VERSION "Version"

NS_ :

BS_:

BU_: ADC FR Tester

BO_ 537 FR_Obj_24: 32 FR
 SG_ SGU24_Msg_CheckSum_Can03 : 7|8@0+ (1,0) [0|255] ""  ADC
 SG_ SGU24_Msg_AliveCounter_Can03 : 11|4@0+ (1,0) [0|14] ""  ADC
 SG_ SGU24_BlockCounter_Can03 : 15|4@0+ (1,0) [0|15] ""  ADC
 SG_ SGU24_Object_ID_Can03 : 23|8@0+ (1,0) [0|255] ""  ADC
 SG_ SGU24_Object_wExist_Can03 : 28|5@0+ (0.03125,0) [0|0.96875] ""  ADC
 SG_ SGU24_Object_Type_Can03 : 31|3@0+ (1,0) [0|7] ""  ADC
 SG_ SGU24_Object_MotionPattern_Can03 : 34|3@0+ (1,0) [0|7] ""  ADC
 SG_ SGU24_Object_wObstacle_Can03 : 39|5@0+ (0.03125,0) [0|0.96875] ""  ADC
 SG_ SGU24_Object_dx_Nearest_Can03 : 44|13@0+ (0.0625,-255) [-255|254.9375] "m"  ADC
 SG_ SGU24_Object_dy_Nearest_Can03 : 59|12@0+ (0.125,-128) [-128|127.875] "m"  ADC
 SG_ SGU24_Object_DistLong_rms_Can03 : 79|16@0+ (0.001953125,0) [0|127.998046875] "m"  ADC
 SG_ SGU24_Obj_DistLat_rms_Can03 : 95|16@0+ (0.001953125,0) [0|127.998046875] "m"  ADC
 SG_ SGU24_Object_vx_Can03 : 107|12@0+ (0.0625,-128) [-128|127.9375] "m/s"  ADC
 SG_ SGU24_Object_vy_Can03 : 123|12@0+ (0.0625,-128) [-128|127.9375] "m/s"  ADC
 SG_ SGU24_Obj_VrelLong_rms_Can03 : 143|16@0+ (0.001953125,0) [0|127.998046875] "m/s"  ADC
 SG_ SGU24_Obj_Vrelat_rms_Can03 : 159|16@0+ (0.001953125,0) [0|127.998046875] "m/s"  ADC
 SG_ SGU24_Object_DetStatus_Can03 : 173|3@0+ (1,0) [0|7] ""  ADC
 SG_ SGU24_Object_ax_Can03 : 170|11@0+ (0.03125,-16) [-16|15.96875] "m/s^2"  ADC
 SG_ SGU24_Object_ay_Can03 : 191|11@0+ (0.03125,-16) [-16|15.96875] "m/s^2"  ADC
 SG_ SGU24_LifeCycles_OBJ_Can03 : 196|8@0+ (1,0) [0|255] ""  ADC
 SG_ SGU24_ObjRCS_24_Can03 : 204|10@0+ (0.125,-50) [-50|70] "dBm2"  ADC
 SG_ SGU24_Object_dx_Rear_Can03 : 210|13@0+ (0.0625,-255) [-255|254.9375] "m"  ADC
 SG_ SGU24_Object_dy_Rear_Can03 : 229|12@0+ (0.125,-128) [-128|127.875] "m"  ADC

BO_ 538 FR_Obj_25: 32 FR
 SG_ SGU25_Msg_CheckSum_Can03 : 7|8@0+ (1,0) [0|255] ""  ADC
 SG_ SGU25_Msg_AliveCounter_Can03 : 11|4@0+ (1,0) [0|14] ""  ADC
 SG_ SGU25_BlockCounter_Can03 : 15|4@0+ (1,0) [0|15] ""  ADC
 SG_ SGU25_Object_ID_Can03 : 23|8@0+ (1,0) [0|255] ""  ADC
 SG_ SGU25_Object_wExist_Can03 : 28|5@0+ (0.03125,0) [0|0.96875] ""  ADC
 SG_ SGU25_Object_Type_Can03 : 31|3@0+ (1,0) [0|7] ""  ADC
 SG_ SGU25_Object_MotionPattern_Can03 : 34|3@0+ (1,0) [0|7] ""  ADC
 SG_ SGU25_Object_wObstacle_Can03 : 39|5@0+ (0.03125,0) [0|0.96875] ""  ADC
 SG_ SGU25_Object_dx_Nearest_Can03 : 44|13@0+ (0.0625,-255) [-255|254.9375] "m"  ADC
 SG_ SGU25_Object_dy_Nearest_Can03 : 59|12@0+ (0.125,-128) [-128|127.875] "m"  ADC
 SG_ SGU25_Object_DistLong_rms_Can03 : 79|16@0+ (0.001953125,0) [0|127.998046875] "m"  ADC
 SG_ SGU25_Obj_DistLat_rms_Can03 : 95|16@0+ (0.001953125,0) [0|127.998046875] "m"  ADC
 SG_ SGU25_Object_vx_Can03 : 107|12@0+ (0.0625,-128) [-128|127.9375] "m/s"  ADC
 SG_ SGU25_Object_vy_Can03 : 123|12@0+ (0.0625,-128) [-128|127.9375] "m/s"  ADC
 SG_ SGU25_Obj_VrelLong_rms_Can03 : 143|16@0+ (0.001953125,0) [0|127.998046875] "m/s"  ADC
 SG_ SGU25_Obj_Vrelat_rms_Can03 : 159|16@0+ (0.001953125,0) [0|127.998046875] "m/s"  ADC
 SG_ SGU25_Object_DetStatus_Can03 : 173|3@0+ (1,0) [0|7] ""  ADC
 SG_ SGU25_Object_ax_Can03 : 170|11@0+ (0.03125,-16) [-16|15.96875] "m/s^2"  ADC
 SG_ SGU25_Object_ay_Can03 : 191|11@0+ (0.03125,-16) [-16|15.96875] "m/s^2"  ADC
 SG_ SGU25_LifeCycles_OBJ_Can03 : 196|8@0+ (1,0) [0|255] ""  ADC
 SG_ SGU25_ObjRCS_25_Can03 : 204|10@0+ (0.125,-50) [-50|70] "dBm2"  ADC
 SG_ SGU25_Object_dx_Rear_Can03 : 210|13@0+ (0.0625,-255) [-255|254.9375] "m"  ADC
 SG_ SGU25_Object_dy_Rear_Can03 : 229|12@0+ (0.125,-128) [-128|127.875] "m"  ADC

BO_ 539 FR_Obj_26: 32 FR
 SG_ SGU26_Msg_CheckSum_Can03 : 7|8@0+ (1,0) [0|255] ""  ADC
 SG_ SGU26_Msg_AliveCounter_Can03 : 11|4@0+ (1,0) [0|14] ""  ADC
 SG_ SGU26_BlockCounter_Can03 : 15|4@0+ (1,0) [0|15] ""  ADC
 SG_ SGU26_Object_ID_Can03 : 23|8@0+ (1,0) [0|255] ""  ADC
 SG_ SGU26_Object_wExist_Can03 : 28|5@0+ (0.03125,0) [0|0.96875] ""  ADC
 SG_ SGU26_Object_Type_Can03 : 31|3@0+ (1,0) [0|7] ""  ADC
 SG_ SGU26_Object_MotionPattern_Can03 : 34|3@0+ (1,0) [0|7] ""  ADC
 SG_ SGU26_Object_wObstacle_Can03 : 39|5@0+ (0.03125,0) [0|0.96875] ""  ADC
 SG_ SGU26_Object_dx_Nearest_Can03 : 44|13@0+ (0.0625,-255) [-255|254.9375] "m"  ADC
 SG_ SGU26_Object_dy_Nearest_Can03 : 59|12@0+ (0.125,-128) [-128|127.875] "m"  ADC
 SG_ SGU26_Object_DistLong_rms_Can03 : 79|16@0+ (0.001953125,0) [0|127.998046875] "m"  ADC
 SG_ SGU26_Obj_DistLat_rms_Can03 : 95|16@0+ (0.001953125,0) [0|127.998046875] "m"  ADC
 SG_ SGU26_Object_vx_Can03 : 107|12@0+ (0.0625,-128) [-128|127.9375] "m/s"  ADC
 SG_ SGU26_Object_vy_Can03 : 123|12@0+ (0.0625,-128) [-128|127.9375] "m/s"  ADC
 SG_ SGU26_Obj_VrelLong_rms_Can03 : 143|16@0+ (0.001953125,0) [0|127.998046875] "m/s"  ADC
 SG_ SGU26_Obj_Vrelat_rms_Can03 : 159|16@0+ (0.001953125,0) [0|127.998046875] "m/s"  ADC
 SG_ SGU26_Object_DetStatus_Can03 : 173|3@0+ (1,0) [0|7] ""  ADC
 SG_ SGU26_Object_ax_Can03 : 170|11@0+ (0.03125,-16) [-16|15.96875] "m/s^2"  ADC
 SG_ SGU26_Object_ay_Can03 : 191|11@0+ (0.03125,-16) [-16|15.96875] "m/s^2"  ADC
 SG_ SGU26_LifeCycles_OBJ_Can03 : 196|8@0+ (1,0) [0|255] ""  ADC
 SG_ SGU26_ObjRCS_26_Can03 : 204|10@0+ (0.125,-50) [-50|70] "dBm2"  ADC
 SG_ SGU26_Object_dx_Rear_Can03 : 210|13@0+ (0.0625,-255) [-255|254.9375] "m"  ADC
 SG_ SGU26_Object_dy_Rear_Can03 : 229|12@0+ (0.125,-128) [-128|127.875] "m"  ADC

BO_ 540 FR_Obj_27: 32 FR
 SG_ SGU27_Msg_CheckSum_Can03 : 7|8@0+ (1,0) [0|255] ""  ADC
 SG_ SGU27_Msg_AliveCounter_Can03 : 11|4@0+ (1,0) [0|14] ""  ADC
 SG_ SGU27_BlockCounter_Can03 : 15|4@0+ (1,0) [0|15] ""  ADC
 SG_ SGU27_Object_ID_Can03 : 23|8@0+ (1,0) [0|255] ""  ADC
 SG_ SGU27_Object_wExist_Can03 : 28|5@0+ (0.03125,0) [0|0.96875] ""  ADC
 SG_ SGU27_Object_Type_Can03 : 31|3@0+ (1,0) [0|7] ""  ADC
 SG_ SGU27_Object_MotionPattern_Can03 : 34|3@0+ (1,0) [0|7] ""  ADC
 SG_ SGU27_Object_wObstacle_Can03 : 39|5@0+ (0.03125,0) [0|0.96875] ""  ADC
 SG_ SGU27_Object_dx_Nearest_Can03 : 44|13@0+ (0.0625,-255) [-255|254.9375] "m"  ADC
 SG_ SGU27_Object_dy_Nearest_Can03 : 59|12@0+ (0.125,-128) [-128|127.875] "m"  ADC
 SG_ SGU27_Object_DistLong_rms_Can03 : 79|16@0+ (0.001953125,0) [0|127.998046875] "m"  ADC
 SG_ SGU27_Obj_DistLat_rms_Can03 : 95|16@0+ (0.001953125,0) [0|127.998046875] "m"  ADC
 SG_ SGU27_Object_vx_Can03 : 107|12@0+ (0.0625,-128) [-128|127.9375] "m/s"  ADC
 SG_ SGU27_Object_vy_Can03 : 123|12@0+ (0.0625,-128) [-128|127.9375] "m/s"  ADC
 SG_ SGU27_Obj_VrelLong_rms_Can03 : 143|16@0+ (0.001953125,0) [0|127.998046875] "m/s"  ADC
 SG_ SGU27_Obj_Vrelat_rms_Can03 : 159|16@0+ (0.001953125,0) [0|127.998046875] "m/s"  ADC
 SG_ SGU27_Object_DetStatus_Can03 : 173|3@0+ (1,0) [0|7] ""  ADC
 SG_ SGU27_Object_ax_Can03 : 170|11@0+ (0.03125,-16) [-16|15.96875] "m/s^2"  ADC
 SG_ SGU27_Object_ay_Can03 : 191|11@0+ (0.03125,-16) [-16|15.96875] "m/s^2"  ADC
 SG_ SGU27_LifeCycles_OBJ_Can03 : 196|8@0+ (1,0) [0|255] ""  ADC
 SG_ SGU27_ObjRCS_27_Can03 : 204|10@0+ (0.125,-50) [-50|70] "dBm2"  ADC
 SG_ SGU27_Object_dx_Rear_Can03 : 210|13@0+ (0.0625,-255) [-255|254.9375] "m"  ADC
 SG_ SGU27_Object_dy_Rear_Can03 : 229|12@0+ (0.125,-128) [-128|127.875] "m"  ADC

BO_ 541 FR_Obj_28: 32 FR
 SG_ SGU28_Msg_CheckSum_Can03 : 7|8@0+ (1,0) [0|255] ""  ADC
 SG_ SGU28_Msg_AliveCounter_Can03 : 11|4@0+ (1,0) [0|14] ""  ADC
 SG_ SGU28_BlockCounter_Can03 : 15|4@0+ (1,0) [0|15] ""  ADC
 SG_ SGU28_Object_ID_Can03 : 23|8@0+ (1,0) [0|255] ""  ADC
 SG_ SGU28_Object_wExist_Can03 : 28|5@0+ (0.03125,0) [0|0.96875] ""  ADC
 SG_ SGU28_Object_Type_Can03 : 31|3@0+ (1,0) [0|7] ""  ADC
 SG_ SGU28_Object_MotionPattern_Can03 : 34|3@0+ (1,0) [0|7] ""  ADC
 SG_ SGU28_Object_wObstacle_Can03 : 39|5@0+ (0.03125,0) [0|0.96875] ""  ADC
 SG_ SGU28_Object_dx_Nearest_Can03 : 44|13@0+ (0.0625,-255) [-255|254.9375] "m"  ADC
 SG_ SGU28_Object_dy_Nearest_Can03 : 59|12@0+ (0.125,-128) [-128|127.875] "m"  ADC
 SG_ SGU28_Object_DistLong_rms_Can03 : 79|16@0+ (0.001953125,0) [0|127.998046875] "m"  ADC
 SG_ SGU28_Obj_DistLat_rms_Can03 : 95|16@0+ (0.001953125,0) [0|127.998046875] "m"  ADC
 SG_ SGU28_Object_vx_Can03 : 107|12@0+ (0.0625,-128) [-128|127.9375] "m/s"  ADC
 SG_ SGU28_Object_vy_Can03 : 123|12@0+ (0.0625,-128) [-128|127.9375] "m/s"  ADC
 SG_ SGU28_Obj_VrelLong_rms_Can03 : 143|16@0+ (0.001953125,0) [0|127.998046875] "m/s"  ADC
 SG_ SGU28_Obj_Vrelat_rms_Can03 : 159|16@0+ (0.001953125,0) [0|127.998046875] "m/s"  ADC
 SG_ SGU28_Object_DetStatus_Can03 : 173|3@0+ (1,0) [0|7] ""  ADC
 SG_ SGU28_Object_ax_Can03 : 170|11@0+ (0.03125,-16) [-16|15.96875] "m/s^2"  ADC
 SG_ SGU28_Object_ay_Can03 : 191|11@0+ (0.03125,-16) [-16|15.96875] "m/s^2"  ADC
 SG_ SGU28_LifeCycles_OBJ_Can03 : 196|8@0+ (1,0) [0|255] ""  ADC
 SG_ SGU28_ObjRCS_28_Can03 : 204|10@0+ (0.125,-50) [-50|70] "dBm2"  ADC
 SG_ SGU28_Object_dx_Rear_Can03 : 210|13@0+ (0.0625,-255) [-255|254.9375] "m"  ADC
 SG_ SGU28_Object_dy_Rear_Can03 : 229|12@0+ (0.125,-128) [-128|127.875] "m"  ADC

BO_ 542 FR_Obj_29: 32 FR
 SG_ SGU29_Msg_CheckSum_Can03 : 7|8@0+ (1,0) [0|255] ""  ADC
 SG_ SGU29_Msg_AliveCounter_Can03 : 11|4@0+ (1,0) [0|14] ""  ADC
 SG_ SGU29_BlockCounter_Can03 : 15|4@0+ (1,0) [0|15] ""  ADC
 SG_ SGU29_Object_ID_Can03 : 23|8@0+ (1,0) [0|255] ""  ADC
 SG_ SGU29_Object_wExist_Can03 : 28|5@0+ (0.03125,0) [0|0.96875] ""  ADC
 SG_ SGU29_Object_Type_Can03 : 31|3@0+ (1,0) [0|7] ""  ADC
 SG_ SGU29_Object_MotionPattern_Can03 : 34|3@0+ (1,0) [0|7] ""  ADC
 SG_ SGU29_Object_wObstacle_Can03 : 39|5@0+ (0.03125,0) [0|0.96875] ""  ADC
 SG_ SGU29_Object_dx_Nearest_Can03 : 44|13@0+ (0.0625,-255) [-255|254.9375] "m"  ADC
 SG_ SGU29_Object_dy_Nearest_Can03 : 59|12@0+ (0.125,-128) [-128|127.875] "m"  ADC
 SG_ SGU29_Object_DistLong_rms_Can03 : 79|16@0+ (0.001953125,0) [0|127.998046875] "m"  ADC
 SG_ SGU29_Obj_DistLat_rms_Can03 : 95|16@0+ (0.001953125,0) [0|127.998046875] "m"  ADC
 SG_ SGU29_Object_vx_Can03 : 107|12@0+ (0.0625,-128) [-128|127.9375] "m/s"  ADC
 SG_ SGU29_Object_vy_Can03 : 123|12@0+ (0.0625,-128) [-128|127.9375] "m/s"  ADC
 SG_ SGU29_Obj_VrelLong_rms_Can03 : 143|16@0+ (0.001953125,0) [0|127.998046875] "m/s"  ADC
 SG_ SGU29_Obj_Vrelat_rms_Can03 : 159|16@0+ (0.001953125,0) [0|127.998046875] "m/s"  ADC
 SG_ SGU29_Object_DetStatus_Can03 : 173|3@0+ (1,0) [0|7] ""  ADC
 SG_ SGU29_Object_ax_Can03 : 170|11@0+ (0.03125,-16) [-16|15.96875] "m/s^2"  ADC
 SG_ SGU29_Object_ay_Can03 : 191|11@0+ (0.03125,-16) [-16|15.96875] "m/s^2"  ADC
 SG_ SGU29_LifeCycles_OBJ_Can03 : 196|8@0+ (1,0) [0|255] ""  ADC
 SG_ SGU29_ObjRCS_29_Can03 : 204|10@0+ (0.125,-50) [-50|70] "dBm2"  ADC
 SG_ SGU29_Object_dx_Rear_Can03 : 210|13@0+ (0.0625,-255) [-255|254.9375] "m"  ADC
 SG_ SGU29_Object_dy_Rear_Can03 : 229|12@0+ (0.125,-128) [-128|127.875] "m"  ADC

BO_ 543 FR_Obj_30: 32 FR
 SG_ SGU30_Msg_CheckSum_Can03 : 7|8@0+ (1,0) [0|255] ""  ADC
 SG_ SGU30_Msg_AliveCounter_Can03 : 11|4@0+ (1,0) [0|14] ""  ADC
 SG_ SGU30_BlockCounter_Can03 : 15|4@0+ (1,0) [0|15] ""  ADC
 SG_ SGU30_Object_ID_Can03 : 23|8@0+ (1,0) [0|255] ""  ADC
 SG_ SGU30_Object_wExist_Can03 : 28|5@0+ (0.03125,0) [0|0.96875] ""  ADC
 SG_ SGU30_Object_Type_Can03 : 31|3@0+ (1,0) [0|7] ""  ADC
 SG_ SGU30_Object_MotionPattern_Can03 : 34|3@0+ (1,0) [0|7] ""  ADC
 SG_ SGU30_Object_wObstacle_Can03 : 39|5@0+ (0.03125,0) [0|0.96875] ""  ADC
 SG_ SGU30_Object_dx_Nearest_Can03 : 44|13@0+ (0.0625,-255) [-255|254.9375] "m"  ADC
 SG_ SGU30_Object_dy_Nearest_Can03 : 59|12@0+ (0.125,-128) [-128|127.875] "m"  ADC
 SG_ SGU30_Object_DistLong_rms_Can03 : 79|16@0+ (0.001953125,0) [0|127.998046875] "m"  ADC
 SG_ SGU30_Obj_DistLat_rms_Can03 : 95|16@0+ (0.001953125,0) [0|127.998046875] "m"  ADC
 SG_ SGU30_Object_vx_Can03 : 107|12@0+ (0.0625,-128) [-128|127.9375] "m/s"  ADC
 SG_ SGU30_Object_vy_Can03 : 123|12@0+ (0.0625,-128) [-128|127.9375] "m/s"  ADC
 SG_ SGU30_Obj_VrelLong_rms_Can03 : 143|16@0+ (0.001953125,0) [0|127.998046875] "m/s"  ADC
 SG_ SGU30_Obj_Vrelat_rms_Can03 : 159|16@0+ (0.001953125,0) [0|127.998046875] "m/s"  ADC
 SG_ SGU30_Object_DetStatus_Can03 : 173|3@0+ (1,0) [0|7] ""  ADC
 SG_ SGU30_Object_ax_Can03 : 170|11@0+ (0.03125,-16) [-16|15.96875] "m/s^2"  ADC
 SG_ SGU30_Object_ay_Can03 : 191|11@0+ (0.03125,-16) [-16|15.96875] "m/s^2"  ADC
 SG_ SGU30_LifeCycles_OBJ_Can03 : 196|8@0+ (1,0) [0|255] ""  ADC
 SG_ SGU30_ObjRCS_30_Can03 : 204|10@0+ (0.125,-50) [-50|70] "dBm2"  ADC
 SG_ SGU30_Object_dx_Rear_Can03 : 210|13@0+ (0.0625,-255) [-255|254.9375] "m"  ADC
 SG_ SGU30_Object_dy_Rear_Can03 : 229|12@0+ (0.125,-128) [-128|127.875] "m"  ADC

BO_ 544 FR_Obj_31: 32 FR
 SG_ SGU31_Msg_CheckSum_Can03 : 7|8@0+ (1,0) [0|255] ""  ADC
 SG_ SGU31_Msg_AliveCounter_Can03 : 11|4@0+ (1,0) [0|14] ""  ADC
 SG_ SGU31_BlockCounter_Can03 : 15|4@0+ (1,0) [0|15] ""  ADC
 SG_ SGU31_Object_ID_Can03 : 23|8@0+ (1,0) [0|255] ""  ADC
 SG_ SGU31_Object_wExist_Can03 : 28|5@0+ (0.03125,0) [0|0.96875] ""  ADC
 SG_ SGU31_Object_Type_Can03 : 31|3@0+ (1,0) [0|7] ""  ADC
 SG_ SGU31_Object_MotionPattern_Can03 : 34|3@0+ (1,0) [0|7] ""  ADC
 SG_ SGU31_Object_wObstacle_Can03 : 39|5@0+ (0.03125,0) [0|0.96875] ""  ADC
 SG_ SGU31_Object_dx_Nearest_Can03 : 44|13@0+ (0.0625,-255) [-255|254.9375] "m"  ADC
 SG_ SGU31_Object_dy_Nearest_Can03 : 59|12@0+ (0.125,-128) [-128|127.875] "m"  ADC
 SG_ SGU31_Object_DistLong_rms_Can03 : 79|16@0+ (0.001953125,0) [0|127.998046875] "m"  ADC
 SG_ SGU31_Obj_DistLat_rms_Can03 : 95|16@0+ (0.001953125,0) [0|127.998046875] "m"  ADC
 SG_ SGU31_Object_vx_Can03 : 107|12@0+ (0.0625,-128) [-128|127.9375] "m/s"  ADC
 SG_ SGU31_Object_vy_Can03 : 123|12@0+ (0.0625,-128) [-128|127.9375] "m/s"  ADC
 SG_ SGU31_Obj_VrelLong_rms_Can03 : 143|16@0+ (0.001953125,0) [0|127.998046875] "m/s"  ADC
 SG_ SGU31_Obj_Vrelat_rms_Can03 : 159|16@0+ (0.001953125,0) [0|127.998046875] "m/s"  ADC
 SG_ SGU31_Object_DetStatus_Can03 : 173|3@0+ (1,0) [0|7] ""  ADC
 SG_ SGU31_Object_ax_Can03 : 170|11@0+ (0.03125,-16) [-16|15.96875] "m/s^2"  ADC
 SG_ SGU31_Object_ay_Can03 : 191|11@0+ (0.03125,-16) [-16|15.96875] "m/s^2"  ADC
 SG_ SGU31_LifeCycles_OBJ_Can03 : 196|8@0+ (1,0) [0|255] ""  ADC
 SG_ SGU31_ObjRCS_31_Can03 : 204|10@0+ (0.125,-50) [-50|70] "dBm2"  ADC
 SG_ SGU31_Object_dx_Rear_Can03 : 210|13@0+ (0.0625,-255) [-255|254.9375] "m"  ADC
 SG_ SGU31_Object_dy_Rear_Can03 : 229|12@0+ (0.125,-128) [-128|127.875] "m"  ADC

BO_ 545 FR_Obj_32: 32 FR
 SG_ SGU32_Msg_CheckSum_Can03 : 7|8@0+ (1,0) [0|255] ""  ADC
 SG_ SGU32_Msg_AliveCounter_Can03 : 11|4@0+ (1,0) [0|14] ""  ADC
 SG_ SGU32_BlockCounter_Can03 : 15|4@0+ (1,0) [0|15] ""  ADC
 SG_ SGU32_Object_ID_Can03 : 23|8@0+ (1,0) [0|255] ""  ADC
 SG_ SGU32_Object_wExist_Can03 : 28|5@0+ (0.03125,0) [0|0.96875] ""  ADC
 SG_ SGU32_Object_Type_Can03 : 31|3@0+ (1,0) [0|7] ""  ADC
 SG_ SGU32_Object_MotionPattern_Can03 : 34|3@0+ (1,0) [0|7] ""  ADC
 SG_ SGU32_Object_wObstacle_Can03 : 39|5@0+ (0.03125,0) [0|0.96875] ""  ADC
 SG_ SGU32_Object_dx_Nearest_Can03 : 44|13@0+ (0.0625,-255) [-255|254.9375] "m"  ADC
 SG_ SGU32_Object_dy_Nearest_Can03 : 59|12@0+ (0.125,-128) [-128|127.875] "m"  ADC
 SG_ SGU32_Object_DistLong_rms_Can03 : 79|16@0+ (0.001953125,0) [0|127.998046875] "m"  ADC
 SG_ SGU32_Obj_DistLat_rms_Can03 : 95|16@0+ (0.001953125,0) [0|127.998046875] "m"  ADC
 SG_ SGU32_Object_vx_Can03 : 107|12@0+ (0.0625,-128) [-128|127.9375] "m/s"  ADC
 SG_ SGU32_Object_vy_Can03 : 123|12@0+ (0.0625,-128) [-128|127.9375] "m/s"  ADC
 SG_ SGU32_Obj_VrelLong_rms_Can03 : 143|16@0+ (0.001953125,0) [0|127.998046875] "m/s"  ADC
 SG_ SGU32_Obj_Vrelat_rms_Can03 : 159|16@0+ (0.001953125,0) [0|127.998046875] "m/s"  ADC
 SG_ SGU32_Object_DetStatus_Can03 : 173|3@0+ (1,0) [0|7] ""  ADC
 SG_ SGU32_Object_ax_Can03 : 170|11@0+ (0.03125,-16) [-16|15.96875] "m/s^2"  ADC
 SG_ SGU32_Object_ay_Can03 : 191|11@0+ (0.03125,-16) [-16|15.96875] "m/s^2"  ADC
 SG_ SGU32_LifeCycles_OBJ_Can03 : 196|8@0+ (1,0) [0|255] ""  ADC
 SG_ SGU32_ObjRCS_32_Can03 : 204|10@0+ (0.125,-50) [-50|70] "dBm2"  ADC
 SG_ SGU32_Object_dx_Rear_Can03 : 210|13@0+ (0.0625,-255) [-255|254.9375] "m"  ADC
 SG_ SGU32_Object_dy_Rear_Can03 : 229|12@0+ (0.125,-128) [-128|127.875] "m"  ADC

BO_ 546 FR_RadarInfo: 32 FR
 SG_ FR_RadarInfor_Checksum_Can03 : 7|8@0+ (1,0) [0|255] ""  ADC
 SG_ FR_RadarInfor_AliveCounter_Can03 : 11|4@0+ (1,0) [0|14] ""  ADC
 SG_ mountAngleIndicator_az : 31|9@0+ (0.05,-12.8) [-12.8|12.75] "degree"  ADC
 SG_ mountAngleCurrent_az : 38|9@0+ (0.05,-12.8) [-12.8|12.75] "degree"  ADC
 SG_ mountAngleIndicator_el : 45|9@0+ (0.05,-12.8) [-12.8|12.75] "degree"  ADC
 SG_ mountAngleCurrent_el : 52|9@0+ (0.05,-12.8) [-12.8|12.75] "degree"  ADC
 SG_ malStablePosAz : 59|9@0+ (0.05,-12.8) [-12.8|12.75] "degree"  ADC
 SG_ malStablePosEl : 66|9@0+ (0.05,-12.8) [-12.8|12.75] "degree"  ADC
 SG_ AngleEMEIndicatorAz : 73|9@0+ (0.05,-12.8) [-12.8|12.75] "degree"  ADC
 SG_ AngleEMEIndicatorEl : 95|9@0+ (0.05,-12.8) [-12.8|12.75] "degree"  ADC
 SG_ FilteredPhiSpread : 102|11@0+ (0.1,-102.4) [-102.4|102.3] "m"  ADC
 SG_ highSpreadIndicator_el : 107|9@0+ (0.05,-12.8) [-12.8|12.75] "degree"  ADC
 SG_ highSpreadIndicator_az : 114|9@0+ (0.05,-12.8) [-12.8|12.75] "degree"  ADC
 SG_ elOutOfSpecCause : 129|2@0+ (1,0) [0|3] ""  ADC
 SG_ azOutOfSpecCause : 131|2@0+ (1,0) [0|3] ""  ADC
 SG_ Fault_MAL_HOR_ABS_EVENT : 132|1@0+ (1,0) [0|1] ""  ADC
 SG_ Fault_MAL_HOR_REL_EVENT : 133|1@0+ (1,0) [0|1] ""  ADC
 SG_ Fault_MAL_VER_ABS_EVENT : 134|1@0+ (1,0) [0|1] ""  ADC
 SG_ Fault_MAL_VER_REL_EVENT : 135|1@0+ (1,0) [0|1] ""  ADC
 SG_ azOutOfProfileCause : 143|8@0+ (1,0) [0|255] ""  ADC
 SG_ elOutOfProfileCause : 151|8@0+ (1,0) [0|255] ""  ADC
 SG_ FR_SW_Baseline_Can03 : 155|4@0+ (1,0) [0|15] ""  ADC
 SG_ FR_SW_ReleaseType_Can03 : 159|4@0+ (1,0) [0|15] ""  ADC
 SG_ FR_SW_MajorVersion_Can03 : 163|4@0+ (1,0) [0|15] ""  ADC
 SG_ FR_SW_MinorVersion_Can03 : 167|4@0+ (1,0) [0|15] ""  ADC
 SG_ FR_SDA_CalibrationSts_Can03 : 175|8@0+ (1,0) [0|255] ""  ADC
 SG_ FR_EOL_CalibrationSts_Can03 : 183|8@0+ (1,0) [0|255] ""  ADC
 SG_ FR_Blindness_FaultSts_Can03 : 192|1@0+ (1,0) [0|1] ""  ADC
 SG_ FR_ModulationSts_Can03 : 193|1@0+ (1,0) [0|1] ""  ADC
 SG_ FR_Misalignment_FaultSts_Can03 : 194|1@0+ (1,0) [0|1] ""  ADC
 SG_ FR_FAULT_HV_SERVICE_OOS_Can03 : 195|1@0+ (1,0) [0|1] ""  ADC
 SG_ FR_Radar_FaultSts_Can03 : 207|8@0+ (1,0) [0|31] ""  ADC
 SG_ FR_DTC_VBAT_HIGH_Can03 : 208|1@0+ (1,0) [0|1] ""  ADC
 SG_ FR_DTC_VBAT_LOW_Can03 : 209|1@0+ (1,0) [0|1] ""  ADC
 SG_ FR_DTC_HW_DEFECT_Can03 : 210|1@0+ (1,0) [0|1] ""  ADC
 SG_ FR_DTC_MRR_BLIND_Can03 : 212|1@0+ (1,0) [0|1] ""  ADC
 SG_ FR_DTC_MRR_MISALIGNED_Can03 : 213|1@0+ (1,0) [0|1] ""  ADC
 SG_ FR_DTC_VMC_FAILURE_Can03 : 214|1@0+ (1,0) [0|1] ""  ADC
 SG_ FR_DTC_DSP_FAILURE_Can03 : 215|1@0+ (1,0) [0|1] ""  ADC
 SG_ FR_DTC_RADAR_SIDE_MISMATCH_Can03 : 217|1@0+ (1,0) [0|1] ""  ADC
 SG_ FR_DTC_ALIGNMENT_NOT_DONE_Can03 : 218|1@0+ (1,0) [0|1] ""  ADC
 SG_ FR_DTC_PCAN_BUSOFF_Can03 : 219|1@0+ (1,0) [0|1] ""  ADC
 SG_ FR_DTC_LOST_COMM_EPS_Can03 : 222|1@0+ (1,0) [0|1] ""  ADC
 SG_ FR_DTC_INVALID_DATA_EPS_Can03 : 223|1@0+ (1,0) [0|1] ""  ADC
 SG_ FR_DTC_LOST_COMM_BCS_Can03 : 224|1@0+ (1,0) [0|1] ""  ADC
 SG_ FR_DTC_INVALID_DATA_BCS_Can03 : 225|1@0+ (1,0) [0|1] ""  ADC
 SG_ FR_DTC_LOST_COMM_CCU_Can03 : 226|1@0+ (1,0) [0|1] ""  ADC
 SG_ FR_DTC_INVALID_DATA_CCU_Can03 : 227|1@0+ (1,0) [0|1] ""  ADC
 SG_ FR_DTC_LOST_COMM_SOC_Can03 : 230|1@0+ (1,0) [0|1] ""  ADC
 SG_ FR_DTC_INVALID_DATA_SOC_Can03 : 231|1@0+ (1,0) [0|1] ""  ADC
 SG_ FR_DTC_ADC_TIME_SYNC_FAIL_Can03 : 232|1@0+ (1,0) [0|1] ""  ADC

BO_ 616 ADC_SOC_Time: 64 ADC
 SG_ UMM_UsageModeSt : 26|3@0+ (1,0) [0|7] ""  FR
 SG_ Time_Year : 343|8@0+ (1,2000) [2000|2255] "y"  FR
 SG_ Time_Month : 351|4@0+ (1,0) [1|12] "m"  FR
 SG_ Time_Hour : 358|5@0+ (1,0) [0|23] "h"  FR
 SG_ Time_Day : 347|5@0+ (1,0) [1|31] "d"  FR
 SG_ Time_Min : 353|6@0+ (1,0) [0|59] "min"  FR
 SG_ Time_Sec : 363|6@0+ (1,0) [0|59] "s"  FR

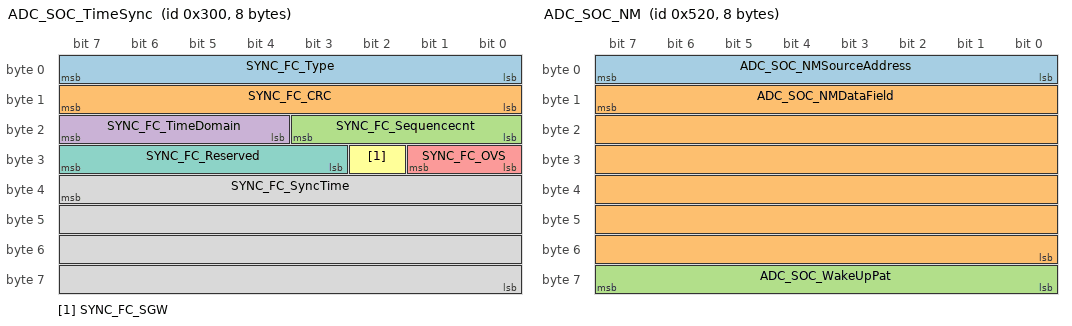
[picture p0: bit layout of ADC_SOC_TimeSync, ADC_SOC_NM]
BO_ 768 ADC_SOC_TimeSync: 8 ADC
 SG_ SYNC_FC_Type : 7|8@0+ (1,0) [0|255] ""  FR
 SG_ SYNC_FC_CRC : 15|8@0+ (1,0) [0|255] ""  FR
 SG_ SYNC_FC_Sequencecnt : 19|4@0+ (1,0) [0|15] ""  FR
 SG_ SYNC_FC_TimeDomain : 23|4@0+ (1,0) [0|15] ""  FR
 SG_ SYNC_FC_OVS : 25|2@0+ (1,0) [0|3] ""  FR
 SG_ SYNC_FC_SGW : 26|1@0+ (1,0) [0|1] ""  FR
 SG_ SYNC_FC_Reserved : 31|5@0+ (1,0) [0|31] ""  FR
 SG_ SYNC_FC_SyncTime : 39|32@0+ (1,0) [0|4294967295] ""  FR

BO_ 1238 FR_DiagCode: 64 FR
    SG_ FR_DTCCode : 7|512@0+ (1,0) [0|0] "" ADC

BO_ 1312 ADC_SOC_NM: 8 ADC
 SG_ ADC_SOC_NMSourceAddress : 7|8@0+ (1,0) [0|255] ""  FR
 SG_ ADC_SOC_NMDataField : 15|48@0+ (1,0) [0|255] ""  FR
 SG_ ADC_SOC_WakeUpPat : 63|8@0+ (1,0) [0|255] ""  FR

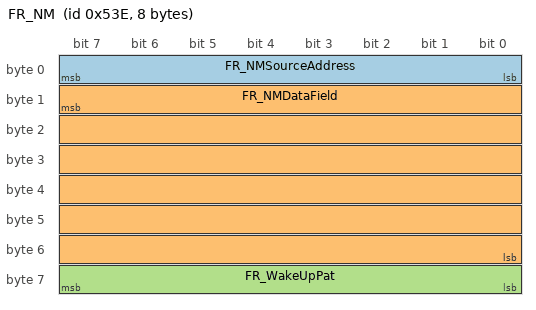
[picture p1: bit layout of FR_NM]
BO_ 1342 FR_NM: 8 FR
 SG_ FR_NMSourceAddress : 7|8@0+ (1,0) [0|255] ""  ADC
 SG_ FR_NMDataField : 15|48@0+ (1,0) [0|255] ""  ADC
 SG_ FR_WakeUpPat : 63|8@0+ (1,0) [0|255] ""  ADC

BO_ 1854 FR_Phys_Diag_Rx: 64 ADC
 SG_ FR_Diag_Request : 7|512@0+ (1,0) [0|18446744073709551615] "" Vector__XXX

BO_ 1982 FR_Diag_Tx: 64 FR
 SG_ FR_Diag_Response : 7|512@0+ (1,0) [0|18446744073709551615] "" ADC

BO_ 2015 Func_Diag_Rx: 64 ADC
 SG_ Func_Diag_Request : 7|512@0+ (1,0) [0|18446744073709551615] "" Vector__XXX

CM_ SG_ 537 SGU24_Msg_CheckSum_Can03 "E2E Profile Variant 1A CRC";
CM_ SG_ 537 SGU24_Msg_AliveCounter_Can03 "E2E Profile Variant 1A Counter";
CM_ SG_ 537 SGU24_BlockCounter_Can03 "Block counter for every messages";
CM_ SG_ 537 SGU24_Object_ID_Can03 "ID is an identifier number that allows for tracking of persistent objects over time";
CM_ SG_ 537 SGU24_Object_wExist_Can03 "Existence probability of the object";
CM_ SG_ 537 SGU24_Object_Type_Can03 "To indicate the estimated type of Object";
CM_ SG_ 537 SGU24_Object_MotionPattern_Can03 "Motion type of object";
CM_ SG_ 537 SGU24_Object_wObstacle_Can03 "The probability of an object being an obstacle";
CM_ SG_ 537 SGU24_Object_dx_Nearest_Can03 "Position of target object in x-direction [m]";
CM_ SG_ 537 SGU24_Object_dy_Nearest_Can03 "Nearest position of target object in y-direction [m]";
CM_ SG_ 537 SGU24_Object_DistLong_rms_Can03 "Standard deviation of longitudinal distance";
CM_ SG_ 537 SGU24_Obj_DistLat_rms_Can03 "Standard deviation of lateral distance";
CM_ SG_ 537 SGU24_Object_vx_Can03 "Relative target object velocity in x-direction [m/s]";
CM_ SG_ 537 SGU24_Object_vy_Can03 "Relative target object velocity in y-direction [m/s]";
CM_ SG_ 537 SGU24_Obj_VrelLong_rms_Can03 "Standard deviation of longitudinal relative velocity";
CM_ SG_ 537 SGU24_Obj_Vrelat_rms_Can03 "Standard deviation of lateral relative velocity";
CM_ SG_ 537 SGU24_Object_DetStatus_Can03 "Detection Staus Of Object";
CM_ SG_ 537 SGU24_Object_ax_Can03 "Relative target object acceleration in x-direction, in the vehicle coordinatesystem";
CM_ SG_ 537 SGU24_Object_ay_Can03 "Relative target object acceleration in y-direction, in the vehicle coordinate system";
CM_ SG_ 537 SGU24_LifeCycles_OBJ_Can03 "-";
CM_ SG_ 537 SGU24_ObjRCS_24_Can03 "Radar Cross Section (RCS) estimation";
CM_ SG_ 537 SGU24_Object_dx_Rear_Can03 "Position of target object rear bumper in x-direction [m]";
CM_ SG_ 537 SGU24_Object_dy_Rear_Can03 "Position of target object rear bumper in y-direction [m]";
CM_ SG_ 538 SGU25_Msg_CheckSum_Can03 "E2E Profile Variant 1A CRC";
CM_ SG_ 538 SGU25_Msg_AliveCounter_Can03 "E2E Profile Variant 1A Counter";
CM_ SG_ 538 SGU25_BlockCounter_Can03 "Block counter for every messages";
CM_ SG_ 538 SGU25_Object_ID_Can03 "ID is an identifier number that allows for tracking of persistent objects over time";
CM_ SG_ 538 SGU25_Object_wExist_Can03 "Existence probability of the object";
CM_ SG_ 538 SGU25_Object_Type_Can03 "To indicate the estimated type of Object";
CM_ SG_ 538 SGU25_Object_MotionPattern_Can03 "Motion type of object";
CM_ SG_ 538 SGU25_Object_wObstacle_Can03 "The probability of an object being an obstacle";
CM_ SG_ 538 SGU25_Object_dx_Nearest_Can03 "Position of target object in x-direction [m]";
CM_ SG_ 538 SGU25_Object_dy_Nearest_Can03 "Nearest position of target object in y-direction [m]";
CM_ SG_ 538 SGU25_Object_DistLong_rms_Can03 "Standard deviation of longitudinal distance";
CM_ SG_ 538 SGU25_Obj_DistLat_rms_Can03 "Standard deviation of lateral distance";
CM_ SG_ 538 SGU25_Object_vx_Can03 "Relative target object velocity in x-direction [m/s]";
CM_ SG_ 538 SGU25_Object_vy_Can03 "Relative target object velocity in y-direction [m/s]";
CM_ SG_ 538 SGU25_Obj_VrelLong_rms_Can03 "Standard deviation of longitudinal relative velocity";
CM_ SG_ 538 SGU25_Obj_Vrelat_rms_Can03 "Standard deviation of lateral relative velocity";
CM_ SG_ 538 SGU25_Object_DetStatus_Can03 "Detection Staus Of Object";
CM_ SG_ 538 SGU25_Object_ax_Can03 "Relative target object acceleration in x-direction, in the vehicle coordinatesystem";
CM_ SG_ 538 SGU25_Object_ay_Can03 "Relative target object acceleration in y-direction, in the vehicle coordinate system";
CM_ SG_ 538 SGU25_LifeCycles_OBJ_Can03 "-";
CM_ SG_ 538 SGU25_ObjRCS_25_Can03 "Radar Cross Section (RCS) estimation";
CM_ SG_ 538 SGU25_Object_dx_Rear_Can03 "Position of target object rear bumper in x-direction [m]";
CM_ SG_ 538 SGU25_Object_dy_Rear_Can03 "Position of target object rear bumper in y-direction [m]";
CM_ SG_ 539 SGU26_Msg_CheckSum_Can03 "E2E Profile Variant 1A CRC";
CM_ SG_ 539 SGU26_Msg_AliveCounter_Can03 "E2E Profile Variant 1A Counter";
CM_ SG_ 539 SGU26_BlockCounter_Can03 "Block counter for every messages";
CM_ SG_ 539 SGU26_Object_ID_Can03 "ID is an identifier number that allows for tracking of persistent objects over time";
CM_ SG_ 539 SGU26_Object_wExist_Can03 "Existence probability of the object";
CM_ SG_ 539 SGU26_Object_Type_Can03 "To indicate the estimated type of Object";
CM_ SG_ 539 SGU26_Object_MotionPattern_Can03 "Motion type of object";
CM_ SG_ 539 SGU26_Object_wObstacle_Can03 "The probability of an object being an obstacle";
CM_ SG_ 539 SGU26_Object_dx_Nearest_Can03 "Position of target object in x-direction [m]";
CM_ SG_ 539 SGU26_Object_dy_Nearest_Can03 "Nearest position of target object in y-direction [m]";
CM_ SG_ 539 SGU26_Object_DistLong_rms_Can03 "Standard deviation of longitudinal distance";
CM_ SG_ 539 SGU26_Obj_DistLat_rms_Can03 "Standard deviation of lateral distance";
CM_ SG_ 539 SGU26_Object_vx_Can03 "Relative target object velocity in x-direction [m/s]";
CM_ SG_ 539 SGU26_Object_vy_Can03 "Relative target object velocity in y-direction [m/s]";
CM_ SG_ 539 SGU26_Obj_VrelLong_rms_Can03 "Standard deviation of longitudinal relative velocity";
CM_ SG_ 539 SGU26_Obj_Vrelat_rms_Can03 "Standard deviation of lateral relative velocity";
CM_ SG_ 539 SGU26_Object_DetStatus_Can03 "Detection Staus Of Object";
CM_ SG_ 539 SGU26_Object_ax_Can03 "Relative target object acceleration in x-direction, in the vehicle coordinatesystem";
CM_ SG_ 539 SGU26_Object_ay_Can03 "Relative target object acceleration in y-direction, in the vehicle coordinate system";
CM_ SG_ 539 SGU26_LifeCycles_OBJ_Can03 "-";
CM_ SG_ 539 SGU26_ObjRCS_26_Can03 "Radar Cross Section (RCS) estimation";
CM_ SG_ 539 SGU26_Object_dx_Rear_Can03 "Position of target object rear bumper in x-direction [m]";
CM_ SG_ 539 SGU26_Object_dy_Rear_Can03 "Position of target object rear bumper in y-direction [m]";
CM_ SG_ 540 SGU27_Msg_CheckSum_Can03 "E2E Profile Variant 1A CRC";
CM_ SG_ 540 SGU27_Msg_AliveCounter_Can03 "E2E Profile Variant 1A Counter";
CM_ SG_ 540 SGU27_BlockCounter_Can03 "Block counter for every messages";
CM_ SG_ 540 SGU27_Object_ID_Can03 "ID is an identifier number that allows for tracking of persistent objects over time";
CM_ SG_ 540 SGU27_Object_wExist_Can03 "Existence probability of the object";
CM_ SG_ 540 SGU27_Object_Type_Can03 "To indicate the estimated type of Object";
CM_ SG_ 540 SGU27_Object_MotionPattern_Can03 "Motion type of object";
CM_ SG_ 540 SGU27_Object_wObstacle_Can03 "The probability of an object being an obstacle";
CM_ SG_ 540 SGU27_Object_dx_Nearest_Can03 "Position of target object in x-direction [m]";
CM_ SG_ 540 SGU27_Object_dy_Nearest_Can03 "Nearest position of target object in y-direction [m]";
CM_ SG_ 540 SGU27_Object_DistLong_rms_Can03 "Standard deviation of longitudinal distance";
CM_ SG_ 540 SGU27_Obj_DistLat_rms_Can03 "Standard deviation of lateral distance";
CM_ SG_ 540 SGU27_Object_vx_Can03 "Relative target object velocity in x-direction [m/s]";
CM_ SG_ 540 SGU27_Object_vy_Can03 "Relative target object velocity in y-direction [m/s]";
CM_ SG_ 540 SGU27_Obj_VrelLong_rms_Can03 "Standard deviation of longitudinal relative velocity";
CM_ SG_ 540 SGU27_Obj_Vrelat_rms_Can03 "Standard deviation of lateral relative velocity";
CM_ SG_ 540 SGU27_Object_DetStatus_Can03 "Detection Staus Of Object";
CM_ SG_ 540 SGU27_Object_ax_Can03 "Relative target object acceleration in x-direction, in the vehicle coordinatesystem";
CM_ SG_ 540 SGU27_Object_ay_Can03 "Relative target object acceleration in y-direction, in the vehicle coordinate system";
CM_ SG_ 540 SGU27_LifeCycles_OBJ_Can03 "-";
CM_ SG_ 540 SGU27_ObjRCS_27_Can03 "Radar Cross Section (RCS) estimation";
CM_ SG_ 540 SGU27_Object_dx_Rear_Can03 "Position of target object rear bumper in x-direction [m]";
CM_ SG_ 540 SGU27_Object_dy_Rear_Can03 "Position of target object rear bumper in y-direction [m]";
CM_ SG_ 541 SGU28_Msg_CheckSum_Can03 "E2E Profile Variant 1A CRC";
CM_ SG_ 541 SGU28_Msg_AliveCounter_Can03 "E2E Profile Variant 1A Counter";
CM_ SG_ 541 SGU28_BlockCounter_Can03 "Block counter for every messages";
CM_ SG_ 541 SGU28_Object_ID_Can03 "ID is an identifier number that allows for tracking of persistent objects over time";
CM_ SG_ 541 SGU28_Object_wExist_Can03 "Existence probability of the object";
CM_ SG_ 541 SGU28_Object_Type_Can03 "To indicate the estimated type of Object";
CM_ SG_ 541 SGU28_Object_MotionPattern_Can03 "Motion type of object";
CM_ SG_ 541 SGU28_Object_wObstacle_Can03 "The probability of an object being an obstacle";
CM_ SG_ 541 SGU28_Object_dx_Nearest_Can03 "Position of target object in x-direction [m]";
CM_ SG_ 541 SGU28_Object_dy_Nearest_Can03 "Nearest position of target object in y-direction [m]";
CM_ SG_ 541 SGU28_Object_DistLong_rms_Can03 "Standard deviation of longitudinal distance";
CM_ SG_ 541 SGU28_Obj_DistLat_rms_Can03 "Standard deviation of lateral distance";
CM_ SG_ 541 SGU28_Object_vx_Can03 "Relative target object velocity in x-direction [m/s]";
CM_ SG_ 541 SGU28_Object_vy_Can03 "Relative target object velocity in y-direction [m/s]";
CM_ SG_ 541 SGU28_Obj_VrelLong_rms_Can03 "Standard deviation of longitudinal relative velocity";
CM_ SG_ 541 SGU28_Obj_Vrelat_rms_Can03 "Standard deviation of lateral relative velocity";
CM_ SG_ 541 SGU28_Object_DetStatus_Can03 "Detection Staus Of Object";
CM_ SG_ 541 SGU28_Object_ax_Can03 "Relative target object acceleration in x-direction, in the vehicle coordinatesystem";
CM_ SG_ 541 SGU28_Object_ay_Can03 "Relative target object acceleration in y-direction, in the vehicle coordinate system";
CM_ SG_ 541 SGU28_LifeCycles_OBJ_Can03 "-";
CM_ SG_ 541 SGU28_ObjRCS_28_Can03 "Radar Cross Section (RCS) estimation";
CM_ SG_ 541 SGU28_Object_dx_Rear_Can03 "Position of target object rear bumper in x-direction [m]";
CM_ SG_ 541 SGU28_Object_dy_Rear_Can03 "Position of target object rear bumper in y-direction [m]";
CM_ SG_ 542 SGU29_Msg_CheckSum_Can03 "E2E Profile Variant 1A CRC";
CM_ SG_ 542 SGU29_Msg_AliveCounter_Can03 "E2E Profile Variant 1A Counter";
CM_ SG_ 542 SGU29_BlockCounter_Can03 "Block counter for every messages";
CM_ SG_ 542 SGU29_Object_ID_Can03 "ID is an identifier number that allows for tracking of persistent objects over time";
CM_ SG_ 542 SGU29_Object_wExist_Can03 "Existence probability of the object";
CM_ SG_ 542 SGU29_Object_Type_Can03 "To indicate the estimated type of Object";
CM_ SG_ 542 SGU29_Object_MotionPattern_Can03 "Motion type of object";
CM_ SG_ 542 SGU29_Object_wObstacle_Can03 "The probability of an object being an obstacle";
CM_ SG_ 542 SGU29_Object_dx_Nearest_Can03 "Position of target object in x-direction [m]";
CM_ SG_ 542 SGU29_Object_dy_Nearest_Can03 "Nearest position of target object in y-direction [m]";
CM_ SG_ 542 SGU29_Object_DistLong_rms_Can03 "Standard deviation of longitudinal distance";
CM_ SG_ 542 SGU29_Obj_DistLat_rms_Can03 "Standard deviation of lateral distance";
CM_ SG_ 542 SGU29_Object_vx_Can03 "Relative target object velocity in x-direction [m/s]";
CM_ SG_ 542 SGU29_Object_vy_Can03 "Relative target object velocity in y-direction [m/s]";
CM_ SG_ 542 SGU29_Obj_VrelLong_rms_Can03 "Standard deviation of longitudinal relative velocity";
CM_ SG_ 542 SGU29_Obj_Vrelat_rms_Can03 "Standard deviation of lateral relative velocity";
CM_ SG_ 542 SGU29_Object_DetStatus_Can03 "Detection Staus Of Object";
CM_ SG_ 542 SGU29_Object_ax_Can03 "Relative target object acceleration in x-direction, in the vehicle coordinatesystem";
CM_ SG_ 542 SGU29_Object_ay_Can03 "Relative target object acceleration in y-direction, in the vehicle coordinate system";
CM_ SG_ 542 SGU29_LifeCycles_OBJ_Can03 "-";
CM_ SG_ 542 SGU29_ObjRCS_29_Can03 "Radar Cross Section (RCS) estimation";
CM_ SG_ 542 SGU29_Object_dx_Rear_Can03 "Position of target object rear bumper in x-direction [m]";
CM_ SG_ 542 SGU29_Object_dy_Rear_Can03 "Position of target object rear bumper in y-direction [m]";
CM_ SG_ 543 SGU30_Msg_CheckSum_Can03 "E2E Profile Variant 1A CRC";
CM_ SG_ 543 SGU30_Msg_AliveCounter_Can03 "E2E Profile Variant 1A Counter";
CM_ SG_ 543 SGU30_BlockCounter_Can03 "Block counter for every messages";
CM_ SG_ 543 SGU30_Object_ID_Can03 "ID is an identifier number that allows for tracking of persistent objects over time";
CM_ SG_ 543 SGU30_Object_wExist_Can03 "Existence probability of the object";
CM_ SG_ 543 SGU30_Object_Type_Can03 "To indicate the estimated type of Object";
CM_ SG_ 543 SGU30_Object_MotionPattern_Can03 "Motion type of object";
CM_ SG_ 543 SGU30_Object_wObstacle_Can03 "The probability of an object being an obstacle";
CM_ SG_ 543 SGU30_Object_dx_Nearest_Can03 "Position of target object in x-direction [m]";
CM_ SG_ 543 SGU30_Object_dy_Nearest_Can03 "Nearest position of target object in y-direction [m]";
CM_ SG_ 543 SGU30_Object_DistLong_rms_Can03 "Standard deviation of longitudinal distance";
CM_ SG_ 543 SGU30_Obj_DistLat_rms_Can03 "Standard deviation of lateral distance";
CM_ SG_ 543 SGU30_Object_vx_Can03 "Relative target object velocity in x-direction [m/s]";
CM_ SG_ 543 SGU30_Object_vy_Can03 "Relative target object velocity in y-direction [m/s]";
CM_ SG_ 543 SGU30_Obj_VrelLong_rms_Can03 "Standard deviation of longitudinal relative velocity";
CM_ SG_ 543 SGU30_Obj_Vrelat_rms_Can03 "Standard deviation of lateral relative velocity";
CM_ SG_ 543 SGU30_Object_DetStatus_Can03 "Detection Staus Of Object";
CM_ SG_ 543 SGU30_Object_ax_Can03 "Relative target object acceleration in x-direction, in the vehicle coordinatesystem";
CM_ SG_ 543 SGU30_Object_ay_Can03 "Relative target object acceleration in y-direction, in the vehicle coordinate system";
CM_ SG_ 543 SGU30_LifeCycles_OBJ_Can03 "-";
CM_ SG_ 543 SGU30_ObjRCS_30_Can03 "Radar Cross Section (RCS) estimation";
CM_ SG_ 543 SGU30_Object_dx_Rear_Can03 "Position of target object rear bumper in x-direction [m]";
CM_ SG_ 543 SGU30_Object_dy_Rear_Can03 "Position of target object rear bumper in y-direction [m]";
CM_ SG_ 544 SGU31_Msg_CheckSum_Can03 "E2E Profile Variant 1A CRC";
CM_ SG_ 544 SGU31_Msg_AliveCounter_Can03 "E2E Profile Variant 1A Counter";
CM_ SG_ 544 SGU31_BlockCounter_Can03 "Block counter for every messages";
CM_ SG_ 544 SGU31_Object_ID_Can03 "ID is an identifier number that allows for tracking of persistent objects over time";
CM_ SG_ 544 SGU31_Object_wExist_Can03 "Existence probability of the object";
CM_ SG_ 544 SGU31_Object_Type_Can03 "To indicate the estimated type of Object";
CM_ SG_ 544 SGU31_Object_MotionPattern_Can03 "Motion type of object";
CM_ SG_ 544 SGU31_Object_wObstacle_Can03 "The probability of an object being an obstacle";
CM_ SG_ 544 SGU31_Object_dx_Nearest_Can03 "Position of target object in x-direction [m]";
CM_ SG_ 544 SGU31_Object_dy_Nearest_Can03 "Nearest position of target object in y-direction [m]";
CM_ SG_ 544 SGU31_Object_DistLong_rms_Can03 "Standard deviation of longitudinal distance";
CM_ SG_ 544 SGU31_Obj_DistLat_rms_Can03 "Standard deviation of lateral distance";
CM_ SG_ 544 SGU31_Object_vx_Can03 "Relative target object velocity in x-direction [m/s]";
CM_ SG_ 544 SGU31_Object_vy_Can03 "Relative target object velocity in y-direction [m/s]";
CM_ SG_ 544 SGU31_Obj_VrelLong_rms_Can03 "Standard deviation of longitudinal relative velocity";
CM_ SG_ 544 SGU31_Obj_Vrelat_rms_Can03 "Standard deviation of lateral relative velocity";
CM_ SG_ 544 SGU31_Object_DetStatus_Can03 "Detection Staus Of Object";
CM_ SG_ 544 SGU31_Object_ax_Can03 "Relative target object acceleration in x-direction, in the vehicle coordinatesystem";
CM_ SG_ 544 SGU31_Object_ay_Can03 "Relative target object acceleration in y-direction, in the vehicle coordinate system";
CM_ SG_ 544 SGU31_LifeCycles_OBJ_Can03 "-";
CM_ SG_ 544 SGU31_ObjRCS_31_Can03 "Radar Cross Section (RCS) estimation";
CM_ SG_ 544 SGU31_Object_dx_Rear_Can03 "Position of target object rear bumper in x-direction [m]";
CM_ SG_ 544 SGU31_Object_dy_Rear_Can03 "Position of target object rear bumper in y-direction [m]";
CM_ SG_ 545 SGU32_Msg_CheckSum_Can03 "E2E Profile Variant 1A CRC";
CM_ SG_ 545 SGU32_Msg_AliveCounter_Can03 "E2E Profile Variant 1A Counter";
CM_ SG_ 545 SGU32_BlockCounter_Can03 "Block counter for every messages";
CM_ SG_ 545 SGU32_Object_ID_Can03 "ID is an identifier number that allows for tracking of persistent objects over time";
CM_ SG_ 545 SGU32_Object_wExist_Can03 "Existence probability of the object";
CM_ SG_ 545 SGU32_Object_Type_Can03 "To indicate the estimated type of Object";
CM_ SG_ 545 SGU32_Object_MotionPattern_Can03 "Motion type of object";
CM_ SG_ 545 SGU32_Object_wObstacle_Can03 "The probability of an object being an obstacle";
CM_ SG_ 545 SGU32_Object_dx_Nearest_Can03 "Position of target object in x-direction [m]";
CM_ SG_ 545 SGU32_Object_dy_Nearest_Can03 "Nearest position of target object in y-direction [m]";
CM_ SG_ 545 SGU32_Object_DistLong_rms_Can03 "Standard deviation of longitudinal distance";
CM_ SG_ 545 SGU32_Obj_DistLat_rms_Can03 "Standard deviation of lateral distance";
CM_ SG_ 545 SGU32_Object_vx_Can03 "Relative target object velocity in x-direction [m/s]";
CM_ SG_ 545 SGU32_Object_vy_Can03 "Relative target object velocity in y-direction [m/s]";
CM_ SG_ 545 SGU32_Obj_VrelLong_rms_Can03 "Standard deviation of longitudinal relative velocity";
CM_ SG_ 545 SGU32_Obj_Vrelat_rms_Can03 "Standard deviation of lateral relative velocity";
CM_ SG_ 545 SGU32_Object_DetStatus_Can03 "Detection Staus Of Object";
CM_ SG_ 545 SGU32_Object_ax_Can03 "Relative target object acceleration in x-direction, in the vehicle coordinatesystem";
CM_ SG_ 545 SGU32_Object_ay_Can03 "Relative target object acceleration in y-direction, in the vehicle coordinate system";
CM_ SG_ 545 SGU32_LifeCycles_OBJ_Can03 "-";
CM_ SG_ 545 SGU32_ObjRCS_32_Can03 "Radar Cross Section (RCS) estimation";
CM_ SG_ 545 SGU32_Object_dx_Rear_Can03 "Position of target object rear bumper in x-direction [m]";
CM_ SG_ 545 SGU32_Object_dy_Rear_Can03 "Position of target object rear bumper in y-direction [m]";
CM_ SG_ 546 FR_RadarInfor_Checksum_Can03 "E2E Profile Variant 1A CRC";
CM_ SG_ 546 FR_RadarInfor_AliveCounter_Can03 "E2E Profile Variant 1A Counter";
CM_ SG_ 546 mountAngleIndicator_az "mountAngleIndicator_az";
CM_ SG_ 546 mountAngleCurrent_az "mountAngleCurrent_az";
CM_ SG_ 546 mountAngleIndicator_el "mountAngleIndicator_el";
CM_ SG_ 546 mountAngleCurrent_el "mountAngleCurrent_el";
CM_ SG_ 546 malStablePosAz "malStablePosAz";
CM_ SG_ 546 malStablePosEl "malStablePosEl";
CM_ SG_ 546 AngleEMEIndicatorAz "AngleEMEIndicatorAz";
CM_ SG_ 546 AngleEMEIndicatorEl "AngleEMEIndicatorEl";
CM_ SG_ 546 FilteredPhiSpread "FilteredPhiSpread";
CM_ SG_ 546 highSpreadIndicator_el "highSpreadIndicator_el";
CM_ SG_ 546 highSpreadIndicator_az "highSpreadIndicator_az";
CM_ SG_ 546 elOutOfSpecCause "elOutOfSpecCause";
CM_ SG_ 546 azOutOfSpecCause "azOutOfSpecCause";
CM_ SG_ 546 Fault_MAL_HOR_ABS_EVENT "Fault_MAL_HOR_ABS_EVENT";
CM_ SG_ 546 Fault_MAL_HOR_REL_EVENT "Fault_MAL_HOR_REL_EVENT";
CM_ SG_ 546 Fault_MAL_VER_ABS_EVENT "Fault_MAL_VER_ABS_EVENT";
CM_ SG_ 546 Fault_MAL_VER_REL_EVENT "Fault_MAL_VER_REL_EVENT";
CM_ SG_ 546 azOutOfProfileCause "azOutOfProfileCause";
CM_ SG_ 546 elOutOfProfileCause "elOutOfProfileCause";
CM_ SG_ 546 FR_SW_Baseline_Can03 "Baseline of SWExample:BL09 V1.2,FR_SW_Baseline_Can03 = 9";
CM_ SG_ 546 FR_SW_ReleaseType_Can03 "ReleaseType of SWExample:BL09 V1.2,FR_SW_ReleaseType_Can03 = 0";
CM_ SG_ 546 FR_SW_MajorVersion_Can03 "Major Version of SWExample: V1.2, FR_SW_MajorVersion_Can03 = 1";
CM_ SG_ 546 FR_SW_MinorVersion_Can03 "Minor Version of SWExample:BL09 V1.2, FR_SW_MinorVersion_Can03 = 2";
CM_ SG_ 546 FR_SDA_CalibrationSts_Can03 "SDA Calibration Status";
CM_ SG_ 546 FR_EOL_CalibrationSts_Can03 "EOL Calibration Status";
CM_ SG_ 546 FR_Blindness_FaultSts_Can03 "Blindness Fault Status";
CM_ SG_ 546 FR_ModulationSts_Can03 "Modulation Status";
CM_ SG_ 546 FR_Misalignment_FaultSts_Can03 "Misalignment Fault Status";
CM_ SG_ 546 FR_FAULT_HV_SERVICE_OOS_Can03 "FAULT_HV_SERVICE_OOS Fault Status";
CM_ SG_ 546 FR_Radar_FaultSts_Can03 "Radar Fault Status";
CM_ SG_ 546 FR_DTC_VBAT_HIGH_Can03 "DTC_VBAT_HIGH";
CM_ SG_ 546 FR_DTC_VBAT_LOW_Can03 "DTC_VBAT_LOW";
CM_ SG_ 546 FR_DTC_HW_DEFECT_Can03 "DTC_HW_DEFECT";
CM_ SG_ 546 FR_DTC_MRR_BLIND_Can03 "DTC_MRR_BLIND";
CM_ SG_ 546 FR_DTC_MRR_MISALIGNED_Can03 "DTC_MRR_MISALIGNED";
CM_ SG_ 546 FR_DTC_VMC_FAILURE_Can03 "DTC_VMC_FAILURE";
CM_ SG_ 546 FR_DTC_DSP_FAILURE_Can03 "DTC_DSP_FAILURE";
CM_ SG_ 546 FR_DTC_RADAR_SIDE_MISMATCH_Can03 "DTC_RADAR_SIDE_MISMATCH";
CM_ SG_ 546 FR_DTC_ALIGNMENT_NOT_DONE_Can03 "DTC_ALIGNMENT_NOT_DONE";
CM_ SG_ 546 FR_DTC_PCAN_BUSOFF_Can03 "DTC_PCAN_BUSOFF";
CM_ SG_ 546 FR_DTC_LOST_COMM_EPS_Can03 "DTC_LOST_COMM_EPS";
CM_ SG_ 546 FR_DTC_INVALID_DATA_EPS_Can03 "DTC_INVALID_DATA_FROM_EPS";
CM_ SG_ 546 FR_DTC_LOST_COMM_BCS_Can03 "DTC_LOST_COMM_BCS";
CM_ SG_ 546 FR_DTC_INVALID_DATA_BCS_Can03 "DTC_INVALID_DATA_FROM_BCS";
CM_ SG_ 546 FR_DTC_LOST_COMM_CCU_Can03 "DTC_LOST_COMM_CCU";
CM_ SG_ 546 FR_DTC_INVALID_DATA_CCU_Can03 "DTC_INVALID_DATA_FROM_CCU";
CM_ SG_ 546 FR_DTC_LOST_COMM_SOC_Can03 "DTC_LOST_COMM_SOC";
CM_ SG_ 546 FR_DTC_INVALID_DATA_SOC_Can03 "DTC_INVALID_DATA_FROM_SOC";
CM_ SG_ 546 FR_DTC_ADC_TIME_SYNC_FAIL_Can03 "DTC_ADC_TIME_SYNC_FAIL";
CM_ SG_ 616 UMM_UsageModeSt "Usage mode state";
CM_ SG_ 616 Time_Year "Year number";
CM_ SG_ 616 Time_Month "Month number";
CM_ SG_ 616 Time_Hour "Hour number";
CM_ SG_ 616 Time_Day "Day number";
CM_ SG_ 616 Time_Min "Minute number";
CM_ SG_ 616 Time_Sec "Second number";
CM_ SG_ 768 SYNC_FC_Type "Type=0x20:TsyncType=0x28:Tsync FUP";
CM_ SG_ 768 SYNC_FC_CRC "CRC";
CM_ SG_ 768 SYNC_FC_Sequencecnt "Sequence counter";
CM_ SG_ 768 SYNC_FC_TimeDomain "Time Domain";
CM_ SG_ 768 SYNC_FC_OVS "In FUP PDUOVS=Overflow of seconds";
CM_ SG_ 768 SYNC_FC_SGW "In FUP PDUSyncToGTM=0SyncToSubDomain=1";
CM_ SG_ 768 SYNC_FC_Reserved "In FUP PDUReserved default=0";
CM_ SG_ 768 SYNC_FC_SyncTime "Tsync:SyncTimeSec=32bit LSB of the 48 bits seconds part timeTsync FUP:Sync TimeNSec=32 bit value in nanosconds";
CM_ SG_ 1312 ADC_SOC_NMSourceAddress "NM source address ";
CM_ SG_ 1312 ADC_SOC_NMDataField "NM data field ";
CM_ SG_ 1312 ADC_SOC_WakeUpPat "Wake-up pattern wake-up ";
CM_ SG_ 1342 FR_NMSourceAddress "NM source address ";
CM_ SG_ 1342 FR_NMDataField "NM data field ";
CM_ SG_ 1342 FR_WakeUpPat "Wake-up pattern wake-up ";
CM_ SG_ 1854 FR_Diag_Request "Diagnostic physical request";
CM_ SG_ 1982 FR_Diag_Response "Diagnostic response";
CM_ SG_ 2015 Func_Diag_Request "Diagnostic functional request";
BA_DEF_ BO_  "GenMsgCycleTime" INT 0 65535;
BA_DEF_ BO_  "GenMsgCycleTimeFast" INT 0 65535;
BA_DEF_ BO_  "GenMsgILSupport" ENUM  "No","Yes";
BA_DEF_ BO_  "GenMsgSendType" ENUM  "Cyclic","Event","CE","NotUsed","NotUsed","NotUsed","NotUsed","NotUsed","NoMsgSendType","IfActive","IfActiveWithRepetition","CyclicAndSpontanX";
BA_DEF_ BO_  "MsgType" ENUM  "Normal","NM","Diag","vector_leerstring";
BA_DEF_ BO_  "NmAsrMessage" ENUM  "No","Yes";
BA_DEF_ BO_  "VFrameFormat" ENUM  "StandardCAN","ExtendedCAN","reserved","reserved","reserved","reserved","reserved","reserved","reserved","reserved","reserved","reserved","reserved","reserved","StandardCAN_FD","ExtendedCAN_FD";
BA_DEF_ SG_  "GenSigInactiveValue" INT 0 2147483647;
BA_DEF_ SG_  "GenSigSendType" ENUM  "Cyclic","OnWrite","OnWriteWithRepetition","OnChange","OnChangeWithRepetition","IfActive","IfActiveWithRepetition","NoSigSendType","CyclicAndSpontanX","NotUsed","Event","CE";
BA_DEF_ SG_  "GenSigStartValue" INT 0 2147483647;
BA_DEF_ SG_  "Internal_type" ENUM  "*","UB","UW","UL","SB","SW","SL";
BA_DEF_ SG_  "IsCrcSignal" ENUM  "No","Yes";
BA_DEF_ SG_  "IsMonitor" ENUM  "*","Monitor";
BA_DEF_ SG_  "Remark" STRING ;
BA_DEF_ SG_  "SigInvalidSetFlag" ENUM  "*","Yes";
BA_DEF_ SG_  "UnitConversionFactor" FLOAT -100 100;
BA_DEF_ BO_  "CANFD_BRS" ENUM  "0","1";
BA_DEF_ SG_  "EventCommandSignal" ENUM  "No","Yes";
BA_DEF_ SG_  "GatewayedSignals" ENUM  "No","Yes";
BA_DEF_ SG_  "GenSigInvalidValue" HEX 0 0;
BA_DEF_ SG_  "GenSigTimeoutValue" HEX 0 0;
BA_DEF_DEF_  "GenMsgCycleTime" 0;
BA_DEF_DEF_  "GenMsgCycleTimeFast" 0;
BA_DEF_DEF_  "GenMsgILSupport" "Yes";
BA_DEF_DEF_  "GenMsgSendType" "Cyclic";
BA_DEF_DEF_  "GenSigInactiveValue" 0;
BA_DEF_DEF_  "GenSigSendType" "Cyclic";
BA_DEF_DEF_  "GenSigStartValue" 0;
BA_DEF_DEF_  "Internal_type" "*";
BA_DEF_DEF_  "IsCrcSignal" "No";
BA_DEF_DEF_  "IsMonitor" "*";
BA_DEF_DEF_  "MsgType" "";
BA_DEF_DEF_  "NmAsrMessage" "No";
BA_DEF_DEF_  "Remark" "";
BA_DEF_DEF_  "SigInvalidSetFlag" "*";
BA_DEF_DEF_  "UnitConversionFactor" 1;
BA_DEF_DEF_  "VFrameFormat" "StandardCAN";
BA_ "CANFD_BRS" BO_ 1312 1;
BA_ "CANFD_BRS" BO_ 1342 1;
BA_ "CANFD_BRS" BO_ 1854 1;
BA_ "CANFD_BRS" BO_ 1982 1;
BA_ "CANFD_BRS" BO_ 2015 1;
BA_ "CANFD_BRS" BO_ 537 1;
BA_ "CANFD_BRS" BO_ 538 1;
BA_ "CANFD_BRS" BO_ 539 1;
BA_ "CANFD_BRS" BO_ 540 1;
BA_ "CANFD_BRS" BO_ 541 1;
BA_ "CANFD_BRS" BO_ 542 1;
BA_ "CANFD_BRS" BO_ 543 1;
BA_ "CANFD_BRS" BO_ 544 1;
BA_ "CANFD_BRS" BO_ 545 1;
BA_ "CANFD_BRS" BO_ 546 1;
BA_ "CANFD_BRS" BO_ 616 1;
BA_ "CANFD_BRS" BO_ 768 1;
BA_ "GenMsgCycleTime" BO_ 1312 200;
BA_ "GenMsgCycleTime" BO_ 1342 200;
BA_ "GenMsgCycleTime" BO_ 546 50;
BA_ "GenMsgCycleTime" BO_ 616 20;
BA_ "GenMsgCycleTime" BO_ 768 500;
BA_ "GenMsgILSupport" BO_ 1238 0;
BA_ "GenMsgILSupport" BO_ 1342 0;
BA_ "GenMsgILSupport" BO_ 1854 0;
BA_ "GenMsgILSupport" BO_ 1982 0;
BA_ "GenMsgILSupport" BO_ 2015 0;
BA_ "GenMsgILSupport" BO_ 768 0;
BA_ "GenMsgSendType" BO_ 1238 8;
BA_ "GenMsgSendType" BO_ 1854 1;
BA_ "GenMsgSendType" BO_ 1982 1;
BA_ "GenMsgSendType" BO_ 2015 1;
BA_ "GenMsgSendType" BO_ 537 1;
BA_ "GenMsgSendType" BO_ 538 1;
BA_ "GenMsgSendType" BO_ 539 1;
BA_ "GenMsgSendType" BO_ 540 1;
BA_ "GenMsgSendType" BO_ 541 1;
BA_ "GenMsgSendType" BO_ 542 1;
BA_ "GenMsgSendType" BO_ 543 1;
BA_ "GenMsgSendType" BO_ 544 1;
BA_ "GenMsgSendType" BO_ 545 1;
BA_ "MsgType" BO_ 1238 0;
BA_ "MsgType" BO_ 1312 0;
BA_ "MsgType" BO_ 1342 0;
BA_ "MsgType" BO_ 1854 0;
BA_ "MsgType" BO_ 1982 0;
BA_ "MsgType" BO_ 2015 0;
BA_ "MsgType" BO_ 537 0;
BA_ "MsgType" BO_ 538 0;
BA_ "MsgType" BO_ 539 0;
BA_ "MsgType" BO_ 540 0;
BA_ "MsgType" BO_ 541 0;
BA_ "MsgType" BO_ 542 0;
BA_ "MsgType" BO_ 543 0;
BA_ "MsgType" BO_ 544 0;
BA_ "MsgType" BO_ 545 0;
BA_ "MsgType" BO_ 546 0;
BA_ "MsgType" BO_ 616 0;
BA_ "MsgType" BO_ 768 0;
BA_ "NmAsrMessage" BO_ 1312 1;
BA_ "NmAsrMessage" BO_ 1342 1;
BA_ "EventCommandSignal" SG_ 1312 ADC_SOC_NMDataField 0;
BA_ "GatewayedSignals" SG_ 1312 ADC_SOC_NMDataField 0;
BA_ "GenSigInvalidValue" SG_ 1312 ADC_SOC_NMDataField 0;
BA_ "GenSigSendType" SG_ 1312 ADC_SOC_NMDataField 1;
BA_ "GenSigTimeoutValue" SG_ 1312 ADC_SOC_NMDataField 0;
BA_ "EventCommandSignal" SG_ 1312 ADC_SOC_NMSourceAddress 0;
BA_ "GatewayedSignals" SG_ 1312 ADC_SOC_NMSourceAddress 0;
BA_ "GenSigInvalidValue" SG_ 1312 ADC_SOC_NMSourceAddress 0;
BA_ "GenSigSendType" SG_ 1312 ADC_SOC_NMSourceAddress 1;
BA_ "GenSigStartValue" SG_ 1312 ADC_SOC_NMSourceAddress 32;
BA_ "GenSigTimeoutValue" SG_ 1312 ADC_SOC_NMSourceAddress 0;
BA_ "EventCommandSignal" SG_ 1312 ADC_SOC_WakeUpPat 0;
BA_ "GatewayedSignals" SG_ 1312 ADC_SOC_WakeUpPat 0;
BA_ "GenSigInvalidValue" SG_ 1312 ADC_SOC_WakeUpPat 0;
BA_ "GenSigSendType" SG_ 1312 ADC_SOC_WakeUpPat 1;
BA_ "GenSigStartValue" SG_ 1312 ADC_SOC_WakeUpPat 76;
BA_ "GenSigTimeoutValue" SG_ 1312 ADC_SOC_WakeUpPat 0;
BA_ "EventCommandSignal" SG_ 1342 FR_NMDataField 0;
BA_ "GatewayedSignals" SG_ 1342 FR_NMDataField 0;
BA_ "GenSigInvalidValue" SG_ 1342 FR_NMDataField 0;
BA_ "GenSigSendType" SG_ 1342 FR_NMDataField 1;
BA_ "GenSigTimeoutValue" SG_ 1342 FR_NMDataField 0;
BA_ "EventCommandSignal" SG_ 1342 FR_NMSourceAddress 0;
BA_ "GatewayedSignals" SG_ 1342 FR_NMSourceAddress 0;
BA_ "GenSigInvalidValue" SG_ 1342 FR_NMSourceAddress 0;
BA_ "GenSigSendType" SG_ 1342 FR_NMSourceAddress 1;
BA_ "GenSigStartValue" SG_ 1342 FR_NMSourceAddress 62;
BA_ "GenSigTimeoutValue" SG_ 1342 FR_NMSourceAddress 0;
BA_ "EventCommandSignal" SG_ 1342 FR_WakeUpPat 0;
BA_ "GatewayedSignals" SG_ 1342 FR_WakeUpPat 0;
BA_ "GenSigInvalidValue" SG_ 1342 FR_WakeUpPat 0;
BA_ "GenSigSendType" SG_ 1342 FR_WakeUpPat 1;
BA_ "GenSigStartValue" SG_ 1342 FR_WakeUpPat 76;
BA_ "GenSigTimeoutValue" SG_ 1342 FR_WakeUpPat 0;
BA_ "EventCommandSignal" SG_ 1854 FR_Diag_Request 0;
BA_ "GatewayedSignals" SG_ 1854 FR_Diag_Request 0;
BA_ "GenSigInvalidValue" SG_ 1854 FR_Diag_Request 0;
BA_ "GenSigSendType" SG_ 1854 FR_Diag_Request 1;
BA_ "GenSigTimeoutValue" SG_ 1854 FR_Diag_Request 0;
BA_ "EventCommandSignal" SG_ 1982 FR_Diag_Response 0;
BA_ "GatewayedSignals" SG_ 1982 FR_Diag_Response 0;
BA_ "GenSigInvalidValue" SG_ 1982 FR_Diag_Response 0;
BA_ "GenSigSendType" SG_ 1982 FR_Diag_Response 10;
BA_ "GenSigTimeoutValue" SG_ 1982 FR_Diag_Response 0;
BA_ "EventCommandSignal" SG_ 2015 Func_Diag_Request 0;
BA_ "GatewayedSignals" SG_ 2015 Func_Diag_Request 0;
BA_ "GenSigInvalidValue" SG_ 2015 Func_Diag_Request 0;
BA_ "GenSigSendType" SG_ 2015 Func_Diag_Request 1;
BA_ "GenSigTimeoutValue" SG_ 2015 Func_Diag_Request 0;
BA_ "EventCommandSignal" SG_ 537 SGU24_BlockCounter_Can03 0;
BA_ "GatewayedSignals" SG_ 537 SGU24_BlockCounter_Can03 0;
BA_ "GenSigInvalidValue" SG_ 537 SGU24_BlockCounter_Can03 0;
BA_ "GenSigSendType" SG_ 537 SGU24_BlockCounter_Can03 10;
BA_ "GenSigTimeoutValue" SG_ 537 SGU24_BlockCounter_Can03 0;
BA_ "EventCommandSignal" SG_ 537 SGU24_LifeCycles_OBJ_Can03 0;
BA_ "GatewayedSignals" SG_ 537 SGU24_LifeCycles_OBJ_Can03 0;
BA_ "GenSigInvalidValue" SG_ 537 SGU24_LifeCycles_OBJ_Can03 0;
BA_ "GenSigSendType" SG_ 537 SGU24_LifeCycles_OBJ_Can03 10;
BA_ "GenSigTimeoutValue" SG_ 537 SGU24_LifeCycles_OBJ_Can03 0;
BA_ "EventCommandSignal" SG_ 537 SGU24_Msg_AliveCounter_Can03 0;
BA_ "GatewayedSignals" SG_ 537 SGU24_Msg_AliveCounter_Can03 0;
BA_ "GenSigInvalidValue" SG_ 537 SGU24_Msg_AliveCounter_Can03 0;
BA_ "GenSigSendType" SG_ 537 SGU24_Msg_AliveCounter_Can03 10;
BA_ "GenSigTimeoutValue" SG_ 537 SGU24_Msg_AliveCounter_Can03 0;
BA_ "EventCommandSignal" SG_ 537 SGU24_Msg_CheckSum_Can03 0;
BA_ "GatewayedSignals" SG_ 537 SGU24_Msg_CheckSum_Can03 0;
BA_ "GenSigInvalidValue" SG_ 537 SGU24_Msg_CheckSum_Can03 0;
BA_ "GenSigSendType" SG_ 537 SGU24_Msg_CheckSum_Can03 10;
BA_ "GenSigTimeoutValue" SG_ 537 SGU24_Msg_CheckSum_Can03 0;
BA_ "IsCrcSignal" SG_ 537 SGU24_Msg_CheckSum_Can03 1;
BA_ "EventCommandSignal" SG_ 537 SGU24_ObjRCS_24_Can03 0;
BA_ "GatewayedSignals" SG_ 537 SGU24_ObjRCS_24_Can03 0;
BA_ "GenSigInvalidValue" SG_ 537 SGU24_ObjRCS_24_Can03 0;
BA_ "GenSigSendType" SG_ 537 SGU24_ObjRCS_24_Can03 10;
BA_ "GenSigTimeoutValue" SG_ 537 SGU24_ObjRCS_24_Can03 0;
BA_ "EventCommandSignal" SG_ 537 SGU24_Obj_DistLat_rms_Can03 0;
BA_ "GatewayedSignals" SG_ 537 SGU24_Obj_DistLat_rms_Can03 0;
BA_ "GenSigInvalidValue" SG_ 537 SGU24_Obj_DistLat_rms_Can03 0;
BA_ "GenSigSendType" SG_ 537 SGU24_Obj_DistLat_rms_Can03 10;
BA_ "GenSigTimeoutValue" SG_ 537 SGU24_Obj_DistLat_rms_Can03 0;
BA_ "EventCommandSignal" SG_ 537 SGU24_Obj_VrelLong_rms_Can03 0;
BA_ "GatewayedSignals" SG_ 537 SGU24_Obj_VrelLong_rms_Can03 0;
BA_ "GenSigInvalidValue" SG_ 537 SGU24_Obj_VrelLong_rms_Can03 0;
BA_ "GenSigSendType" SG_ 537 SGU24_Obj_VrelLong_rms_Can03 10;
BA_ "GenSigTimeoutValue" SG_ 537 SGU24_Obj_VrelLong_rms_Can03 0;
BA_ "EventCommandSignal" SG_ 537 SGU24_Obj_Vrelat_rms_Can03 0;
BA_ "GatewayedSignals" SG_ 537 SGU24_Obj_Vrelat_rms_Can03 0;
BA_ "GenSigInvalidValue" SG_ 537 SGU24_Obj_Vrelat_rms_Can03 0;
BA_ "GenSigSendType" SG_ 537 SGU24_Obj_Vrelat_rms_Can03 10;
BA_ "GenSigTimeoutValue" SG_ 537 SGU24_Obj_Vrelat_rms_Can03 0;
BA_ "EventCommandSignal" SG_ 537 SGU24_Object_DetStatus_Can03 0;
BA_ "GatewayedSignals" SG_ 537 SGU24_Object_DetStatus_Can03 0;
BA_ "GenSigInvalidValue" SG_ 537 SGU24_Object_DetStatus_Can03 0;
BA_ "GenSigSendType" SG_ 537 SGU24_Object_DetStatus_Can03 10;
BA_ "GenSigTimeoutValue" SG_ 537 SGU24_Object_DetStatus_Can03 0;
BA_ "EventCommandSignal" SG_ 537 SGU24_Object_DistLong_rms_Can03 0;
BA_ "GatewayedSignals" SG_ 537 SGU24_Object_DistLong_rms_Can03 0;
BA_ "GenSigInvalidValue" SG_ 537 SGU24_Object_DistLong_rms_Can03 0;
BA_ "GenSigSendType" SG_ 537 SGU24_Object_DistLong_rms_Can03 10;
BA_ "GenSigTimeoutValue" SG_ 537 SGU24_Object_DistLong_rms_Can03 0;
BA_ "EventCommandSignal" SG_ 537 SGU24_Object_ID_Can03 0;
BA_ "GatewayedSignals" SG_ 537 SGU24_Object_ID_Can03 0;
BA_ "GenSigInvalidValue" SG_ 537 SGU24_Object_ID_Can03 0;
BA_ "GenSigSendType" SG_ 537 SGU24_Object_ID_Can03 10;
BA_ "GenSigTimeoutValue" SG_ 537 SGU24_Object_ID_Can03 0;
BA_ "EventCommandSignal" SG_ 537 SGU24_Object_MotionPattern_Can03 0;
BA_ "GatewayedSignals" SG_ 537 SGU24_Object_MotionPattern_Can03 0;
BA_ "GenSigInvalidValue" SG_ 537 SGU24_Object_MotionPattern_Can03 0;
BA_ "GenSigSendType" SG_ 537 SGU24_Object_MotionPattern_Can03 10;
BA_ "GenSigTimeoutValue" SG_ 537 SGU24_Object_MotionPattern_Can03 0;
BA_ "EventCommandSignal" SG_ 537 SGU24_Object_Type_Can03 0;
BA_ "GatewayedSignals" SG_ 537 SGU24_Object_Type_Can03 0;
BA_ "GenSigInvalidValue" SG_ 537 SGU24_Object_Type_Can03 0;
BA_ "GenSigSendType" SG_ 537 SGU24_Object_Type_Can03 10;
BA_ "GenSigTimeoutValue" SG_ 537 SGU24_Object_Type_Can03 0;
BA_ "EventCommandSignal" SG_ 537 SGU24_Object_ax_Can03 0;
BA_ "GatewayedSignals" SG_ 537 SGU24_Object_ax_Can03 0;
BA_ "GenSigInvalidValue" SG_ 537 SGU24_Object_ax_Can03 0;
BA_ "GenSigSendType" SG_ 537 SGU24_Object_ax_Can03 10;
BA_ "GenSigTimeoutValue" SG_ 537 SGU24_Object_ax_Can03 0;
BA_ "EventCommandSignal" SG_ 537 SGU24_Object_ay_Can03 0;
BA_ "GatewayedSignals" SG_ 537 SGU24_Object_ay_Can03 0;
BA_ "GenSigInvalidValue" SG_ 537 SGU24_Object_ay_Can03 0;
BA_ "GenSigSendType" SG_ 537 SGU24_Object_ay_Can03 10;
BA_ "GenSigTimeoutValue" SG_ 537 SGU24_Object_ay_Can03 0;
BA_ "EventCommandSignal" SG_ 537 SGU24_Object_dx_Nearest_Can03 0;
BA_ "GatewayedSignals" SG_ 537 SGU24_Object_dx_Nearest_Can03 0;
BA_ "GenSigInvalidValue" SG_ 537 SGU24_Object_dx_Nearest_Can03 0;
BA_ "GenSigSendType" SG_ 537 SGU24_Object_dx_Nearest_Can03 1;
BA_ "GenSigTimeoutValue" SG_ 537 SGU24_Object_dx_Nearest_Can03 0;
BA_ "EventCommandSignal" SG_ 537 SGU24_Object_dx_Rear_Can03 0;
BA_ "GatewayedSignals" SG_ 537 SGU24_Object_dx_Rear_Can03 0;
BA_ "GenSigInvalidValue" SG_ 537 SGU24_Object_dx_Rear_Can03 0;
BA_ "GenSigSendType" SG_ 537 SGU24_Object_dx_Rear_Can03 10;
BA_ "GenSigTimeoutValue" SG_ 537 SGU24_Object_dx_Rear_Can03 0;
BA_ "EventCommandSignal" SG_ 537 SGU24_Object_dy_Nearest_Can03 0;
BA_ "GatewayedSignals" SG_ 537 SGU24_Object_dy_Nearest_Can03 0;
BA_ "GenSigInvalidValue" SG_ 537 SGU24_Object_dy_Nearest_Can03 0;
BA_ "GenSigSendType" SG_ 537 SGU24_Object_dy_Nearest_Can03 1;
BA_ "GenSigTimeoutValue" SG_ 537 SGU24_Object_dy_Nearest_Can03 0;
BA_ "EventCommandSignal" SG_ 537 SGU24_Object_dy_Rear_Can03 0;
BA_ "GatewayedSignals" SG_ 537 SGU24_Object_dy_Rear_Can03 0;
BA_ "GenSigInvalidValue" SG_ 537 SGU24_Object_dy_Rear_Can03 0;
BA_ "GenSigSendType" SG_ 537 SGU24_Object_dy_Rear_Can03 10;
BA_ "GenSigTimeoutValue" SG_ 537 SGU24_Object_dy_Rear_Can03 0;
BA_ "EventCommandSignal" SG_ 537 SGU24_Object_vx_Can03 0;
BA_ "GatewayedSignals" SG_ 537 SGU24_Object_vx_Can03 0;
BA_ "GenSigInvalidValue" SG_ 537 SGU24_Object_vx_Can03 0;
BA_ "GenSigSendType" SG_ 537 SGU24_Object_vx_Can03 10;
BA_ "GenSigTimeoutValue" SG_ 537 SGU24_Object_vx_Can03 0;
BA_ "EventCommandSignal" SG_ 537 SGU24_Object_vy_Can03 0;
BA_ "GatewayedSignals" SG_ 537 SGU24_Object_vy_Can03 0;
BA_ "GenSigInvalidValue" SG_ 537 SGU24_Object_vy_Can03 0;
BA_ "GenSigSendType" SG_ 537 SGU24_Object_vy_Can03 10;
BA_ "GenSigTimeoutValue" SG_ 537 SGU24_Object_vy_Can03 0;
BA_ "EventCommandSignal" SG_ 537 SGU24_Object_wExist_Can03 0;
BA_ "GatewayedSignals" SG_ 537 SGU24_Object_wExist_Can03 0;
BA_ "GenSigInvalidValue" SG_ 537 SGU24_Object_wExist_Can03 0;
BA_ "GenSigSendType" SG_ 537 SGU24_Object_wExist_Can03 10;
BA_ "GenSigTimeoutValue" SG_ 537 SGU24_Object_wExist_Can03 0;
BA_ "EventCommandSignal" SG_ 537 SGU24_Object_wObstacle_Can03 0;
BA_ "GatewayedSignals" SG_ 537 SGU24_Object_wObstacle_Can03 0;
BA_ "GenSigInvalidValue" SG_ 537 SGU24_Object_wObstacle_Can03 0;
BA_ "GenSigSendType" SG_ 537 SGU24_Object_wObstacle_Can03 10;
BA_ "GenSigTimeoutValue" SG_ 537 SGU24_Object_wObstacle_Can03 0;
BA_ "EventCommandSignal" SG_ 538 SGU25_BlockCounter_Can03 0;
BA_ "GatewayedSignals" SG_ 538 SGU25_BlockCounter_Can03 0;
BA_ "GenSigInvalidValue" SG_ 538 SGU25_BlockCounter_Can03 0;
BA_ "GenSigSendType" SG_ 538 SGU25_BlockCounter_Can03 10;
BA_ "GenSigTimeoutValue" SG_ 538 SGU25_BlockCounter_Can03 0;
BA_ "EventCommandSignal" SG_ 538 SGU25_LifeCycles_OBJ_Can03 0;
BA_ "GatewayedSignals" SG_ 538 SGU25_LifeCycles_OBJ_Can03 0;
BA_ "GenSigInvalidValue" SG_ 538 SGU25_LifeCycles_OBJ_Can03 0;
BA_ "GenSigSendType" SG_ 538 SGU25_LifeCycles_OBJ_Can03 10;
BA_ "GenSigTimeoutValue" SG_ 538 SGU25_LifeCycles_OBJ_Can03 0;
BA_ "EventCommandSignal" SG_ 538 SGU25_Msg_AliveCounter_Can03 0;
BA_ "GatewayedSignals" SG_ 538 SGU25_Msg_AliveCounter_Can03 0;
BA_ "GenSigInvalidValue" SG_ 538 SGU25_Msg_AliveCounter_Can03 0;
BA_ "GenSigSendType" SG_ 538 SGU25_Msg_AliveCounter_Can03 10;
BA_ "GenSigTimeoutValue" SG_ 538 SGU25_Msg_AliveCounter_Can03 0;
BA_ "EventCommandSignal" SG_ 538 SGU25_Msg_CheckSum_Can03 0;
BA_ "GatewayedSignals" SG_ 538 SGU25_Msg_CheckSum_Can03 0;
BA_ "GenSigInvalidValue" SG_ 538 SGU25_Msg_CheckSum_Can03 0;
BA_ "GenSigSendType" SG_ 538 SGU25_Msg_CheckSum_Can03 10;
BA_ "GenSigTimeoutValue" SG_ 538 SGU25_Msg_CheckSum_Can03 0;
BA_ "IsCrcSignal" SG_ 538 SGU25_Msg_CheckSum_Can03 1;
BA_ "EventCommandSignal" SG_ 538 SGU25_ObjRCS_25_Can03 0;
BA_ "GatewayedSignals" SG_ 538 SGU25_ObjRCS_25_Can03 0;
BA_ "GenSigInvalidValue" SG_ 538 SGU25_ObjRCS_25_Can03 0;
BA_ "GenSigSendType" SG_ 538 SGU25_ObjRCS_25_Can03 10;
BA_ "GenSigTimeoutValue" SG_ 538 SGU25_ObjRCS_25_Can03 0;
BA_ "EventCommandSignal" SG_ 538 SGU25_Obj_DistLat_rms_Can03 0;
BA_ "GatewayedSignals" SG_ 538 SGU25_Obj_DistLat_rms_Can03 0;
BA_ "GenSigInvalidValue" SG_ 538 SGU25_Obj_DistLat_rms_Can03 0;
BA_ "GenSigSendType" SG_ 538 SGU25_Obj_DistLat_rms_Can03 10;
BA_ "GenSigTimeoutValue" SG_ 538 SGU25_Obj_DistLat_rms_Can03 0;
BA_ "EventCommandSignal" SG_ 538 SGU25_Obj_VrelLong_rms_Can03 0;
BA_ "GatewayedSignals" SG_ 538 SGU25_Obj_VrelLong_rms_Can03 0;
BA_ "GenSigInvalidValue" SG_ 538 SGU25_Obj_VrelLong_rms_Can03 0;
BA_ "GenSigSendType" SG_ 538 SGU25_Obj_VrelLong_rms_Can03 10;
BA_ "GenSigTimeoutValue" SG_ 538 SGU25_Obj_VrelLong_rms_Can03 0;
BA_ "EventCommandSignal" SG_ 538 SGU25_Obj_Vrelat_rms_Can03 0;
BA_ "GatewayedSignals" SG_ 538 SGU25_Obj_Vrelat_rms_Can03 0;
BA_ "GenSigInvalidValue" SG_ 538 SGU25_Obj_Vrelat_rms_Can03 0;
BA_ "GenSigSendType" SG_ 538 SGU25_Obj_Vrelat_rms_Can03 10;
BA_ "GenSigTimeoutValue" SG_ 538 SGU25_Obj_Vrelat_rms_Can03 0;
BA_ "EventCommandSignal" SG_ 538 SGU25_Object_DetStatus_Can03 0;
BA_ "GatewayedSignals" SG_ 538 SGU25_Object_DetStatus_Can03 0;
BA_ "GenSigInvalidValue" SG_ 538 SGU25_Object_DetStatus_Can03 0;
BA_ "GenSigSendType" SG_ 538 SGU25_Object_DetStatus_Can03 10;
BA_ "GenSigTimeoutValue" SG_ 538 SGU25_Object_DetStatus_Can03 0;
BA_ "EventCommandSignal" SG_ 538 SGU25_Object_DistLong_rms_Can03 0;
BA_ "GatewayedSignals" SG_ 538 SGU25_Object_DistLong_rms_Can03 0;
BA_ "GenSigInvalidValue" SG_ 538 SGU25_Object_DistLong_rms_Can03 0;
BA_ "GenSigSendType" SG_ 538 SGU25_Object_DistLong_rms_Can03 10;
BA_ "GenSigTimeoutValue" SG_ 538 SGU25_Object_DistLong_rms_Can03 0;
BA_ "EventCommandSignal" SG_ 538 SGU25_Object_ID_Can03 0;
BA_ "GatewayedSignals" SG_ 538 SGU25_Object_ID_Can03 0;
BA_ "GenSigInvalidValue" SG_ 538 SGU25_Object_ID_Can03 0;
BA_ "GenSigSendType" SG_ 538 SGU25_Object_ID_Can03 10;
BA_ "GenSigTimeoutValue" SG_ 538 SGU25_Object_ID_Can03 0;
BA_ "EventCommandSignal" SG_ 538 SGU25_Object_MotionPattern_Can03 0;
BA_ "GatewayedSignals" SG_ 538 SGU25_Object_MotionPattern_Can03 0;
BA_ "GenSigInvalidValue" SG_ 538 SGU25_Object_MotionPattern_Can03 0;
BA_ "GenSigSendType" SG_ 538 SGU25_Object_MotionPattern_Can03 10;
BA_ "GenSigTimeoutValue" SG_ 538 SGU25_Object_MotionPattern_Can03 0;
BA_ "EventCommandSignal" SG_ 538 SGU25_Object_Type_Can03 0;
BA_ "GatewayedSignals" SG_ 538 SGU25_Object_Type_Can03 0;
BA_ "GenSigInvalidValue" SG_ 538 SGU25_Object_Type_Can03 0;
BA_ "GenSigSendType" SG_ 538 SGU25_Object_Type_Can03 10;
BA_ "GenSigTimeoutValue" SG_ 538 SGU25_Object_Type_Can03 0;
BA_ "EventCommandSignal" SG_ 538 SGU25_Object_ax_Can03 0;
BA_ "GatewayedSignals" SG_ 538 SGU25_Object_ax_Can03 0;
BA_ "GenSigInvalidValue" SG_ 538 SGU25_Object_ax_Can03 0;
BA_ "GenSigSendType" SG_ 538 SGU25_Object_ax_Can03 10;
BA_ "GenSigTimeoutValue" SG_ 538 SGU25_Object_ax_Can03 0;
BA_ "EventCommandSignal" SG_ 538 SGU25_Object_ay_Can03 0;
BA_ "GatewayedSignals" SG_ 538 SGU25_Object_ay_Can03 0;
BA_ "GenSigInvalidValue" SG_ 538 SGU25_Object_ay_Can03 0;
BA_ "GenSigSendType" SG_ 538 SGU25_Object_ay_Can03 10;
BA_ "GenSigTimeoutValue" SG_ 538 SGU25_Object_ay_Can03 0;
BA_ "EventCommandSignal" SG_ 538 SGU25_Object_dx_Nearest_Can03 0;
BA_ "GatewayedSignals" SG_ 538 SGU25_Object_dx_Nearest_Can03 0;
BA_ "GenSigInvalidValue" SG_ 538 SGU25_Object_dx_Nearest_Can03 0;
BA_ "GenSigSendType" SG_ 538 SGU25_Object_dx_Nearest_Can03 1;
BA_ "GenSigTimeoutValue" SG_ 538 SGU25_Object_dx_Nearest_Can03 0;
BA_ "EventCommandSignal" SG_ 538 SGU25_Object_dx_Rear_Can03 0;
BA_ "GatewayedSignals" SG_ 538 SGU25_Object_dx_Rear_Can03 0;
BA_ "GenSigInvalidValue" SG_ 538 SGU25_Object_dx_Rear_Can03 0;
BA_ "GenSigSendType" SG_ 538 SGU25_Object_dx_Rear_Can03 10;
BA_ "GenSigTimeoutValue" SG_ 538 SGU25_Object_dx_Rear_Can03 0;
BA_ "EventCommandSignal" SG_ 538 SGU25_Object_dy_Nearest_Can03 0;
BA_ "GatewayedSignals" SG_ 538 SGU25_Object_dy_Nearest_Can03 0;
BA_ "GenSigInvalidValue" SG_ 538 SGU25_Object_dy_Nearest_Can03 0;
BA_ "GenSigSendType" SG_ 538 SGU25_Object_dy_Nearest_Can03 1;
BA_ "GenSigTimeoutValue" SG_ 538 SGU25_Object_dy_Nearest_Can03 0;
BA_ "EventCommandSignal" SG_ 538 SGU25_Object_dy_Rear_Can03 0;
BA_ "GatewayedSignals" SG_ 538 SGU25_Object_dy_Rear_Can03 0;
BA_ "GenSigInvalidValue" SG_ 538 SGU25_Object_dy_Rear_Can03 0;
BA_ "GenSigSendType" SG_ 538 SGU25_Object_dy_Rear_Can03 10;
BA_ "GenSigTimeoutValue" SG_ 538 SGU25_Object_dy_Rear_Can03 0;
BA_ "EventCommandSignal" SG_ 538 SGU25_Object_vx_Can03 0;
BA_ "GatewayedSignals" SG_ 538 SGU25_Object_vx_Can03 0;
BA_ "GenSigInvalidValue" SG_ 538 SGU25_Object_vx_Can03 0;
BA_ "GenSigSendType" SG_ 538 SGU25_Object_vx_Can03 10;
BA_ "GenSigTimeoutValue" SG_ 538 SGU25_Object_vx_Can03 0;
BA_ "EventCommandSignal" SG_ 538 SGU25_Object_vy_Can03 0;
BA_ "GatewayedSignals" SG_ 538 SGU25_Object_vy_Can03 0;
BA_ "GenSigInvalidValue" SG_ 538 SGU25_Object_vy_Can03 0;
BA_ "GenSigSendType" SG_ 538 SGU25_Object_vy_Can03 10;
BA_ "GenSigTimeoutValue" SG_ 538 SGU25_Object_vy_Can03 0;
BA_ "EventCommandSignal" SG_ 538 SGU25_Object_wExist_Can03 0;
BA_ "GatewayedSignals" SG_ 538 SGU25_Object_wExist_Can03 0;
BA_ "GenSigInvalidValue" SG_ 538 SGU25_Object_wExist_Can03 0;
BA_ "GenSigSendType" SG_ 538 SGU25_Object_wExist_Can03 10;
BA_ "GenSigTimeoutValue" SG_ 538 SGU25_Object_wExist_Can03 0;
BA_ "EventCommandSignal" SG_ 538 SGU25_Object_wObstacle_Can03 0;
BA_ "GatewayedSignals" SG_ 538 SGU25_Object_wObstacle_Can03 0;
BA_ "GenSigInvalidValue" SG_ 538 SGU25_Object_wObstacle_Can03 0;
BA_ "GenSigSendType" SG_ 538 SGU25_Object_wObstacle_Can03 10;
BA_ "GenSigTimeoutValue" SG_ 538 SGU25_Object_wObstacle_Can03 0;
BA_ "EventCommandSignal" SG_ 539 SGU26_BlockCounter_Can03 0;
BA_ "GatewayedSignals" SG_ 539 SGU26_BlockCounter_Can03 0;
BA_ "GenSigInvalidValue" SG_ 539 SGU26_BlockCounter_Can03 0;
BA_ "GenSigSendType" SG_ 539 SGU26_BlockCounter_Can03 10;
BA_ "GenSigTimeoutValue" SG_ 539 SGU26_BlockCounter_Can03 0;
BA_ "EventCommandSignal" SG_ 539 SGU26_LifeCycles_OBJ_Can03 0;
BA_ "GatewayedSignals" SG_ 539 SGU26_LifeCycles_OBJ_Can03 0;
BA_ "GenSigInvalidValue" SG_ 539 SGU26_LifeCycles_OBJ_Can03 0;
BA_ "GenSigSendType" SG_ 539 SGU26_LifeCycles_OBJ_Can03 10;
BA_ "GenSigTimeoutValue" SG_ 539 SGU26_LifeCycles_OBJ_Can03 0;
BA_ "EventCommandSignal" SG_ 539 SGU26_Msg_AliveCounter_Can03 0;
BA_ "GatewayedSignals" SG_ 539 SGU26_Msg_AliveCounter_Can03 0;
BA_ "GenSigInvalidValue" SG_ 539 SGU26_Msg_AliveCounter_Can03 0;
BA_ "GenSigSendType" SG_ 539 SGU26_Msg_AliveCounter_Can03 10;
BA_ "GenSigTimeoutValue" SG_ 539 SGU26_Msg_AliveCounter_Can03 0;
BA_ "EventCommandSignal" SG_ 539 SGU26_Msg_CheckSum_Can03 0;
BA_ "GatewayedSignals" SG_ 539 SGU26_Msg_CheckSum_Can03 0;
BA_ "GenSigInvalidValue" SG_ 539 SGU26_Msg_CheckSum_Can03 0;
BA_ "GenSigSendType" SG_ 539 SGU26_Msg_CheckSum_Can03 10;
BA_ "GenSigTimeoutValue" SG_ 539 SGU26_Msg_CheckSum_Can03 0;
BA_ "IsCrcSignal" SG_ 539 SGU26_Msg_CheckSum_Can03 1;
BA_ "EventCommandSignal" SG_ 539 SGU26_ObjRCS_26_Can03 0;
BA_ "GatewayedSignals" SG_ 539 SGU26_ObjRCS_26_Can03 0;
BA_ "GenSigInvalidValue" SG_ 539 SGU26_ObjRCS_26_Can03 0;
BA_ "GenSigSendType" SG_ 539 SGU26_ObjRCS_26_Can03 10;
BA_ "GenSigTimeoutValue" SG_ 539 SGU26_ObjRCS_26_Can03 0;
BA_ "EventCommandSignal" SG_ 539 SGU26_Obj_DistLat_rms_Can03 0;
BA_ "GatewayedSignals" SG_ 539 SGU26_Obj_DistLat_rms_Can03 0;
BA_ "GenSigInvalidValue" SG_ 539 SGU26_Obj_DistLat_rms_Can03 0;
BA_ "GenSigSendType" SG_ 539 SGU26_Obj_DistLat_rms_Can03 10;
BA_ "GenSigTimeoutValue" SG_ 539 SGU26_Obj_DistLat_rms_Can03 0;
BA_ "EventCommandSignal" SG_ 539 SGU26_Obj_VrelLong_rms_Can03 0;
BA_ "GatewayedSignals" SG_ 539 SGU26_Obj_VrelLong_rms_Can03 0;
BA_ "GenSigInvalidValue" SG_ 539 SGU26_Obj_VrelLong_rms_Can03 0;
BA_ "GenSigSendType" SG_ 539 SGU26_Obj_VrelLong_rms_Can03 10;
BA_ "GenSigTimeoutValue" SG_ 539 SGU26_Obj_VrelLong_rms_Can03 0;
BA_ "EventCommandSignal" SG_ 539 SGU26_Obj_Vrelat_rms_Can03 0;
BA_ "GatewayedSignals" SG_ 539 SGU26_Obj_Vrelat_rms_Can03 0;
BA_ "GenSigInvalidValue" SG_ 539 SGU26_Obj_Vrelat_rms_Can03 0;
BA_ "GenSigSendType" SG_ 539 SGU26_Obj_Vrelat_rms_Can03 10;
BA_ "GenSigTimeoutValue" SG_ 539 SGU26_Obj_Vrelat_rms_Can03 0;
BA_ "EventCommandSignal" SG_ 539 SGU26_Object_DetStatus_Can03 0;
BA_ "GatewayedSignals" SG_ 539 SGU26_Object_DetStatus_Can03 0;
BA_ "GenSigInvalidValue" SG_ 539 SGU26_Object_DetStatus_Can03 0;
BA_ "GenSigSendType" SG_ 539 SGU26_Object_DetStatus_Can03 10;
BA_ "GenSigTimeoutValue" SG_ 539 SGU26_Object_DetStatus_Can03 0;
BA_ "EventCommandSignal" SG_ 539 SGU26_Object_DistLong_rms_Can03 0;
BA_ "GatewayedSignals" SG_ 539 SGU26_Object_DistLong_rms_Can03 0;
BA_ "GenSigInvalidValue" SG_ 539 SGU26_Object_DistLong_rms_Can03 0;
BA_ "GenSigSendType" SG_ 539 SGU26_Object_DistLong_rms_Can03 10;
BA_ "GenSigTimeoutValue" SG_ 539 SGU26_Object_DistLong_rms_Can03 0;
BA_ "EventCommandSignal" SG_ 539 SGU26_Object_ID_Can03 0;
BA_ "GatewayedSignals" SG_ 539 SGU26_Object_ID_Can03 0;
BA_ "GenSigInvalidValue" SG_ 539 SGU26_Object_ID_Can03 0;
BA_ "GenSigSendType" SG_ 539 SGU26_Object_ID_Can03 10;
BA_ "GenSigTimeoutValue" SG_ 539 SGU26_Object_ID_Can03 0;
BA_ "EventCommandSignal" SG_ 539 SGU26_Object_MotionPattern_Can03 0;
BA_ "GatewayedSignals" SG_ 539 SGU26_Object_MotionPattern_Can03 0;
BA_ "GenSigInvalidValue" SG_ 539 SGU26_Object_MotionPattern_Can03 0;
BA_ "GenSigSendType" SG_ 539 SGU26_Object_MotionPattern_Can03 10;
BA_ "GenSigTimeoutValue" SG_ 539 SGU26_Object_MotionPattern_Can03 0;
BA_ "EventCommandSignal" SG_ 539 SGU26_Object_Type_Can03 0;
BA_ "GatewayedSignals" SG_ 539 SGU26_Object_Type_Can03 0;
BA_ "GenSigInvalidValue" SG_ 539 SGU26_Object_Type_Can03 0;
BA_ "GenSigSendType" SG_ 539 SGU26_Object_Type_Can03 10;
BA_ "GenSigTimeoutValue" SG_ 539 SGU26_Object_Type_Can03 0;
BA_ "EventCommandSignal" SG_ 539 SGU26_Object_ax_Can03 0;
BA_ "GatewayedSignals" SG_ 539 SGU26_Object_ax_Can03 0;
BA_ "GenSigInvalidValue" SG_ 539 SGU26_Object_ax_Can03 0;
BA_ "GenSigSendType" SG_ 539 SGU26_Object_ax_Can03 10;
BA_ "GenSigTimeoutValue" SG_ 539 SGU26_Object_ax_Can03 0;
BA_ "EventCommandSignal" SG_ 539 SGU26_Object_ay_Can03 0;
BA_ "GatewayedSignals" SG_ 539 SGU26_Object_ay_Can03 0;
BA_ "GenSigInvalidValue" SG_ 539 SGU26_Object_ay_Can03 0;
BA_ "GenSigSendType" SG_ 539 SGU26_Object_ay_Can03 10;
BA_ "GenSigTimeoutValue" SG_ 539 SGU26_Object_ay_Can03 0;
BA_ "EventCommandSignal" SG_ 539 SGU26_Object_dx_Nearest_Can03 0;
BA_ "GatewayedSignals" SG_ 539 SGU26_Object_dx_Nearest_Can03 0;
BA_ "GenSigInvalidValue" SG_ 539 SGU26_Object_dx_Nearest_Can03 0;
BA_ "GenSigSendType" SG_ 539 SGU26_Object_dx_Nearest_Can03 1;
BA_ "GenSigTimeoutValue" SG_ 539 SGU26_Object_dx_Nearest_Can03 0;
BA_ "EventCommandSignal" SG_ 539 SGU26_Object_dx_Rear_Can03 0;
BA_ "GatewayedSignals" SG_ 539 SGU26_Object_dx_Rear_Can03 0;
BA_ "GenSigInvalidValue" SG_ 539 SGU26_Object_dx_Rear_Can03 0;
BA_ "GenSigSendType" SG_ 539 SGU26_Object_dx_Rear_Can03 10;
BA_ "GenSigTimeoutValue" SG_ 539 SGU26_Object_dx_Rear_Can03 0;
BA_ "EventCommandSignal" SG_ 539 SGU26_Object_dy_Nearest_Can03 0;
BA_ "GatewayedSignals" SG_ 539 SGU26_Object_dy_Nearest_Can03 0;
BA_ "GenSigInvalidValue" SG_ 539 SGU26_Object_dy_Nearest_Can03 0;
BA_ "GenSigSendType" SG_ 539 SGU26_Object_dy_Nearest_Can03 1;
BA_ "GenSigTimeoutValue" SG_ 539 SGU26_Object_dy_Nearest_Can03 0;
BA_ "EventCommandSignal" SG_ 539 SGU26_Object_dy_Rear_Can03 0;
BA_ "GatewayedSignals" SG_ 539 SGU26_Object_dy_Rear_Can03 0;
BA_ "GenSigInvalidValue" SG_ 539 SGU26_Object_dy_Rear_Can03 0;
BA_ "GenSigSendType" SG_ 539 SGU26_Object_dy_Rear_Can03 10;
BA_ "GenSigTimeoutValue" SG_ 539 SGU26_Object_dy_Rear_Can03 0;
BA_ "EventCommandSignal" SG_ 539 SGU26_Object_vx_Can03 0;
BA_ "GatewayedSignals" SG_ 539 SGU26_Object_vx_Can03 0;
BA_ "GenSigInvalidValue" SG_ 539 SGU26_Object_vx_Can03 0;
BA_ "GenSigSendType" SG_ 539 SGU26_Object_vx_Can03 10;
BA_ "GenSigTimeoutValue" SG_ 539 SGU26_Object_vx_Can03 0;
BA_ "EventCommandSignal" SG_ 539 SGU26_Object_vy_Can03 0;
BA_ "GatewayedSignals" SG_ 539 SGU26_Object_vy_Can03 0;
BA_ "GenSigInvalidValue" SG_ 539 SGU26_Object_vy_Can03 0;
BA_ "GenSigSendType" SG_ 539 SGU26_Object_vy_Can03 10;
BA_ "GenSigTimeoutValue" SG_ 539 SGU26_Object_vy_Can03 0;
BA_ "EventCommandSignal" SG_ 539 SGU26_Object_wExist_Can03 0;
BA_ "GatewayedSignals" SG_ 539 SGU26_Object_wExist_Can03 0;
BA_ "GenSigInvalidValue" SG_ 539 SGU26_Object_wExist_Can03 0;
BA_ "GenSigSendType" SG_ 539 SGU26_Object_wExist_Can03 10;
BA_ "GenSigTimeoutValue" SG_ 539 SGU26_Object_wExist_Can03 0;
BA_ "EventCommandSignal" SG_ 539 SGU26_Object_wObstacle_Can03 0;
BA_ "GatewayedSignals" SG_ 539 SGU26_Object_wObstacle_Can03 0;
BA_ "GenSigInvalidValue" SG_ 539 SGU26_Object_wObstacle_Can03 0;
BA_ "GenSigSendType" SG_ 539 SGU26_Object_wObstacle_Can03 10;
BA_ "GenSigTimeoutValue" SG_ 539 SGU26_Object_wObstacle_Can03 0;
BA_ "EventCommandSignal" SG_ 540 SGU27_BlockCounter_Can03 0;
BA_ "GatewayedSignals" SG_ 540 SGU27_BlockCounter_Can03 0;
BA_ "GenSigInvalidValue" SG_ 540 SGU27_BlockCounter_Can03 0;
BA_ "GenSigSendType" SG_ 540 SGU27_BlockCounter_Can03 10;
BA_ "GenSigTimeoutValue" SG_ 540 SGU27_BlockCounter_Can03 0;
BA_ "EventCommandSignal" SG_ 540 SGU27_LifeCycles_OBJ_Can03 0;
BA_ "GatewayedSignals" SG_ 540 SGU27_LifeCycles_OBJ_Can03 0;
BA_ "GenSigInvalidValue" SG_ 540 SGU27_LifeCycles_OBJ_Can03 0;
BA_ "GenSigSendType" SG_ 540 SGU27_LifeCycles_OBJ_Can03 10;
BA_ "GenSigTimeoutValue" SG_ 540 SGU27_LifeCycles_OBJ_Can03 0;
BA_ "EventCommandSignal" SG_ 540 SGU27_Msg_AliveCounter_Can03 0;
BA_ "GatewayedSignals" SG_ 540 SGU27_Msg_AliveCounter_Can03 0;
BA_ "GenSigInvalidValue" SG_ 540 SGU27_Msg_AliveCounter_Can03 0;
BA_ "GenSigSendType" SG_ 540 SGU27_Msg_AliveCounter_Can03 10;
BA_ "GenSigTimeoutValue" SG_ 540 SGU27_Msg_AliveCounter_Can03 0;
BA_ "EventCommandSignal" SG_ 540 SGU27_Msg_CheckSum_Can03 0;
BA_ "GatewayedSignals" SG_ 540 SGU27_Msg_CheckSum_Can03 0;
BA_ "GenSigInvalidValue" SG_ 540 SGU27_Msg_CheckSum_Can03 0;
BA_ "GenSigSendType" SG_ 540 SGU27_Msg_CheckSum_Can03 10;
BA_ "GenSigTimeoutValue" SG_ 540 SGU27_Msg_CheckSum_Can03 0;
BA_ "IsCrcSignal" SG_ 540 SGU27_Msg_CheckSum_Can03 1;
BA_ "EventCommandSignal" SG_ 540 SGU27_ObjRCS_27_Can03 0;
BA_ "GatewayedSignals" SG_ 540 SGU27_ObjRCS_27_Can03 0;
BA_ "GenSigInvalidValue" SG_ 540 SGU27_ObjRCS_27_Can03 0;
BA_ "GenSigSendType" SG_ 540 SGU27_ObjRCS_27_Can03 10;
BA_ "GenSigTimeoutValue" SG_ 540 SGU27_ObjRCS_27_Can03 0;
BA_ "EventCommandSignal" SG_ 540 SGU27_Obj_DistLat_rms_Can03 0;
BA_ "GatewayedSignals" SG_ 540 SGU27_Obj_DistLat_rms_Can03 0;
BA_ "GenSigInvalidValue" SG_ 540 SGU27_Obj_DistLat_rms_Can03 0;
BA_ "GenSigSendType" SG_ 540 SGU27_Obj_DistLat_rms_Can03 10;
BA_ "GenSigTimeoutValue" SG_ 540 SGU27_Obj_DistLat_rms_Can03 0;
BA_ "EventCommandSignal" SG_ 540 SGU27_Obj_VrelLong_rms_Can03 0;
BA_ "GatewayedSignals" SG_ 540 SGU27_Obj_VrelLong_rms_Can03 0;
BA_ "GenSigInvalidValue" SG_ 540 SGU27_Obj_VrelLong_rms_Can03 0;
BA_ "GenSigSendType" SG_ 540 SGU27_Obj_VrelLong_rms_Can03 10;
BA_ "GenSigTimeoutValue" SG_ 540 SGU27_Obj_VrelLong_rms_Can03 0;
BA_ "EventCommandSignal" SG_ 540 SGU27_Obj_Vrelat_rms_Can03 0;
BA_ "GatewayedSignals" SG_ 540 SGU27_Obj_Vrelat_rms_Can03 0;
BA_ "GenSigInvalidValue" SG_ 540 SGU27_Obj_Vrelat_rms_Can03 0;
BA_ "GenSigSendType" SG_ 540 SGU27_Obj_Vrelat_rms_Can03 10;
BA_ "GenSigTimeoutValue" SG_ 540 SGU27_Obj_Vrelat_rms_Can03 0;
BA_ "EventCommandSignal" SG_ 540 SGU27_Object_DetStatus_Can03 0;
BA_ "GatewayedSignals" SG_ 540 SGU27_Object_DetStatus_Can03 0;
BA_ "GenSigInvalidValue" SG_ 540 SGU27_Object_DetStatus_Can03 0;
BA_ "GenSigSendType" SG_ 540 SGU27_Object_DetStatus_Can03 10;
BA_ "GenSigTimeoutValue" SG_ 540 SGU27_Object_DetStatus_Can03 0;
BA_ "EventCommandSignal" SG_ 540 SGU27_Object_DistLong_rms_Can03 0;
BA_ "GatewayedSignals" SG_ 540 SGU27_Object_DistLong_rms_Can03 0;
BA_ "GenSigInvalidValue" SG_ 540 SGU27_Object_DistLong_rms_Can03 0;
BA_ "GenSigSendType" SG_ 540 SGU27_Object_DistLong_rms_Can03 10;
BA_ "GenSigTimeoutValue" SG_ 540 SGU27_Object_DistLong_rms_Can03 0;
BA_ "EventCommandSignal" SG_ 540 SGU27_Object_ID_Can03 0;
BA_ "GatewayedSignals" SG_ 540 SGU27_Object_ID_Can03 0;
BA_ "GenSigInvalidValue" SG_ 540 SGU27_Object_ID_Can03 0;
BA_ "GenSigSendType" SG_ 540 SGU27_Object_ID_Can03 10;
BA_ "GenSigTimeoutValue" SG_ 540 SGU27_Object_ID_Can03 0;
BA_ "EventCommandSignal" SG_ 540 SGU27_Object_MotionPattern_Can03 0;
BA_ "GatewayedSignals" SG_ 540 SGU27_Object_MotionPattern_Can03 0;
BA_ "GenSigInvalidValue" SG_ 540 SGU27_Object_MotionPattern_Can03 0;
BA_ "GenSigSendType" SG_ 540 SGU27_Object_MotionPattern_Can03 10;
BA_ "GenSigTimeoutValue" SG_ 540 SGU27_Object_MotionPattern_Can03 0;
BA_ "EventCommandSignal" SG_ 540 SGU27_Object_Type_Can03 0;
BA_ "GatewayedSignals" SG_ 540 SGU27_Object_Type_Can03 0;
BA_ "GenSigInvalidValue" SG_ 540 SGU27_Object_Type_Can03 0;
BA_ "GenSigSendType" SG_ 540 SGU27_Object_Type_Can03 10;
BA_ "GenSigTimeoutValue" SG_ 540 SGU27_Object_Type_Can03 0;
BA_ "EventCommandSignal" SG_ 540 SGU27_Object_ax_Can03 0;
BA_ "GatewayedSignals" SG_ 540 SGU27_Object_ax_Can03 0;
BA_ "GenSigInvalidValue" SG_ 540 SGU27_Object_ax_Can03 0;
BA_ "GenSigSendType" SG_ 540 SGU27_Object_ax_Can03 10;
BA_ "GenSigTimeoutValue" SG_ 540 SGU27_Object_ax_Can03 0;
BA_ "EventCommandSignal" SG_ 540 SGU27_Object_ay_Can03 0;
BA_ "GatewayedSignals" SG_ 540 SGU27_Object_ay_Can03 0;
BA_ "GenSigInvalidValue" SG_ 540 SGU27_Object_ay_Can03 0;
BA_ "GenSigSendType" SG_ 540 SGU27_Object_ay_Can03 10;
BA_ "GenSigTimeoutValue" SG_ 540 SGU27_Object_ay_Can03 0;
BA_ "EventCommandSignal" SG_ 540 SGU27_Object_dx_Nearest_Can03 0;
BA_ "GatewayedSignals" SG_ 540 SGU27_Object_dx_Nearest_Can03 0;
BA_ "GenSigInvalidValue" SG_ 540 SGU27_Object_dx_Nearest_Can03 0;
BA_ "GenSigSendType" SG_ 540 SGU27_Object_dx_Nearest_Can03 1;
BA_ "GenSigTimeoutValue" SG_ 540 SGU27_Object_dx_Nearest_Can03 0;
BA_ "EventCommandSignal" SG_ 540 SGU27_Object_dx_Rear_Can03 0;
BA_ "GatewayedSignals" SG_ 540 SGU27_Object_dx_Rear_Can03 0;
BA_ "GenSigInvalidValue" SG_ 540 SGU27_Object_dx_Rear_Can03 0;
BA_ "GenSigSendType" SG_ 540 SGU27_Object_dx_Rear_Can03 10;
BA_ "GenSigTimeoutValue" SG_ 540 SGU27_Object_dx_Rear_Can03 0;
BA_ "EventCommandSignal" SG_ 540 SGU27_Object_dy_Nearest_Can03 0;
BA_ "GatewayedSignals" SG_ 540 SGU27_Object_dy_Nearest_Can03 0;
BA_ "GenSigInvalidValue" SG_ 540 SGU27_Object_dy_Nearest_Can03 0;
BA_ "GenSigSendType" SG_ 540 SGU27_Object_dy_Nearest_Can03 1;
BA_ "GenSigTimeoutValue" SG_ 540 SGU27_Object_dy_Nearest_Can03 0;
BA_ "EventCommandSignal" SG_ 540 SGU27_Object_dy_Rear_Can03 0;
BA_ "GatewayedSignals" SG_ 540 SGU27_Object_dy_Rear_Can03 0;
BA_ "GenSigInvalidValue" SG_ 540 SGU27_Object_dy_Rear_Can03 0;
BA_ "GenSigSendType" SG_ 540 SGU27_Object_dy_Rear_Can03 10;
BA_ "GenSigTimeoutValue" SG_ 540 SGU27_Object_dy_Rear_Can03 0;
BA_ "EventCommandSignal" SG_ 540 SGU27_Object_vx_Can03 0;
BA_ "GatewayedSignals" SG_ 540 SGU27_Object_vx_Can03 0;
BA_ "GenSigInvalidValue" SG_ 540 SGU27_Object_vx_Can03 0;
BA_ "GenSigSendType" SG_ 540 SGU27_Object_vx_Can03 10;
BA_ "GenSigTimeoutValue" SG_ 540 SGU27_Object_vx_Can03 0;
BA_ "EventCommandSignal" SG_ 540 SGU27_Object_vy_Can03 0;
BA_ "GatewayedSignals" SG_ 540 SGU27_Object_vy_Can03 0;
BA_ "GenSigInvalidValue" SG_ 540 SGU27_Object_vy_Can03 0;
BA_ "GenSigSendType" SG_ 540 SGU27_Object_vy_Can03 10;
BA_ "GenSigTimeoutValue" SG_ 540 SGU27_Object_vy_Can03 0;
BA_ "EventCommandSignal" SG_ 540 SGU27_Object_wExist_Can03 0;
BA_ "GatewayedSignals" SG_ 540 SGU27_Object_wExist_Can03 0;
BA_ "GenSigInvalidValue" SG_ 540 SGU27_Object_wExist_Can03 0;
BA_ "GenSigSendType" SG_ 540 SGU27_Object_wExist_Can03 10;
BA_ "GenSigTimeoutValue" SG_ 540 SGU27_Object_wExist_Can03 0;
BA_ "EventCommandSignal" SG_ 540 SGU27_Object_wObstacle_Can03 0;
BA_ "GatewayedSignals" SG_ 540 SGU27_Object_wObstacle_Can03 0;
BA_ "GenSigInvalidValue" SG_ 540 SGU27_Object_wObstacle_Can03 0;
BA_ "GenSigSendType" SG_ 540 SGU27_Object_wObstacle_Can03 10;
BA_ "GenSigTimeoutValue" SG_ 540 SGU27_Object_wObstacle_Can03 0;
BA_ "EventCommandSignal" SG_ 541 SGU28_BlockCounter_Can03 0;
BA_ "GatewayedSignals" SG_ 541 SGU28_BlockCounter_Can03 0;
BA_ "GenSigInvalidValue" SG_ 541 SGU28_BlockCounter_Can03 0;
BA_ "GenSigSendType" SG_ 541 SGU28_BlockCounter_Can03 10;
BA_ "GenSigTimeoutValue" SG_ 541 SGU28_BlockCounter_Can03 0;
BA_ "EventCommandSignal" SG_ 541 SGU28_LifeCycles_OBJ_Can03 0;
BA_ "GatewayedSignals" SG_ 541 SGU28_LifeCycles_OBJ_Can03 0;
BA_ "GenSigInvalidValue" SG_ 541 SGU28_LifeCycles_OBJ_Can03 0;
BA_ "GenSigSendType" SG_ 541 SGU28_LifeCycles_OBJ_Can03 10;
BA_ "GenSigTimeoutValue" SG_ 541 SGU28_LifeCycles_OBJ_Can03 0;
BA_ "EventCommandSignal" SG_ 541 SGU28_Msg_AliveCounter_Can03 0;
BA_ "GatewayedSignals" SG_ 541 SGU28_Msg_AliveCounter_Can03 0;
BA_ "GenSigInvalidValue" SG_ 541 SGU28_Msg_AliveCounter_Can03 0;
BA_ "GenSigSendType" SG_ 541 SGU28_Msg_AliveCounter_Can03 10;
BA_ "GenSigTimeoutValue" SG_ 541 SGU28_Msg_AliveCounter_Can03 0;
BA_ "EventCommandSignal" SG_ 541 SGU28_Msg_CheckSum_Can03 0;
BA_ "GatewayedSignals" SG_ 541 SGU28_Msg_CheckSum_Can03 0;
BA_ "GenSigInvalidValue" SG_ 541 SGU28_Msg_CheckSum_Can03 0;
BA_ "GenSigSendType" SG_ 541 SGU28_Msg_CheckSum_Can03 10;
BA_ "GenSigTimeoutValue" SG_ 541 SGU28_Msg_CheckSum_Can03 0;
BA_ "IsCrcSignal" SG_ 541 SGU28_Msg_CheckSum_Can03 1;
BA_ "EventCommandSignal" SG_ 541 SGU28_ObjRCS_28_Can03 0;
BA_ "GatewayedSignals" SG_ 541 SGU28_ObjRCS_28_Can03 0;
BA_ "GenSigInvalidValue" SG_ 541 SGU28_ObjRCS_28_Can03 0;
BA_ "GenSigSendType" SG_ 541 SGU28_ObjRCS_28_Can03 10;
BA_ "GenSigTimeoutValue" SG_ 541 SGU28_ObjRCS_28_Can03 0;
BA_ "EventCommandSignal" SG_ 541 SGU28_Obj_DistLat_rms_Can03 0;
BA_ "GatewayedSignals" SG_ 541 SGU28_Obj_DistLat_rms_Can03 0;
BA_ "GenSigInvalidValue" SG_ 541 SGU28_Obj_DistLat_rms_Can03 0;
BA_ "GenSigSendType" SG_ 541 SGU28_Obj_DistLat_rms_Can03 10;
BA_ "GenSigTimeoutValue" SG_ 541 SGU28_Obj_DistLat_rms_Can03 0;
BA_ "EventCommandSignal" SG_ 541 SGU28_Obj_VrelLong_rms_Can03 0;
BA_ "GatewayedSignals" SG_ 541 SGU28_Obj_VrelLong_rms_Can03 0;
BA_ "GenSigInvalidValue" SG_ 541 SGU28_Obj_VrelLong_rms_Can03 0;
BA_ "GenSigSendType" SG_ 541 SGU28_Obj_VrelLong_rms_Can03 10;
BA_ "GenSigTimeoutValue" SG_ 541 SGU28_Obj_VrelLong_rms_Can03 0;
BA_ "EventCommandSignal" SG_ 541 SGU28_Obj_Vrelat_rms_Can03 0;
BA_ "GatewayedSignals" SG_ 541 SGU28_Obj_Vrelat_rms_Can03 0;
BA_ "GenSigInvalidValue" SG_ 541 SGU28_Obj_Vrelat_rms_Can03 0;
BA_ "GenSigSendType" SG_ 541 SGU28_Obj_Vrelat_rms_Can03 10;
BA_ "GenSigTimeoutValue" SG_ 541 SGU28_Obj_Vrelat_rms_Can03 0;
BA_ "EventCommandSignal" SG_ 541 SGU28_Object_DetStatus_Can03 0;
BA_ "GatewayedSignals" SG_ 541 SGU28_Object_DetStatus_Can03 0;
BA_ "GenSigInvalidValue" SG_ 541 SGU28_Object_DetStatus_Can03 0;
BA_ "GenSigSendType" SG_ 541 SGU28_Object_DetStatus_Can03 10;
BA_ "GenSigTimeoutValue" SG_ 541 SGU28_Object_DetStatus_Can03 0;
BA_ "EventCommandSignal" SG_ 541 SGU28_Object_DistLong_rms_Can03 0;
BA_ "GatewayedSignals" SG_ 541 SGU28_Object_DistLong_rms_Can03 0;
BA_ "GenSigInvalidValue" SG_ 541 SGU28_Object_DistLong_rms_Can03 0;
BA_ "GenSigSendType" SG_ 541 SGU28_Object_DistLong_rms_Can03 10;
BA_ "GenSigTimeoutValue" SG_ 541 SGU28_Object_DistLong_rms_Can03 0;
BA_ "EventCommandSignal" SG_ 541 SGU28_Object_ID_Can03 0;
BA_ "GatewayedSignals" SG_ 541 SGU28_Object_ID_Can03 0;
BA_ "GenSigInvalidValue" SG_ 541 SGU28_Object_ID_Can03 0;
BA_ "GenSigSendType" SG_ 541 SGU28_Object_ID_Can03 10;
BA_ "GenSigTimeoutValue" SG_ 541 SGU28_Object_ID_Can03 0;
BA_ "EventCommandSignal" SG_ 541 SGU28_Object_MotionPattern_Can03 0;
BA_ "GatewayedSignals" SG_ 541 SGU28_Object_MotionPattern_Can03 0;
BA_ "GenSigInvalidValue" SG_ 541 SGU28_Object_MotionPattern_Can03 0;
BA_ "GenSigSendType" SG_ 541 SGU28_Object_MotionPattern_Can03 10;
BA_ "GenSigTimeoutValue" SG_ 541 SGU28_Object_MotionPattern_Can03 0;
BA_ "EventCommandSignal" SG_ 541 SGU28_Object_Type_Can03 0;
BA_ "GatewayedSignals" SG_ 541 SGU28_Object_Type_Can03 0;
BA_ "GenSigInvalidValue" SG_ 541 SGU28_Object_Type_Can03 0;
BA_ "GenSigSendType" SG_ 541 SGU28_Object_Type_Can03 10;
BA_ "GenSigTimeoutValue" SG_ 541 SGU28_Object_Type_Can03 0;
BA_ "EventCommandSignal" SG_ 541 SGU28_Object_ax_Can03 0;
BA_ "GatewayedSignals" SG_ 541 SGU28_Object_ax_Can03 0;
BA_ "GenSigInvalidValue" SG_ 541 SGU28_Object_ax_Can03 0;
BA_ "GenSigSendType" SG_ 541 SGU28_Object_ax_Can03 10;
BA_ "GenSigTimeoutValue" SG_ 541 SGU28_Object_ax_Can03 0;
BA_ "EventCommandSignal" SG_ 541 SGU28_Object_ay_Can03 0;
BA_ "GatewayedSignals" SG_ 541 SGU28_Object_ay_Can03 0;
BA_ "GenSigInvalidValue" SG_ 541 SGU28_Object_ay_Can03 0;
BA_ "GenSigSendType" SG_ 541 SGU28_Object_ay_Can03 10;
BA_ "GenSigTimeoutValue" SG_ 541 SGU28_Object_ay_Can03 0;
BA_ "EventCommandSignal" SG_ 541 SGU28_Object_dx_Nearest_Can03 0;
BA_ "GatewayedSignals" SG_ 541 SGU28_Object_dx_Nearest_Can03 0;
BA_ "GenSigInvalidValue" SG_ 541 SGU28_Object_dx_Nearest_Can03 0;
BA_ "GenSigSendType" SG_ 541 SGU28_Object_dx_Nearest_Can03 1;
BA_ "GenSigTimeoutValue" SG_ 541 SGU28_Object_dx_Nearest_Can03 0;
BA_ "EventCommandSignal" SG_ 541 SGU28_Object_dx_Rear_Can03 0;
BA_ "GatewayedSignals" SG_ 541 SGU28_Object_dx_Rear_Can03 0;
BA_ "GenSigInvalidValue" SG_ 541 SGU28_Object_dx_Rear_Can03 0;
BA_ "GenSigSendType" SG_ 541 SGU28_Object_dx_Rear_Can03 10;
BA_ "GenSigTimeoutValue" SG_ 541 SGU28_Object_dx_Rear_Can03 0;
BA_ "EventCommandSignal" SG_ 541 SGU28_Object_dy_Nearest_Can03 0;
BA_ "GatewayedSignals" SG_ 541 SGU28_Object_dy_Nearest_Can03 0;
BA_ "GenSigInvalidValue" SG_ 541 SGU28_Object_dy_Nearest_Can03 0;
BA_ "GenSigSendType" SG_ 541 SGU28_Object_dy_Nearest_Can03 1;
BA_ "GenSigTimeoutValue" SG_ 541 SGU28_Object_dy_Nearest_Can03 0;
BA_ "EventCommandSignal" SG_ 541 SGU28_Object_dy_Rear_Can03 0;
BA_ "GatewayedSignals" SG_ 541 SGU28_Object_dy_Rear_Can03 0;
BA_ "GenSigInvalidValue" SG_ 541 SGU28_Object_dy_Rear_Can03 0;
BA_ "GenSigSendType" SG_ 541 SGU28_Object_dy_Rear_Can03 10;
BA_ "GenSigTimeoutValue" SG_ 541 SGU28_Object_dy_Rear_Can03 0;
BA_ "EventCommandSignal" SG_ 541 SGU28_Object_vx_Can03 0;
BA_ "GatewayedSignals" SG_ 541 SGU28_Object_vx_Can03 0;
BA_ "GenSigInvalidValue" SG_ 541 SGU28_Object_vx_Can03 0;
BA_ "GenSigSendType" SG_ 541 SGU28_Object_vx_Can03 10;
BA_ "GenSigTimeoutValue" SG_ 541 SGU28_Object_vx_Can03 0;
BA_ "EventCommandSignal" SG_ 541 SGU28_Object_vy_Can03 0;
BA_ "GatewayedSignals" SG_ 541 SGU28_Object_vy_Can03 0;
BA_ "GenSigInvalidValue" SG_ 541 SGU28_Object_vy_Can03 0;
BA_ "GenSigSendType" SG_ 541 SGU28_Object_vy_Can03 10;
BA_ "GenSigTimeoutValue" SG_ 541 SGU28_Object_vy_Can03 0;
BA_ "EventCommandSignal" SG_ 541 SGU28_Object_wExist_Can03 0;
BA_ "GatewayedSignals" SG_ 541 SGU28_Object_wExist_Can03 0;
BA_ "GenSigInvalidValue" SG_ 541 SGU28_Object_wExist_Can03 0;
BA_ "GenSigSendType" SG_ 541 SGU28_Object_wExist_Can03 10;
BA_ "GenSigTimeoutValue" SG_ 541 SGU28_Object_wExist_Can03 0;
BA_ "EventCommandSignal" SG_ 541 SGU28_Object_wObstacle_Can03 0;
BA_ "GatewayedSignals" SG_ 541 SGU28_Object_wObstacle_Can03 0;
BA_ "GenSigInvalidValue" SG_ 541 SGU28_Object_wObstacle_Can03 0;
BA_ "GenSigSendType" SG_ 541 SGU28_Object_wObstacle_Can03 10;
BA_ "GenSigTimeoutValue" SG_ 541 SGU28_Object_wObstacle_Can03 0;
BA_ "EventCommandSignal" SG_ 542 SGU29_BlockCounter_Can03 0;
BA_ "GatewayedSignals" SG_ 542 SGU29_BlockCounter_Can03 0;
BA_ "GenSigInvalidValue" SG_ 542 SGU29_BlockCounter_Can03 0;
BA_ "GenSigSendType" SG_ 542 SGU29_BlockCounter_Can03 10;
BA_ "GenSigTimeoutValue" SG_ 542 SGU29_BlockCounter_Can03 0;
BA_ "EventCommandSignal" SG_ 542 SGU29_LifeCycles_OBJ_Can03 0;
BA_ "GatewayedSignals" SG_ 542 SGU29_LifeCycles_OBJ_Can03 0;
BA_ "GenSigInvalidValue" SG_ 542 SGU29_LifeCycles_OBJ_Can03 0;
BA_ "GenSigSendType" SG_ 542 SGU29_LifeCycles_OBJ_Can03 10;
BA_ "GenSigTimeoutValue" SG_ 542 SGU29_LifeCycles_OBJ_Can03 0;
BA_ "EventCommandSignal" SG_ 542 SGU29_Msg_AliveCounter_Can03 0;
BA_ "GatewayedSignals" SG_ 542 SGU29_Msg_AliveCounter_Can03 0;
BA_ "GenSigInvalidValue" SG_ 542 SGU29_Msg_AliveCounter_Can03 0;
BA_ "GenSigSendType" SG_ 542 SGU29_Msg_AliveCounter_Can03 10;
BA_ "GenSigTimeoutValue" SG_ 542 SGU29_Msg_AliveCounter_Can03 0;
BA_ "EventCommandSignal" SG_ 542 SGU29_Msg_CheckSum_Can03 0;
BA_ "GatewayedSignals" SG_ 542 SGU29_Msg_CheckSum_Can03 0;
BA_ "GenSigInvalidValue" SG_ 542 SGU29_Msg_CheckSum_Can03 0;
BA_ "GenSigSendType" SG_ 542 SGU29_Msg_CheckSum_Can03 10;
BA_ "GenSigTimeoutValue" SG_ 542 SGU29_Msg_CheckSum_Can03 0;
BA_ "IsCrcSignal" SG_ 542 SGU29_Msg_CheckSum_Can03 1;
BA_ "EventCommandSignal" SG_ 542 SGU29_ObjRCS_29_Can03 0;
BA_ "GatewayedSignals" SG_ 542 SGU29_ObjRCS_29_Can03 0;
BA_ "GenSigInvalidValue" SG_ 542 SGU29_ObjRCS_29_Can03 0;
BA_ "GenSigSendType" SG_ 542 SGU29_ObjRCS_29_Can03 10;
BA_ "GenSigTimeoutValue" SG_ 542 SGU29_ObjRCS_29_Can03 0;
BA_ "EventCommandSignal" SG_ 542 SGU29_Obj_DistLat_rms_Can03 0;
BA_ "GatewayedSignals" SG_ 542 SGU29_Obj_DistLat_rms_Can03 0;
BA_ "GenSigInvalidValue" SG_ 542 SGU29_Obj_DistLat_rms_Can03 0;
BA_ "GenSigSendType" SG_ 542 SGU29_Obj_DistLat_rms_Can03 10;
BA_ "GenSigTimeoutValue" SG_ 542 SGU29_Obj_DistLat_rms_Can03 0;
BA_ "EventCommandSignal" SG_ 542 SGU29_Obj_VrelLong_rms_Can03 0;
BA_ "GatewayedSignals" SG_ 542 SGU29_Obj_VrelLong_rms_Can03 0;
BA_ "GenSigInvalidValue" SG_ 542 SGU29_Obj_VrelLong_rms_Can03 0;
BA_ "GenSigSendType" SG_ 542 SGU29_Obj_VrelLong_rms_Can03 10;
BA_ "GenSigTimeoutValue" SG_ 542 SGU29_Obj_VrelLong_rms_Can03 0;
BA_ "EventCommandSignal" SG_ 542 SGU29_Obj_Vrelat_rms_Can03 0;
BA_ "GatewayedSignals" SG_ 542 SGU29_Obj_Vrelat_rms_Can03 0;
BA_ "GenSigInvalidValue" SG_ 542 SGU29_Obj_Vrelat_rms_Can03 0;
BA_ "GenSigSendType" SG_ 542 SGU29_Obj_Vrelat_rms_Can03 10;
BA_ "GenSigTimeoutValue" SG_ 542 SGU29_Obj_Vrelat_rms_Can03 0;
BA_ "EventCommandSignal" SG_ 542 SGU29_Object_DetStatus_Can03 0;
BA_ "GatewayedSignals" SG_ 542 SGU29_Object_DetStatus_Can03 0;
BA_ "GenSigInvalidValue" SG_ 542 SGU29_Object_DetStatus_Can03 0;
BA_ "GenSigSendType" SG_ 542 SGU29_Object_DetStatus_Can03 10;
BA_ "GenSigTimeoutValue" SG_ 542 SGU29_Object_DetStatus_Can03 0;
BA_ "EventCommandSignal" SG_ 542 SGU29_Object_DistLong_rms_Can03 0;
BA_ "GatewayedSignals" SG_ 542 SGU29_Object_DistLong_rms_Can03 0;
BA_ "GenSigInvalidValue" SG_ 542 SGU29_Object_DistLong_rms_Can03 0;
BA_ "GenSigSendType" SG_ 542 SGU29_Object_DistLong_rms_Can03 10;
BA_ "GenSigTimeoutValue" SG_ 542 SGU29_Object_DistLong_rms_Can03 0;
BA_ "EventCommandSignal" SG_ 542 SGU29_Object_ID_Can03 0;
BA_ "GatewayedSignals" SG_ 542 SGU29_Object_ID_Can03 0;
BA_ "GenSigInvalidValue" SG_ 542 SGU29_Object_ID_Can03 0;
BA_ "GenSigSendType" SG_ 542 SGU29_Object_ID_Can03 10;
BA_ "GenSigTimeoutValue" SG_ 542 SGU29_Object_ID_Can03 0;
BA_ "EventCommandSignal" SG_ 542 SGU29_Object_MotionPattern_Can03 0;
BA_ "GatewayedSignals" SG_ 542 SGU29_Object_MotionPattern_Can03 0;
BA_ "GenSigInvalidValue" SG_ 542 SGU29_Object_MotionPattern_Can03 0;
BA_ "GenSigSendType" SG_ 542 SGU29_Object_MotionPattern_Can03 10;
BA_ "GenSigTimeoutValue" SG_ 542 SGU29_Object_MotionPattern_Can03 0;
BA_ "EventCommandSignal" SG_ 542 SGU29_Object_Type_Can03 0;
BA_ "GatewayedSignals" SG_ 542 SGU29_Object_Type_Can03 0;
BA_ "GenSigInvalidValue" SG_ 542 SGU29_Object_Type_Can03 0;
BA_ "GenSigSendType" SG_ 542 SGU29_Object_Type_Can03 10;
BA_ "GenSigTimeoutValue" SG_ 542 SGU29_Object_Type_Can03 0;
BA_ "EventCommandSignal" SG_ 542 SGU29_Object_ax_Can03 0;
BA_ "GatewayedSignals" SG_ 542 SGU29_Object_ax_Can03 0;
BA_ "GenSigInvalidValue" SG_ 542 SGU29_Object_ax_Can03 0;
BA_ "GenSigSendType" SG_ 542 SGU29_Object_ax_Can03 10;
BA_ "GenSigTimeoutValue" SG_ 542 SGU29_Object_ax_Can03 0;
BA_ "EventCommandSignal" SG_ 542 SGU29_Object_ay_Can03 0;
BA_ "GatewayedSignals" SG_ 542 SGU29_Object_ay_Can03 0;
BA_ "GenSigInvalidValue" SG_ 542 SGU29_Object_ay_Can03 0;
BA_ "GenSigSendType" SG_ 542 SGU29_Object_ay_Can03 10;
BA_ "GenSigTimeoutValue" SG_ 542 SGU29_Object_ay_Can03 0;
BA_ "EventCommandSignal" SG_ 542 SGU29_Object_dx_Nearest_Can03 0;
BA_ "GatewayedSignals" SG_ 542 SGU29_Object_dx_Nearest_Can03 0;
BA_ "GenSigInvalidValue" SG_ 542 SGU29_Object_dx_Nearest_Can03 0;
BA_ "GenSigSendType" SG_ 542 SGU29_Object_dx_Nearest_Can03 1;
BA_ "GenSigTimeoutValue" SG_ 542 SGU29_Object_dx_Nearest_Can03 0;
BA_ "EventCommandSignal" SG_ 542 SGU29_Object_dx_Rear_Can03 0;
BA_ "GatewayedSignals" SG_ 542 SGU29_Object_dx_Rear_Can03 0;
BA_ "GenSigInvalidValue" SG_ 542 SGU29_Object_dx_Rear_Can03 0;
BA_ "GenSigSendType" SG_ 542 SGU29_Object_dx_Rear_Can03 10;
BA_ "GenSigTimeoutValue" SG_ 542 SGU29_Object_dx_Rear_Can03 0;
BA_ "EventCommandSignal" SG_ 542 SGU29_Object_dy_Nearest_Can03 0;
BA_ "GatewayedSignals" SG_ 542 SGU29_Object_dy_Nearest_Can03 0;
BA_ "GenSigInvalidValue" SG_ 542 SGU29_Object_dy_Nearest_Can03 0;
BA_ "GenSigSendType" SG_ 542 SGU29_Object_dy_Nearest_Can03 1;
BA_ "GenSigTimeoutValue" SG_ 542 SGU29_Object_dy_Nearest_Can03 0;
BA_ "EventCommandSignal" SG_ 542 SGU29_Object_dy_Rear_Can03 0;
BA_ "GatewayedSignals" SG_ 542 SGU29_Object_dy_Rear_Can03 0;
BA_ "GenSigInvalidValue" SG_ 542 SGU29_Object_dy_Rear_Can03 0;
BA_ "GenSigSendType" SG_ 542 SGU29_Object_dy_Rear_Can03 10;
BA_ "GenSigTimeoutValue" SG_ 542 SGU29_Object_dy_Rear_Can03 0;
BA_ "EventCommandSignal" SG_ 542 SGU29_Object_vx_Can03 0;
BA_ "GatewayedSignals" SG_ 542 SGU29_Object_vx_Can03 0;
BA_ "GenSigInvalidValue" SG_ 542 SGU29_Object_vx_Can03 0;
BA_ "GenSigSendType" SG_ 542 SGU29_Object_vx_Can03 10;
BA_ "GenSigTimeoutValue" SG_ 542 SGU29_Object_vx_Can03 0;
BA_ "EventCommandSignal" SG_ 542 SGU29_Object_vy_Can03 0;
BA_ "GatewayedSignals" SG_ 542 SGU29_Object_vy_Can03 0;
BA_ "GenSigInvalidValue" SG_ 542 SGU29_Object_vy_Can03 0;
BA_ "GenSigSendType" SG_ 542 SGU29_Object_vy_Can03 10;
BA_ "GenSigTimeoutValue" SG_ 542 SGU29_Object_vy_Can03 0;
BA_ "EventCommandSignal" SG_ 542 SGU29_Object_wExist_Can03 0;
BA_ "GatewayedSignals" SG_ 542 SGU29_Object_wExist_Can03 0;
BA_ "GenSigInvalidValue" SG_ 542 SGU29_Object_wExist_Can03 0;
BA_ "GenSigSendType" SG_ 542 SGU29_Object_wExist_Can03 10;
BA_ "GenSigTimeoutValue" SG_ 542 SGU29_Object_wExist_Can03 0;
BA_ "EventCommandSignal" SG_ 542 SGU29_Object_wObstacle_Can03 0;
BA_ "GatewayedSignals" SG_ 542 SGU29_Object_wObstacle_Can03 0;
BA_ "GenSigInvalidValue" SG_ 542 SGU29_Object_wObstacle_Can03 0;
BA_ "GenSigSendType" SG_ 542 SGU29_Object_wObstacle_Can03 10;
BA_ "GenSigTimeoutValue" SG_ 542 SGU29_Object_wObstacle_Can03 0;
BA_ "EventCommandSignal" SG_ 543 SGU30_BlockCounter_Can03 0;
BA_ "GatewayedSignals" SG_ 543 SGU30_BlockCounter_Can03 0;
BA_ "GenSigInvalidValue" SG_ 543 SGU30_BlockCounter_Can03 0;
BA_ "GenSigSendType" SG_ 543 SGU30_BlockCounter_Can03 10;
BA_ "GenSigTimeoutValue" SG_ 543 SGU30_BlockCounter_Can03 0;
BA_ "EventCommandSignal" SG_ 543 SGU30_LifeCycles_OBJ_Can03 0;
BA_ "GatewayedSignals" SG_ 543 SGU30_LifeCycles_OBJ_Can03 0;
BA_ "GenSigInvalidValue" SG_ 543 SGU30_LifeCycles_OBJ_Can03 0;
BA_ "GenSigSendType" SG_ 543 SGU30_LifeCycles_OBJ_Can03 10;
BA_ "GenSigTimeoutValue" SG_ 543 SGU30_LifeCycles_OBJ_Can03 0;
BA_ "EventCommandSignal" SG_ 543 SGU30_Msg_AliveCounter_Can03 0;
BA_ "GatewayedSignals" SG_ 543 SGU30_Msg_AliveCounter_Can03 0;
BA_ "GenSigInvalidValue" SG_ 543 SGU30_Msg_AliveCounter_Can03 0;
BA_ "GenSigSendType" SG_ 543 SGU30_Msg_AliveCounter_Can03 10;
BA_ "GenSigTimeoutValue" SG_ 543 SGU30_Msg_AliveCounter_Can03 0;
BA_ "EventCommandSignal" SG_ 543 SGU30_Msg_CheckSum_Can03 0;
BA_ "GatewayedSignals" SG_ 543 SGU30_Msg_CheckSum_Can03 0;
BA_ "GenSigInvalidValue" SG_ 543 SGU30_Msg_CheckSum_Can03 0;
BA_ "GenSigSendType" SG_ 543 SGU30_Msg_CheckSum_Can03 10;
BA_ "GenSigTimeoutValue" SG_ 543 SGU30_Msg_CheckSum_Can03 0;
BA_ "IsCrcSignal" SG_ 543 SGU30_Msg_CheckSum_Can03 1;
BA_ "EventCommandSignal" SG_ 543 SGU30_ObjRCS_30_Can03 0;
BA_ "GatewayedSignals" SG_ 543 SGU30_ObjRCS_30_Can03 0;
BA_ "GenSigInvalidValue" SG_ 543 SGU30_ObjRCS_30_Can03 0;
BA_ "GenSigSendType" SG_ 543 SGU30_ObjRCS_30_Can03 10;
BA_ "GenSigTimeoutValue" SG_ 543 SGU30_ObjRCS_30_Can03 0;
BA_ "EventCommandSignal" SG_ 543 SGU30_Obj_DistLat_rms_Can03 0;
BA_ "GatewayedSignals" SG_ 543 SGU30_Obj_DistLat_rms_Can03 0;
BA_ "GenSigInvalidValue" SG_ 543 SGU30_Obj_DistLat_rms_Can03 0;
BA_ "GenSigSendType" SG_ 543 SGU30_Obj_DistLat_rms_Can03 10;
BA_ "GenSigTimeoutValue" SG_ 543 SGU30_Obj_DistLat_rms_Can03 0;
BA_ "EventCommandSignal" SG_ 543 SGU30_Obj_VrelLong_rms_Can03 0;
BA_ "GatewayedSignals" SG_ 543 SGU30_Obj_VrelLong_rms_Can03 0;
BA_ "GenSigInvalidValue" SG_ 543 SGU30_Obj_VrelLong_rms_Can03 0;
BA_ "GenSigSendType" SG_ 543 SGU30_Obj_VrelLong_rms_Can03 10;
BA_ "GenSigTimeoutValue" SG_ 543 SGU30_Obj_VrelLong_rms_Can03 0;
BA_ "EventCommandSignal" SG_ 543 SGU30_Obj_Vrelat_rms_Can03 0;
BA_ "GatewayedSignals" SG_ 543 SGU30_Obj_Vrelat_rms_Can03 0;
BA_ "GenSigInvalidValue" SG_ 543 SGU30_Obj_Vrelat_rms_Can03 0;
BA_ "GenSigSendType" SG_ 543 SGU30_Obj_Vrelat_rms_Can03 10;
BA_ "GenSigTimeoutValue" SG_ 543 SGU30_Obj_Vrelat_rms_Can03 0;
BA_ "EventCommandSignal" SG_ 543 SGU30_Object_DetStatus_Can03 0;
BA_ "GatewayedSignals" SG_ 543 SGU30_Object_DetStatus_Can03 0;
BA_ "GenSigInvalidValue" SG_ 543 SGU30_Object_DetStatus_Can03 0;
BA_ "GenSigSendType" SG_ 543 SGU30_Object_DetStatus_Can03 10;
BA_ "GenSigTimeoutValue" SG_ 543 SGU30_Object_DetStatus_Can03 0;
BA_ "EventCommandSignal" SG_ 543 SGU30_Object_DistLong_rms_Can03 0;
BA_ "GatewayedSignals" SG_ 543 SGU30_Object_DistLong_rms_Can03 0;
BA_ "GenSigInvalidValue" SG_ 543 SGU30_Object_DistLong_rms_Can03 0;
BA_ "GenSigSendType" SG_ 543 SGU30_Object_DistLong_rms_Can03 10;
BA_ "GenSigTimeoutValue" SG_ 543 SGU30_Object_DistLong_rms_Can03 0;
BA_ "EventCommandSignal" SG_ 543 SGU30_Object_ID_Can03 0;
BA_ "GatewayedSignals" SG_ 543 SGU30_Object_ID_Can03 0;
BA_ "GenSigInvalidValue" SG_ 543 SGU30_Object_ID_Can03 0;
BA_ "GenSigSendType" SG_ 543 SGU30_Object_ID_Can03 10;
BA_ "GenSigTimeoutValue" SG_ 543 SGU30_Object_ID_Can03 0;
BA_ "EventCommandSignal" SG_ 543 SGU30_Object_MotionPattern_Can03 0;
BA_ "GatewayedSignals" SG_ 543 SGU30_Object_MotionPattern_Can03 0;
BA_ "GenSigInvalidValue" SG_ 543 SGU30_Object_MotionPattern_Can03 0;
BA_ "GenSigSendType" SG_ 543 SGU30_Object_MotionPattern_Can03 10;
BA_ "GenSigTimeoutValue" SG_ 543 SGU30_Object_MotionPattern_Can03 0;
BA_ "EventCommandSignal" SG_ 543 SGU30_Object_Type_Can03 0;
BA_ "GatewayedSignals" SG_ 543 SGU30_Object_Type_Can03 0;
BA_ "GenSigInvalidValue" SG_ 543 SGU30_Object_Type_Can03 0;
BA_ "GenSigSendType" SG_ 543 SGU30_Object_Type_Can03 10;
BA_ "GenSigTimeoutValue" SG_ 543 SGU30_Object_Type_Can03 0;
BA_ "EventCommandSignal" SG_ 543 SGU30_Object_ax_Can03 0;
BA_ "GatewayedSignals" SG_ 543 SGU30_Object_ax_Can03 0;
BA_ "GenSigInvalidValue" SG_ 543 SGU30_Object_ax_Can03 0;
BA_ "GenSigSendType" SG_ 543 SGU30_Object_ax_Can03 10;
BA_ "GenSigTimeoutValue" SG_ 543 SGU30_Object_ax_Can03 0;
BA_ "EventCommandSignal" SG_ 543 SGU30_Object_ay_Can03 0;
BA_ "GatewayedSignals" SG_ 543 SGU30_Object_ay_Can03 0;
BA_ "GenSigInvalidValue" SG_ 543 SGU30_Object_ay_Can03 0;
BA_ "GenSigSendType" SG_ 543 SGU30_Object_ay_Can03 10;
BA_ "GenSigTimeoutValue" SG_ 543 SGU30_Object_ay_Can03 0;
BA_ "EventCommandSignal" SG_ 543 SGU30_Object_dx_Nearest_Can03 0;
BA_ "GatewayedSignals" SG_ 543 SGU30_Object_dx_Nearest_Can03 0;
BA_ "GenSigInvalidValue" SG_ 543 SGU30_Object_dx_Nearest_Can03 0;
BA_ "GenSigSendType" SG_ 543 SGU30_Object_dx_Nearest_Can03 1;
BA_ "GenSigTimeoutValue" SG_ 543 SGU30_Object_dx_Nearest_Can03 0;
BA_ "EventCommandSignal" SG_ 543 SGU30_Object_dx_Rear_Can03 0;
BA_ "GatewayedSignals" SG_ 543 SGU30_Object_dx_Rear_Can03 0;
BA_ "GenSigInvalidValue" SG_ 543 SGU30_Object_dx_Rear_Can03 0;
BA_ "GenSigSendType" SG_ 543 SGU30_Object_dx_Rear_Can03 10;
BA_ "GenSigTimeoutValue" SG_ 543 SGU30_Object_dx_Rear_Can03 0;
BA_ "EventCommandSignal" SG_ 543 SGU30_Object_dy_Nearest_Can03 0;
BA_ "GatewayedSignals" SG_ 543 SGU30_Object_dy_Nearest_Can03 0;
BA_ "GenSigInvalidValue" SG_ 543 SGU30_Object_dy_Nearest_Can03 0;
BA_ "GenSigSendType" SG_ 543 SGU30_Object_dy_Nearest_Can03 1;
BA_ "GenSigTimeoutValue" SG_ 543 SGU30_Object_dy_Nearest_Can03 0;
BA_ "EventCommandSignal" SG_ 543 SGU30_Object_dy_Rear_Can03 0;
BA_ "GatewayedSignals" SG_ 543 SGU30_Object_dy_Rear_Can03 0;
BA_ "GenSigInvalidValue" SG_ 543 SGU30_Object_dy_Rear_Can03 0;
BA_ "GenSigSendType" SG_ 543 SGU30_Object_dy_Rear_Can03 10;
BA_ "GenSigTimeoutValue" SG_ 543 SGU30_Object_dy_Rear_Can03 0;
BA_ "EventCommandSignal" SG_ 543 SGU30_Object_vx_Can03 0;
BA_ "GatewayedSignals" SG_ 543 SGU30_Object_vx_Can03 0;
BA_ "GenSigInvalidValue" SG_ 543 SGU30_Object_vx_Can03 0;
BA_ "GenSigSendType" SG_ 543 SGU30_Object_vx_Can03 10;
BA_ "GenSigTimeoutValue" SG_ 543 SGU30_Object_vx_Can03 0;
BA_ "EventCommandSignal" SG_ 543 SGU30_Object_vy_Can03 0;
BA_ "GatewayedSignals" SG_ 543 SGU30_Object_vy_Can03 0;
BA_ "GenSigInvalidValue" SG_ 543 SGU30_Object_vy_Can03 0;
BA_ "GenSigSendType" SG_ 543 SGU30_Object_vy_Can03 10;
BA_ "GenSigTimeoutValue" SG_ 543 SGU30_Object_vy_Can03 0;
BA_ "EventCommandSignal" SG_ 543 SGU30_Object_wExist_Can03 0;
BA_ "GatewayedSignals" SG_ 543 SGU30_Object_wExist_Can03 0;
BA_ "GenSigInvalidValue" SG_ 543 SGU30_Object_wExist_Can03 0;
BA_ "GenSigSendType" SG_ 543 SGU30_Object_wExist_Can03 10;
BA_ "GenSigTimeoutValue" SG_ 543 SGU30_Object_wExist_Can03 0;
BA_ "EventCommandSignal" SG_ 543 SGU30_Object_wObstacle_Can03 0;
BA_ "GatewayedSignals" SG_ 543 SGU30_Object_wObstacle_Can03 0;
BA_ "GenSigInvalidValue" SG_ 543 SGU30_Object_wObstacle_Can03 0;
BA_ "GenSigSendType" SG_ 543 SGU30_Object_wObstacle_Can03 10;
BA_ "GenSigTimeoutValue" SG_ 543 SGU30_Object_wObstacle_Can03 0;
BA_ "EventCommandSignal" SG_ 544 SGU31_BlockCounter_Can03 0;
BA_ "GatewayedSignals" SG_ 544 SGU31_BlockCounter_Can03 0;
BA_ "GenSigInvalidValue" SG_ 544 SGU31_BlockCounter_Can03 0;
BA_ "GenSigSendType" SG_ 544 SGU31_BlockCounter_Can03 10;
BA_ "GenSigTimeoutValue" SG_ 544 SGU31_BlockCounter_Can03 0;
BA_ "EventCommandSignal" SG_ 544 SGU31_LifeCycles_OBJ_Can03 0;
BA_ "GatewayedSignals" SG_ 544 SGU31_LifeCycles_OBJ_Can03 0;
BA_ "GenSigInvalidValue" SG_ 544 SGU31_LifeCycles_OBJ_Can03 0;
BA_ "GenSigSendType" SG_ 544 SGU31_LifeCycles_OBJ_Can03 10;
BA_ "GenSigTimeoutValue" SG_ 544 SGU31_LifeCycles_OBJ_Can03 0;
BA_ "EventCommandSignal" SG_ 544 SGU31_Msg_AliveCounter_Can03 0;
BA_ "GatewayedSignals" SG_ 544 SGU31_Msg_AliveCounter_Can03 0;
BA_ "GenSigInvalidValue" SG_ 544 SGU31_Msg_AliveCounter_Can03 0;
BA_ "GenSigSendType" SG_ 544 SGU31_Msg_AliveCounter_Can03 10;
BA_ "GenSigTimeoutValue" SG_ 544 SGU31_Msg_AliveCounter_Can03 0;
BA_ "EventCommandSignal" SG_ 544 SGU31_Msg_CheckSum_Can03 0;
BA_ "GatewayedSignals" SG_ 544 SGU31_Msg_CheckSum_Can03 0;
BA_ "GenSigInvalidValue" SG_ 544 SGU31_Msg_CheckSum_Can03 0;
BA_ "GenSigSendType" SG_ 544 SGU31_Msg_CheckSum_Can03 10;
BA_ "GenSigTimeoutValue" SG_ 544 SGU31_Msg_CheckSum_Can03 0;
BA_ "IsCrcSignal" SG_ 544 SGU31_Msg_CheckSum_Can03 1;
BA_ "EventCommandSignal" SG_ 544 SGU31_ObjRCS_31_Can03 0;
BA_ "GatewayedSignals" SG_ 544 SGU31_ObjRCS_31_Can03 0;
BA_ "GenSigInvalidValue" SG_ 544 SGU31_ObjRCS_31_Can03 0;
BA_ "GenSigSendType" SG_ 544 SGU31_ObjRCS_31_Can03 10;
BA_ "GenSigTimeoutValue" SG_ 544 SGU31_ObjRCS_31_Can03 0;
BA_ "EventCommandSignal" SG_ 544 SGU31_Obj_DistLat_rms_Can03 0;
BA_ "GatewayedSignals" SG_ 544 SGU31_Obj_DistLat_rms_Can03 0;
BA_ "GenSigInvalidValue" SG_ 544 SGU31_Obj_DistLat_rms_Can03 0;
BA_ "GenSigSendType" SG_ 544 SGU31_Obj_DistLat_rms_Can03 10;
BA_ "GenSigTimeoutValue" SG_ 544 SGU31_Obj_DistLat_rms_Can03 0;
BA_ "EventCommandSignal" SG_ 544 SGU31_Obj_VrelLong_rms_Can03 0;
BA_ "GatewayedSignals" SG_ 544 SGU31_Obj_VrelLong_rms_Can03 0;
BA_ "GenSigInvalidValue" SG_ 544 SGU31_Obj_VrelLong_rms_Can03 0;
BA_ "GenSigSendType" SG_ 544 SGU31_Obj_VrelLong_rms_Can03 10;
BA_ "GenSigTimeoutValue" SG_ 544 SGU31_Obj_VrelLong_rms_Can03 0;
BA_ "EventCommandSignal" SG_ 544 SGU31_Obj_Vrelat_rms_Can03 0;
BA_ "GatewayedSignals" SG_ 544 SGU31_Obj_Vrelat_rms_Can03 0;
BA_ "GenSigInvalidValue" SG_ 544 SGU31_Obj_Vrelat_rms_Can03 0;
BA_ "GenSigSendType" SG_ 544 SGU31_Obj_Vrelat_rms_Can03 10;
BA_ "GenSigTimeoutValue" SG_ 544 SGU31_Obj_Vrelat_rms_Can03 0;
BA_ "EventCommandSignal" SG_ 544 SGU31_Object_DetStatus_Can03 0;
BA_ "GatewayedSignals" SG_ 544 SGU31_Object_DetStatus_Can03 0;
BA_ "GenSigInvalidValue" SG_ 544 SGU31_Object_DetStatus_Can03 0;
BA_ "GenSigSendType" SG_ 544 SGU31_Object_DetStatus_Can03 10;
BA_ "GenSigTimeoutValue" SG_ 544 SGU31_Object_DetStatus_Can03 0;
BA_ "EventCommandSignal" SG_ 544 SGU31_Object_DistLong_rms_Can03 0;
BA_ "GatewayedSignals" SG_ 544 SGU31_Object_DistLong_rms_Can03 0;
BA_ "GenSigInvalidValue" SG_ 544 SGU31_Object_DistLong_rms_Can03 0;
BA_ "GenSigSendType" SG_ 544 SGU31_Object_DistLong_rms_Can03 10;
BA_ "GenSigTimeoutValue" SG_ 544 SGU31_Object_DistLong_rms_Can03 0;
BA_ "EventCommandSignal" SG_ 544 SGU31_Object_ID_Can03 0;
BA_ "GatewayedSignals" SG_ 544 SGU31_Object_ID_Can03 0;
BA_ "GenSigInvalidValue" SG_ 544 SGU31_Object_ID_Can03 0;
BA_ "GenSigSendType" SG_ 544 SGU31_Object_ID_Can03 10;
BA_ "GenSigTimeoutValue" SG_ 544 SGU31_Object_ID_Can03 0;
BA_ "EventCommandSignal" SG_ 544 SGU31_Object_MotionPattern_Can03 0;
BA_ "GatewayedSignals" SG_ 544 SGU31_Object_MotionPattern_Can03 0;
BA_ "GenSigInvalidValue" SG_ 544 SGU31_Object_MotionPattern_Can03 0;
BA_ "GenSigSendType" SG_ 544 SGU31_Object_MotionPattern_Can03 10;
BA_ "GenSigTimeoutValue" SG_ 544 SGU31_Object_MotionPattern_Can03 0;
BA_ "EventCommandSignal" SG_ 544 SGU31_Object_Type_Can03 0;
BA_ "GatewayedSignals" SG_ 544 SGU31_Object_Type_Can03 0;
BA_ "GenSigInvalidValue" SG_ 544 SGU31_Object_Type_Can03 0;
BA_ "GenSigSendType" SG_ 544 SGU31_Object_Type_Can03 10;
BA_ "GenSigTimeoutValue" SG_ 544 SGU31_Object_Type_Can03 0;
BA_ "EventCommandSignal" SG_ 544 SGU31_Object_ax_Can03 0;
BA_ "GatewayedSignals" SG_ 544 SGU31_Object_ax_Can03 0;
BA_ "GenSigInvalidValue" SG_ 544 SGU31_Object_ax_Can03 0;
BA_ "GenSigSendType" SG_ 544 SGU31_Object_ax_Can03 10;
BA_ "GenSigTimeoutValue" SG_ 544 SGU31_Object_ax_Can03 0;
BA_ "EventCommandSignal" SG_ 544 SGU31_Object_ay_Can03 0;
BA_ "GatewayedSignals" SG_ 544 SGU31_Object_ay_Can03 0;
BA_ "GenSigInvalidValue" SG_ 544 SGU31_Object_ay_Can03 0;
BA_ "GenSigSendType" SG_ 544 SGU31_Object_ay_Can03 10;
BA_ "GenSigTimeoutValue" SG_ 544 SGU31_Object_ay_Can03 0;
BA_ "EventCommandSignal" SG_ 544 SGU31_Object_dx_Nearest_Can03 0;
BA_ "GatewayedSignals" SG_ 544 SGU31_Object_dx_Nearest_Can03 0;
BA_ "GenSigInvalidValue" SG_ 544 SGU31_Object_dx_Nearest_Can03 0;
BA_ "GenSigSendType" SG_ 544 SGU31_Object_dx_Nearest_Can03 1;
BA_ "GenSigTimeoutValue" SG_ 544 SGU31_Object_dx_Nearest_Can03 0;
BA_ "EventCommandSignal" SG_ 544 SGU31_Object_dx_Rear_Can03 0;
BA_ "GatewayedSignals" SG_ 544 SGU31_Object_dx_Rear_Can03 0;
BA_ "GenSigInvalidValue" SG_ 544 SGU31_Object_dx_Rear_Can03 0;
BA_ "GenSigSendType" SG_ 544 SGU31_Object_dx_Rear_Can03 10;
BA_ "GenSigTimeoutValue" SG_ 544 SGU31_Object_dx_Rear_Can03 0;
BA_ "EventCommandSignal" SG_ 544 SGU31_Object_dy_Nearest_Can03 0;
BA_ "GatewayedSignals" SG_ 544 SGU31_Object_dy_Nearest_Can03 0;
BA_ "GenSigInvalidValue" SG_ 544 SGU31_Object_dy_Nearest_Can03 0;
BA_ "GenSigSendType" SG_ 544 SGU31_Object_dy_Nearest_Can03 1;
BA_ "GenSigTimeoutValue" SG_ 544 SGU31_Object_dy_Nearest_Can03 0;
BA_ "EventCommandSignal" SG_ 544 SGU31_Object_dy_Rear_Can03 0;
BA_ "GatewayedSignals" SG_ 544 SGU31_Object_dy_Rear_Can03 0;
BA_ "GenSigInvalidValue" SG_ 544 SGU31_Object_dy_Rear_Can03 0;
BA_ "GenSigSendType" SG_ 544 SGU31_Object_dy_Rear_Can03 10;
BA_ "GenSigTimeoutValue" SG_ 544 SGU31_Object_dy_Rear_Can03 0;
BA_ "EventCommandSignal" SG_ 544 SGU31_Object_vx_Can03 0;
BA_ "GatewayedSignals" SG_ 544 SGU31_Object_vx_Can03 0;
BA_ "GenSigInvalidValue" SG_ 544 SGU31_Object_vx_Can03 0;
BA_ "GenSigSendType" SG_ 544 SGU31_Object_vx_Can03 10;
BA_ "GenSigTimeoutValue" SG_ 544 SGU31_Object_vx_Can03 0;
BA_ "EventCommandSignal" SG_ 544 SGU31_Object_vy_Can03 0;
BA_ "GatewayedSignals" SG_ 544 SGU31_Object_vy_Can03 0;
BA_ "GenSigInvalidValue" SG_ 544 SGU31_Object_vy_Can03 0;
BA_ "GenSigSendType" SG_ 544 SGU31_Object_vy_Can03 10;
BA_ "GenSigTimeoutValue" SG_ 544 SGU31_Object_vy_Can03 0;
BA_ "EventCommandSignal" SG_ 544 SGU31_Object_wExist_Can03 0;
BA_ "GatewayedSignals" SG_ 544 SGU31_Object_wExist_Can03 0;
BA_ "GenSigInvalidValue" SG_ 544 SGU31_Object_wExist_Can03 0;
BA_ "GenSigSendType" SG_ 544 SGU31_Object_wExist_Can03 10;
BA_ "GenSigTimeoutValue" SG_ 544 SGU31_Object_wExist_Can03 0;
BA_ "EventCommandSignal" SG_ 544 SGU31_Object_wObstacle_Can03 0;
BA_ "GatewayedSignals" SG_ 544 SGU31_Object_wObstacle_Can03 0;
BA_ "GenSigInvalidValue" SG_ 544 SGU31_Object_wObstacle_Can03 0;
BA_ "GenSigSendType" SG_ 544 SGU31_Object_wObstacle_Can03 10;
BA_ "GenSigTimeoutValue" SG_ 544 SGU31_Object_wObstacle_Can03 0;
BA_ "EventCommandSignal" SG_ 545 SGU32_BlockCounter_Can03 0;
BA_ "GatewayedSignals" SG_ 545 SGU32_BlockCounter_Can03 0;
BA_ "GenSigInvalidValue" SG_ 545 SGU32_BlockCounter_Can03 0;
BA_ "GenSigSendType" SG_ 545 SGU32_BlockCounter_Can03 10;
BA_ "GenSigTimeoutValue" SG_ 545 SGU32_BlockCounter_Can03 0;
BA_ "EventCommandSignal" SG_ 545 SGU32_LifeCycles_OBJ_Can03 0;
BA_ "GatewayedSignals" SG_ 545 SGU32_LifeCycles_OBJ_Can03 0;
BA_ "GenSigInvalidValue" SG_ 545 SGU32_LifeCycles_OBJ_Can03 0;
BA_ "GenSigSendType" SG_ 545 SGU32_LifeCycles_OBJ_Can03 10;
BA_ "GenSigTimeoutValue" SG_ 545 SGU32_LifeCycles_OBJ_Can03 0;
BA_ "EventCommandSignal" SG_ 545 SGU32_Msg_AliveCounter_Can03 0;
BA_ "GatewayedSignals" SG_ 545 SGU32_Msg_AliveCounter_Can03 0;
BA_ "GenSigInvalidValue" SG_ 545 SGU32_Msg_AliveCounter_Can03 0;
BA_ "GenSigSendType" SG_ 545 SGU32_Msg_AliveCounter_Can03 10;
BA_ "GenSigTimeoutValue" SG_ 545 SGU32_Msg_AliveCounter_Can03 0;
BA_ "EventCommandSignal" SG_ 545 SGU32_Msg_CheckSum_Can03 0;
BA_ "GatewayedSignals" SG_ 545 SGU32_Msg_CheckSum_Can03 0;
BA_ "GenSigInvalidValue" SG_ 545 SGU32_Msg_CheckSum_Can03 0;
BA_ "GenSigSendType" SG_ 545 SGU32_Msg_CheckSum_Can03 10;
BA_ "GenSigTimeoutValue" SG_ 545 SGU32_Msg_CheckSum_Can03 0;
BA_ "IsCrcSignal" SG_ 545 SGU32_Msg_CheckSum_Can03 1;
BA_ "EventCommandSignal" SG_ 545 SGU32_ObjRCS_32_Can03 0;
BA_ "GatewayedSignals" SG_ 545 SGU32_ObjRCS_32_Can03 0;
BA_ "GenSigInvalidValue" SG_ 545 SGU32_ObjRCS_32_Can03 0;
BA_ "GenSigSendType" SG_ 545 SGU32_ObjRCS_32_Can03 10;
BA_ "GenSigTimeoutValue" SG_ 545 SGU32_ObjRCS_32_Can03 0;
BA_ "EventCommandSignal" SG_ 545 SGU32_Obj_DistLat_rms_Can03 0;
BA_ "GatewayedSignals" SG_ 545 SGU32_Obj_DistLat_rms_Can03 0;
BA_ "GenSigInvalidValue" SG_ 545 SGU32_Obj_DistLat_rms_Can03 0;
BA_ "GenSigSendType" SG_ 545 SGU32_Obj_DistLat_rms_Can03 10;
BA_ "GenSigTimeoutValue" SG_ 545 SGU32_Obj_DistLat_rms_Can03 0;
BA_ "EventCommandSignal" SG_ 545 SGU32_Obj_VrelLong_rms_Can03 0;
BA_ "GatewayedSignals" SG_ 545 SGU32_Obj_VrelLong_rms_Can03 0;
BA_ "GenSigInvalidValue" SG_ 545 SGU32_Obj_VrelLong_rms_Can03 0;
BA_ "GenSigSendType" SG_ 545 SGU32_Obj_VrelLong_rms_Can03 10;
BA_ "GenSigTimeoutValue" SG_ 545 SGU32_Obj_VrelLong_rms_Can03 0;
BA_ "EventCommandSignal" SG_ 545 SGU32_Obj_Vrelat_rms_Can03 0;
BA_ "GatewayedSignals" SG_ 545 SGU32_Obj_Vrelat_rms_Can03 0;
BA_ "GenSigInvalidValue" SG_ 545 SGU32_Obj_Vrelat_rms_Can03 0;
BA_ "GenSigSendType" SG_ 545 SGU32_Obj_Vrelat_rms_Can03 10;
BA_ "GenSigTimeoutValue" SG_ 545 SGU32_Obj_Vrelat_rms_Can03 0;
BA_ "EventCommandSignal" SG_ 545 SGU32_Object_DetStatus_Can03 0;
BA_ "GatewayedSignals" SG_ 545 SGU32_Object_DetStatus_Can03 0;
BA_ "GenSigInvalidValue" SG_ 545 SGU32_Object_DetStatus_Can03 0;
BA_ "GenSigSendType" SG_ 545 SGU32_Object_DetStatus_Can03 10;
BA_ "GenSigTimeoutValue" SG_ 545 SGU32_Object_DetStatus_Can03 0;
BA_ "EventCommandSignal" SG_ 545 SGU32_Object_DistLong_rms_Can03 0;
BA_ "GatewayedSignals" SG_ 545 SGU32_Object_DistLong_rms_Can03 0;
BA_ "GenSigInvalidValue" SG_ 545 SGU32_Object_DistLong_rms_Can03 0;
BA_ "GenSigSendType" SG_ 545 SGU32_Object_DistLong_rms_Can03 10;
BA_ "GenSigTimeoutValue" SG_ 545 SGU32_Object_DistLong_rms_Can03 0;
BA_ "EventCommandSignal" SG_ 545 SGU32_Object_ID_Can03 0;
BA_ "GatewayedSignals" SG_ 545 SGU32_Object_ID_Can03 0;
BA_ "GenSigInvalidValue" SG_ 545 SGU32_Object_ID_Can03 0;
BA_ "GenSigSendType" SG_ 545 SGU32_Object_ID_Can03 10;
BA_ "GenSigTimeoutValue" SG_ 545 SGU32_Object_ID_Can03 0;
BA_ "EventCommandSignal" SG_ 545 SGU32_Object_MotionPattern_Can03 0;
BA_ "GatewayedSignals" SG_ 545 SGU32_Object_MotionPattern_Can03 0;
BA_ "GenSigInvalidValue" SG_ 545 SGU32_Object_MotionPattern_Can03 0;
BA_ "GenSigSendType" SG_ 545 SGU32_Object_MotionPattern_Can03 10;
BA_ "GenSigTimeoutValue" SG_ 545 SGU32_Object_MotionPattern_Can03 0;
BA_ "EventCommandSignal" SG_ 545 SGU32_Object_Type_Can03 0;
BA_ "GatewayedSignals" SG_ 545 SGU32_Object_Type_Can03 0;
BA_ "GenSigInvalidValue" SG_ 545 SGU32_Object_Type_Can03 0;
BA_ "GenSigSendType" SG_ 545 SGU32_Object_Type_Can03 10;
BA_ "GenSigTimeoutValue" SG_ 545 SGU32_Object_Type_Can03 0;
BA_ "EventCommandSignal" SG_ 545 SGU32_Object_ax_Can03 0;
BA_ "GatewayedSignals" SG_ 545 SGU32_Object_ax_Can03 0;
BA_ "GenSigInvalidValue" SG_ 545 SGU32_Object_ax_Can03 0;
BA_ "GenSigSendType" SG_ 545 SGU32_Object_ax_Can03 10;
BA_ "GenSigTimeoutValue" SG_ 545 SGU32_Object_ax_Can03 0;
BA_ "EventCommandSignal" SG_ 545 SGU32_Object_ay_Can03 0;
BA_ "GatewayedSignals" SG_ 545 SGU32_Object_ay_Can03 0;
BA_ "GenSigInvalidValue" SG_ 545 SGU32_Object_ay_Can03 0;
BA_ "GenSigSendType" SG_ 545 SGU32_Object_ay_Can03 10;
BA_ "GenSigTimeoutValue" SG_ 545 SGU32_Object_ay_Can03 0;
BA_ "EventCommandSignal" SG_ 545 SGU32_Object_dx_Nearest_Can03 0;
BA_ "GatewayedSignals" SG_ 545 SGU32_Object_dx_Nearest_Can03 0;
BA_ "GenSigInvalidValue" SG_ 545 SGU32_Object_dx_Nearest_Can03 0;
BA_ "GenSigSendType" SG_ 545 SGU32_Object_dx_Nearest_Can03 1;
BA_ "GenSigTimeoutValue" SG_ 545 SGU32_Object_dx_Nearest_Can03 0;
BA_ "EventCommandSignal" SG_ 545 SGU32_Object_dx_Rear_Can03 0;
BA_ "GatewayedSignals" SG_ 545 SGU32_Object_dx_Rear_Can03 0;
BA_ "GenSigInvalidValue" SG_ 545 SGU32_Object_dx_Rear_Can03 0;
BA_ "GenSigSendType" SG_ 545 SGU32_Object_dx_Rear_Can03 10;
BA_ "GenSigTimeoutValue" SG_ 545 SGU32_Object_dx_Rear_Can03 0;
BA_ "EventCommandSignal" SG_ 545 SGU32_Object_dy_Nearest_Can03 0;
BA_ "GatewayedSignals" SG_ 545 SGU32_Object_dy_Nearest_Can03 0;
BA_ "GenSigInvalidValue" SG_ 545 SGU32_Object_dy_Nearest_Can03 0;
BA_ "GenSigSendType" SG_ 545 SGU32_Object_dy_Nearest_Can03 1;
BA_ "GenSigTimeoutValue" SG_ 545 SGU32_Object_dy_Nearest_Can03 0;
BA_ "EventCommandSignal" SG_ 545 SGU32_Object_dy_Rear_Can03 0;
BA_ "GatewayedSignals" SG_ 545 SGU32_Object_dy_Rear_Can03 0;
BA_ "GenSigInvalidValue" SG_ 545 SGU32_Object_dy_Rear_Can03 0;
BA_ "GenSigSendType" SG_ 545 SGU32_Object_dy_Rear_Can03 10;
BA_ "GenSigTimeoutValue" SG_ 545 SGU32_Object_dy_Rear_Can03 0;
BA_ "EventCommandSignal" SG_ 545 SGU32_Object_vx_Can03 0;
BA_ "GatewayedSignals" SG_ 545 SGU32_Object_vx_Can03 0;
BA_ "GenSigInvalidValue" SG_ 545 SGU32_Object_vx_Can03 0;
BA_ "GenSigSendType" SG_ 545 SGU32_Object_vx_Can03 10;
BA_ "GenSigTimeoutValue" SG_ 545 SGU32_Object_vx_Can03 0;
BA_ "EventCommandSignal" SG_ 545 SGU32_Object_vy_Can03 0;
BA_ "GatewayedSignals" SG_ 545 SGU32_Object_vy_Can03 0;
BA_ "GenSigInvalidValue" SG_ 545 SGU32_Object_vy_Can03 0;
BA_ "GenSigSendType" SG_ 545 SGU32_Object_vy_Can03 10;
BA_ "GenSigTimeoutValue" SG_ 545 SGU32_Object_vy_Can03 0;
BA_ "EventCommandSignal" SG_ 545 SGU32_Object_wExist_Can03 0;
BA_ "GatewayedSignals" SG_ 545 SGU32_Object_wExist_Can03 0;
BA_ "GenSigInvalidValue" SG_ 545 SGU32_Object_wExist_Can03 0;
BA_ "GenSigSendType" SG_ 545 SGU32_Object_wExist_Can03 10;
BA_ "GenSigTimeoutValue" SG_ 545 SGU32_Object_wExist_Can03 0;
BA_ "EventCommandSignal" SG_ 545 SGU32_Object_wObstacle_Can03 0;
BA_ "GatewayedSignals" SG_ 545 SGU32_Object_wObstacle_Can03 0;
BA_ "GenSigInvalidValue" SG_ 545 SGU32_Object_wObstacle_Can03 0;
BA_ "GenSigSendType" SG_ 545 SGU32_Object_wObstacle_Can03 10;
BA_ "GenSigTimeoutValue" SG_ 545 SGU32_Object_wObstacle_Can03 0;
BA_ "EventCommandSignal" SG_ 546 AngleEMEIndicatorAz 0;
BA_ "GatewayedSignals" SG_ 546 AngleEMEIndicatorAz 0;
BA_ "GenSigInvalidValue" SG_ 546 AngleEMEIndicatorAz 0;
BA_ "GenSigSendType" SG_ 546 AngleEMEIndicatorAz 1;
BA_ "GenSigTimeoutValue" SG_ 546 AngleEMEIndicatorAz 0;
BA_ "EventCommandSignal" SG_ 546 AngleEMEIndicatorEl 0;
BA_ "GatewayedSignals" SG_ 546 AngleEMEIndicatorEl 0;
BA_ "GenSigInvalidValue" SG_ 546 AngleEMEIndicatorEl 0;
BA_ "GenSigSendType" SG_ 546 AngleEMEIndicatorEl 1;
BA_ "GenSigTimeoutValue" SG_ 546 AngleEMEIndicatorEl 0;
BA_ "EventCommandSignal" SG_ 546 FR_Blindness_FaultSts_Can03 0;
BA_ "GatewayedSignals" SG_ 546 FR_Blindness_FaultSts_Can03 0;
BA_ "GenSigInvalidValue" SG_ 546 FR_Blindness_FaultSts_Can03 0;
BA_ "GenSigSendType" SG_ 546 FR_Blindness_FaultSts_Can03 1;
BA_ "GenSigTimeoutValue" SG_ 546 FR_Blindness_FaultSts_Can03 0;
BA_ "EventCommandSignal" SG_ 546 FR_DTC_ADC_TIME_SYNC_FAIL_Can03 0;
BA_ "GatewayedSignals" SG_ 546 FR_DTC_ADC_TIME_SYNC_FAIL_Can03 0;
BA_ "GenSigInvalidValue" SG_ 546 FR_DTC_ADC_TIME_SYNC_FAIL_Can03 0;
BA_ "GenSigSendType" SG_ 546 FR_DTC_ADC_TIME_SYNC_FAIL_Can03 1;
BA_ "GenSigTimeoutValue" SG_ 546 FR_DTC_ADC_TIME_SYNC_FAIL_Can03 0;
BA_ "EventCommandSignal" SG_ 546 FR_DTC_ALIGNMENT_NOT_DONE_Can03 0;
BA_ "GatewayedSignals" SG_ 546 FR_DTC_ALIGNMENT_NOT_DONE_Can03 0;
BA_ "GenSigInvalidValue" SG_ 546 FR_DTC_ALIGNMENT_NOT_DONE_Can03 0;
BA_ "GenSigSendType" SG_ 546 FR_DTC_ALIGNMENT_NOT_DONE_Can03 1;
BA_ "GenSigTimeoutValue" SG_ 546 FR_DTC_ALIGNMENT_NOT_DONE_Can03 0;
BA_ "EventCommandSignal" SG_ 546 FR_DTC_DSP_FAILURE_Can03 0;
BA_ "GatewayedSignals" SG_ 546 FR_DTC_DSP_FAILURE_Can03 0;
BA_ "GenSigInvalidValue" SG_ 546 FR_DTC_DSP_FAILURE_Can03 0;
BA_ "GenSigSendType" SG_ 546 FR_DTC_DSP_FAILURE_Can03 1;
BA_ "GenSigTimeoutValue" SG_ 546 FR_DTC_DSP_FAILURE_Can03 0;
BA_ "EventCommandSignal" SG_ 546 FR_DTC_HW_DEFECT_Can03 0;
BA_ "GatewayedSignals" SG_ 546 FR_DTC_HW_DEFECT_Can03 0;
BA_ "GenSigInvalidValue" SG_ 546 FR_DTC_HW_DEFECT_Can03 0;
BA_ "GenSigSendType" SG_ 546 FR_DTC_HW_DEFECT_Can03 1;
BA_ "GenSigTimeoutValue" SG_ 546 FR_DTC_HW_DEFECT_Can03 0;
BA_ "EventCommandSignal" SG_ 546 FR_DTC_INVALID_DATA_BCS_Can03 0;
BA_ "GatewayedSignals" SG_ 546 FR_DTC_INVALID_DATA_BCS_Can03 0;
BA_ "GenSigInvalidValue" SG_ 546 FR_DTC_INVALID_DATA_BCS_Can03 0;
BA_ "GenSigSendType" SG_ 546 FR_DTC_INVALID_DATA_BCS_Can03 1;
BA_ "GenSigTimeoutValue" SG_ 546 FR_DTC_INVALID_DATA_BCS_Can03 0;
BA_ "EventCommandSignal" SG_ 546 FR_DTC_INVALID_DATA_CCU_Can03 0;
BA_ "GatewayedSignals" SG_ 546 FR_DTC_INVALID_DATA_CCU_Can03 0;
BA_ "GenSigInvalidValue" SG_ 546 FR_DTC_INVALID_DATA_CCU_Can03 0;
BA_ "GenSigSendType" SG_ 546 FR_DTC_INVALID_DATA_CCU_Can03 1;
BA_ "GenSigTimeoutValue" SG_ 546 FR_DTC_INVALID_DATA_CCU_Can03 0;
BA_ "EventCommandSignal" SG_ 546 FR_DTC_INVALID_DATA_EPS_Can03 0;
BA_ "GatewayedSignals" SG_ 546 FR_DTC_INVALID_DATA_EPS_Can03 0;
BA_ "GenSigInvalidValue" SG_ 546 FR_DTC_INVALID_DATA_EPS_Can03 0;
BA_ "GenSigSendType" SG_ 546 FR_DTC_INVALID_DATA_EPS_Can03 1;
BA_ "GenSigTimeoutValue" SG_ 546 FR_DTC_INVALID_DATA_EPS_Can03 0;
BA_ "EventCommandSignal" SG_ 546 FR_DTC_INVALID_DATA_SOC_Can03 0;
BA_ "GatewayedSignals" SG_ 546 FR_DTC_INVALID_DATA_SOC_Can03 0;
BA_ "GenSigInvalidValue" SG_ 546 FR_DTC_INVALID_DATA_SOC_Can03 0;
BA_ "GenSigSendType" SG_ 546 FR_DTC_INVALID_DATA_SOC_Can03 1;
BA_ "GenSigTimeoutValue" SG_ 546 FR_DTC_INVALID_DATA_SOC_Can03 0;
BA_ "EventCommandSignal" SG_ 546 FR_DTC_LOST_COMM_BCS_Can03 0;
BA_ "GatewayedSignals" SG_ 546 FR_DTC_LOST_COMM_BCS_Can03 0;
BA_ "GenSigInvalidValue" SG_ 546 FR_DTC_LOST_COMM_BCS_Can03 0;
BA_ "GenSigSendType" SG_ 546 FR_DTC_LOST_COMM_BCS_Can03 1;
BA_ "GenSigTimeoutValue" SG_ 546 FR_DTC_LOST_COMM_BCS_Can03 0;
BA_ "EventCommandSignal" SG_ 546 FR_DTC_LOST_COMM_CCU_Can03 0;
BA_ "GatewayedSignals" SG_ 546 FR_DTC_LOST_COMM_CCU_Can03 0;
BA_ "GenSigInvalidValue" SG_ 546 FR_DTC_LOST_COMM_CCU_Can03 0;
BA_ "GenSigSendType" SG_ 546 FR_DTC_LOST_COMM_CCU_Can03 1;
BA_ "GenSigTimeoutValue" SG_ 546 FR_DTC_LOST_COMM_CCU_Can03 0;
BA_ "EventCommandSignal" SG_ 546 FR_DTC_LOST_COMM_EPS_Can03 0;
BA_ "GatewayedSignals" SG_ 546 FR_DTC_LOST_COMM_EPS_Can03 0;
BA_ "GenSigInvalidValue" SG_ 546 FR_DTC_LOST_COMM_EPS_Can03 0;
BA_ "GenSigSendType" SG_ 546 FR_DTC_LOST_COMM_EPS_Can03 1;
BA_ "GenSigTimeoutValue" SG_ 546 FR_DTC_LOST_COMM_EPS_Can03 0;
BA_ "EventCommandSignal" SG_ 546 FR_DTC_LOST_COMM_SOC_Can03 0;
BA_ "GatewayedSignals" SG_ 546 FR_DTC_LOST_COMM_SOC_Can03 0;
BA_ "GenSigInvalidValue" SG_ 546 FR_DTC_LOST_COMM_SOC_Can03 0;
BA_ "GenSigSendType" SG_ 546 FR_DTC_LOST_COMM_SOC_Can03 1;
BA_ "GenSigTimeoutValue" SG_ 546 FR_DTC_LOST_COMM_SOC_Can03 0;
BA_ "EventCommandSignal" SG_ 546 FR_DTC_MRR_BLIND_Can03 0;
BA_ "GatewayedSignals" SG_ 546 FR_DTC_MRR_BLIND_Can03 0;
BA_ "GenSigInvalidValue" SG_ 546 FR_DTC_MRR_BLIND_Can03 0;
BA_ "GenSigSendType" SG_ 546 FR_DTC_MRR_BLIND_Can03 1;
BA_ "GenSigTimeoutValue" SG_ 546 FR_DTC_MRR_BLIND_Can03 0;
BA_ "EventCommandSignal" SG_ 546 FR_DTC_MRR_MISALIGNED_Can03 0;
BA_ "GatewayedSignals" SG_ 546 FR_DTC_MRR_MISALIGNED_Can03 0;
BA_ "GenSigInvalidValue" SG_ 546 FR_DTC_MRR_MISALIGNED_Can03 0;
BA_ "GenSigSendType" SG_ 546 FR_DTC_MRR_MISALIGNED_Can03 1;
BA_ "GenSigTimeoutValue" SG_ 546 FR_DTC_MRR_MISALIGNED_Can03 0;
BA_ "EventCommandSignal" SG_ 546 FR_DTC_PCAN_BUSOFF_Can03 0;
BA_ "GatewayedSignals" SG_ 546 FR_DTC_PCAN_BUSOFF_Can03 0;
BA_ "GenSigInvalidValue" SG_ 546 FR_DTC_PCAN_BUSOFF_Can03 0;
BA_ "GenSigSendType" SG_ 546 FR_DTC_PCAN_BUSOFF_Can03 1;
BA_ "GenSigTimeoutValue" SG_ 546 FR_DTC_PCAN_BUSOFF_Can03 0;
BA_ "EventCommandSignal" SG_ 546 FR_DTC_RADAR_SIDE_MISMATCH_Can03 0;
BA_ "GatewayedSignals" SG_ 546 FR_DTC_RADAR_SIDE_MISMATCH_Can03 0;
BA_ "GenSigInvalidValue" SG_ 546 FR_DTC_RADAR_SIDE_MISMATCH_Can03 0;
BA_ "GenSigSendType" SG_ 546 FR_DTC_RADAR_SIDE_MISMATCH_Can03 1;
BA_ "GenSigTimeoutValue" SG_ 546 FR_DTC_RADAR_SIDE_MISMATCH_Can03 0;
BA_ "EventCommandSignal" SG_ 546 FR_DTC_VBAT_HIGH_Can03 0;
BA_ "GatewayedSignals" SG_ 546 FR_DTC_VBAT_HIGH_Can03 0;
BA_ "GenSigInvalidValue" SG_ 546 FR_DTC_VBAT_HIGH_Can03 0;
BA_ "GenSigSendType" SG_ 546 FR_DTC_VBAT_HIGH_Can03 1;
BA_ "GenSigTimeoutValue" SG_ 546 FR_DTC_VBAT_HIGH_Can03 0;
BA_ "EventCommandSignal" SG_ 546 FR_DTC_VBAT_LOW_Can03 0;
BA_ "GatewayedSignals" SG_ 546 FR_DTC_VBAT_LOW_Can03 0;
BA_ "GenSigInvalidValue" SG_ 546 FR_DTC_VBAT_LOW_Can03 0;
BA_ "GenSigSendType" SG_ 546 FR_DTC_VBAT_LOW_Can03 1;
BA_ "GenSigTimeoutValue" SG_ 546 FR_DTC_VBAT_LOW_Can03 0;
BA_ "EventCommandSignal" SG_ 546 FR_DTC_VMC_FAILURE_Can03 0;
BA_ "GatewayedSignals" SG_ 546 FR_DTC_VMC_FAILURE_Can03 0;
BA_ "GenSigInvalidValue" SG_ 546 FR_DTC_VMC_FAILURE_Can03 0;
BA_ "GenSigSendType" SG_ 546 FR_DTC_VMC_FAILURE_Can03 1;
BA_ "GenSigTimeoutValue" SG_ 546 FR_DTC_VMC_FAILURE_Can03 0;
BA_ "EventCommandSignal" SG_ 546 FR_EOL_CalibrationSts_Can03 0;
BA_ "GatewayedSignals" SG_ 546 FR_EOL_CalibrationSts_Can03 0;
BA_ "GenSigInvalidValue" SG_ 546 FR_EOL_CalibrationSts_Can03 0;
BA_ "GenSigSendType" SG_ 546 FR_EOL_CalibrationSts_Can03 1;
BA_ "GenSigStartValue" SG_ 546 FR_EOL_CalibrationSts_Can03 255;
BA_ "GenSigTimeoutValue" SG_ 546 FR_EOL_CalibrationSts_Can03 0;
BA_ "EventCommandSignal" SG_ 546 FR_FAULT_HV_SERVICE_OOS_Can03 0;
BA_ "GatewayedSignals" SG_ 546 FR_FAULT_HV_SERVICE_OOS_Can03 0;
BA_ "GenSigInvalidValue" SG_ 546 FR_FAULT_HV_SERVICE_OOS_Can03 0;
BA_ "GenSigSendType" SG_ 546 FR_FAULT_HV_SERVICE_OOS_Can03 1;
BA_ "GenSigTimeoutValue" SG_ 546 FR_FAULT_HV_SERVICE_OOS_Can03 0;
BA_ "EventCommandSignal" SG_ 546 FR_Misalignment_FaultSts_Can03 0;
BA_ "GatewayedSignals" SG_ 546 FR_Misalignment_FaultSts_Can03 0;
BA_ "GenSigInvalidValue" SG_ 546 FR_Misalignment_FaultSts_Can03 0;
BA_ "GenSigSendType" SG_ 546 FR_Misalignment_FaultSts_Can03 1;
BA_ "GenSigTimeoutValue" SG_ 546 FR_Misalignment_FaultSts_Can03 0;
BA_ "EventCommandSignal" SG_ 546 FR_ModulationSts_Can03 0;
BA_ "GatewayedSignals" SG_ 546 FR_ModulationSts_Can03 0;
BA_ "GenSigInvalidValue" SG_ 546 FR_ModulationSts_Can03 0;
BA_ "GenSigSendType" SG_ 546 FR_ModulationSts_Can03 1;
BA_ "GenSigTimeoutValue" SG_ 546 FR_ModulationSts_Can03 0;
BA_ "EventCommandSignal" SG_ 546 FR_RadarInfor_AliveCounter_Can03 0;
BA_ "GatewayedSignals" SG_ 546 FR_RadarInfor_AliveCounter_Can03 0;
BA_ "GenSigInvalidValue" SG_ 546 FR_RadarInfor_AliveCounter_Can03 0;
BA_ "GenSigSendType" SG_ 546 FR_RadarInfor_AliveCounter_Can03 1;
BA_ "GenSigTimeoutValue" SG_ 546 FR_RadarInfor_AliveCounter_Can03 0;
BA_ "EventCommandSignal" SG_ 546 FR_RadarInfor_Checksum_Can03 0;
BA_ "GatewayedSignals" SG_ 546 FR_RadarInfor_Checksum_Can03 0;
BA_ "GenSigInvalidValue" SG_ 546 FR_RadarInfor_Checksum_Can03 0;
BA_ "GenSigSendType" SG_ 546 FR_RadarInfor_Checksum_Can03 1;
BA_ "GenSigTimeoutValue" SG_ 546 FR_RadarInfor_Checksum_Can03 0;
BA_ "IsCrcSignal" SG_ 546 FR_RadarInfor_Checksum_Can03 1;
BA_ "EventCommandSignal" SG_ 546 FR_Radar_FaultSts_Can03 0;
BA_ "GatewayedSignals" SG_ 546 FR_Radar_FaultSts_Can03 0;
BA_ "GenSigInvalidValue" SG_ 546 FR_Radar_FaultSts_Can03 0;
BA_ "GenSigSendType" SG_ 546 FR_Radar_FaultSts_Can03 1;
BA_ "GenSigTimeoutValue" SG_ 546 FR_Radar_FaultSts_Can03 0;
BA_ "EventCommandSignal" SG_ 546 FR_SDA_CalibrationSts_Can03 0;
BA_ "GatewayedSignals" SG_ 546 FR_SDA_CalibrationSts_Can03 0;
BA_ "GenSigInvalidValue" SG_ 546 FR_SDA_CalibrationSts_Can03 0;
BA_ "GenSigSendType" SG_ 546 FR_SDA_CalibrationSts_Can03 1;
BA_ "GenSigStartValue" SG_ 546 FR_SDA_CalibrationSts_Can03 255;
BA_ "GenSigTimeoutValue" SG_ 546 FR_SDA_CalibrationSts_Can03 0;
BA_ "EventCommandSignal" SG_ 546 FR_SW_Baseline_Can03 0;
BA_ "GatewayedSignals" SG_ 546 FR_SW_Baseline_Can03 0;
BA_ "GenSigInvalidValue" SG_ 546 FR_SW_Baseline_Can03 0;
BA_ "GenSigSendType" SG_ 546 FR_SW_Baseline_Can03 1;
BA_ "GenSigTimeoutValue" SG_ 546 FR_SW_Baseline_Can03 0;
BA_ "EventCommandSignal" SG_ 546 FR_SW_MajorVersion_Can03 0;
BA_ "GatewayedSignals" SG_ 546 FR_SW_MajorVersion_Can03 0;
BA_ "GenSigInvalidValue" SG_ 546 FR_SW_MajorVersion_Can03 0;
BA_ "GenSigSendType" SG_ 546 FR_SW_MajorVersion_Can03 1;
BA_ "GenSigTimeoutValue" SG_ 546 FR_SW_MajorVersion_Can03 0;
BA_ "EventCommandSignal" SG_ 546 FR_SW_MinorVersion_Can03 0;
BA_ "GatewayedSignals" SG_ 546 FR_SW_MinorVersion_Can03 0;
BA_ "GenSigInvalidValue" SG_ 546 FR_SW_MinorVersion_Can03 0;
BA_ "GenSigSendType" SG_ 546 FR_SW_MinorVersion_Can03 1;
BA_ "GenSigTimeoutValue" SG_ 546 FR_SW_MinorVersion_Can03 0;
BA_ "EventCommandSignal" SG_ 546 FR_SW_ReleaseType_Can03 0;
BA_ "GatewayedSignals" SG_ 546 FR_SW_ReleaseType_Can03 0;
BA_ "GenSigInvalidValue" SG_ 546 FR_SW_ReleaseType_Can03 0;
BA_ "GenSigSendType" SG_ 546 FR_SW_ReleaseType_Can03 1;
BA_ "GenSigTimeoutValue" SG_ 546 FR_SW_ReleaseType_Can03 0;
BA_ "EventCommandSignal" SG_ 546 Fault_MAL_HOR_ABS_EVENT 0;
BA_ "GatewayedSignals" SG_ 546 Fault_MAL_HOR_ABS_EVENT 0;
BA_ "GenSigInvalidValue" SG_ 546 Fault_MAL_HOR_ABS_EVENT 0;
BA_ "GenSigSendType" SG_ 546 Fault_MAL_HOR_ABS_EVENT 1;
BA_ "GenSigTimeoutValue" SG_ 546 Fault_MAL_HOR_ABS_EVENT 0;
BA_ "EventCommandSignal" SG_ 546 Fault_MAL_HOR_REL_EVENT 0;
BA_ "GatewayedSignals" SG_ 546 Fault_MAL_HOR_REL_EVENT 0;
BA_ "GenSigInvalidValue" SG_ 546 Fault_MAL_HOR_REL_EVENT 0;
BA_ "GenSigSendType" SG_ 546 Fault_MAL_HOR_REL_EVENT 1;
BA_ "GenSigTimeoutValue" SG_ 546 Fault_MAL_HOR_REL_EVENT 0;
BA_ "EventCommandSignal" SG_ 546 Fault_MAL_VER_ABS_EVENT 0;
BA_ "GatewayedSignals" SG_ 546 Fault_MAL_VER_ABS_EVENT 0;
BA_ "GenSigInvalidValue" SG_ 546 Fault_MAL_VER_ABS_EVENT 0;
BA_ "GenSigSendType" SG_ 546 Fault_MAL_VER_ABS_EVENT 1;
BA_ "GenSigTimeoutValue" SG_ 546 Fault_MAL_VER_ABS_EVENT 0;
BA_ "EventCommandSignal" SG_ 546 Fault_MAL_VER_REL_EVENT 0;
BA_ "GatewayedSignals" SG_ 546 Fault_MAL_VER_REL_EVENT 0;
BA_ "GenSigInvalidValue" SG_ 546 Fault_MAL_VER_REL_EVENT 0;
BA_ "GenSigSendType" SG_ 546 Fault_MAL_VER_REL_EVENT 1;
BA_ "GenSigTimeoutValue" SG_ 546 Fault_MAL_VER_REL_EVENT 0;
BA_ "EventCommandSignal" SG_ 546 FilteredPhiSpread 0;
BA_ "GatewayedSignals" SG_ 546 FilteredPhiSpread 0;
BA_ "GenSigInvalidValue" SG_ 546 FilteredPhiSpread 0;
BA_ "GenSigSendType" SG_ 546 FilteredPhiSpread 1;
BA_ "GenSigTimeoutValue" SG_ 546 FilteredPhiSpread 0;
BA_ "EventCommandSignal" SG_ 546 azOutOfProfileCause 0;
BA_ "GatewayedSignals" SG_ 546 azOutOfProfileCause 0;
BA_ "GenSigInvalidValue" SG_ 546 azOutOfProfileCause 0;
BA_ "GenSigSendType" SG_ 546 azOutOfProfileCause 1;
BA_ "GenSigTimeoutValue" SG_ 546 azOutOfProfileCause 0;
BA_ "EventCommandSignal" SG_ 546 azOutOfSpecCause 0;
BA_ "GatewayedSignals" SG_ 546 azOutOfSpecCause 0;
BA_ "GenSigInvalidValue" SG_ 546 azOutOfSpecCause 0;
BA_ "GenSigSendType" SG_ 546 azOutOfSpecCause 1;
BA_ "GenSigTimeoutValue" SG_ 546 azOutOfSpecCause 0;
BA_ "EventCommandSignal" SG_ 546 elOutOfProfileCause 0;
BA_ "GatewayedSignals" SG_ 546 elOutOfProfileCause 0;
BA_ "GenSigInvalidValue" SG_ 546 elOutOfProfileCause 0;
BA_ "GenSigSendType" SG_ 546 elOutOfProfileCause 1;
BA_ "GenSigTimeoutValue" SG_ 546 elOutOfProfileCause 0;
BA_ "EventCommandSignal" SG_ 546 elOutOfSpecCause 0;
BA_ "GatewayedSignals" SG_ 546 elOutOfSpecCause 0;
BA_ "GenSigInvalidValue" SG_ 546 elOutOfSpecCause 0;
BA_ "GenSigSendType" SG_ 546 elOutOfSpecCause 1;
BA_ "GenSigTimeoutValue" SG_ 546 elOutOfSpecCause 0;
BA_ "EventCommandSignal" SG_ 546 highSpreadIndicator_az 0;
BA_ "GatewayedSignals" SG_ 546 highSpreadIndicator_az 0;
BA_ "GenSigInvalidValue" SG_ 546 highSpreadIndicator_az 0;
BA_ "GenSigSendType" SG_ 546 highSpreadIndicator_az 1;
BA_ "GenSigTimeoutValue" SG_ 546 highSpreadIndicator_az 0;
BA_ "EventCommandSignal" SG_ 546 highSpreadIndicator_el 0;
BA_ "GatewayedSignals" SG_ 546 highSpreadIndicator_el 0;
BA_ "GenSigInvalidValue" SG_ 546 highSpreadIndicator_el 0;
BA_ "GenSigSendType" SG_ 546 highSpreadIndicator_el 1;
BA_ "GenSigTimeoutValue" SG_ 546 highSpreadIndicator_el 0;
BA_ "EventCommandSignal" SG_ 546 malStablePosAz 0;
BA_ "GatewayedSignals" SG_ 546 malStablePosAz 0;
BA_ "GenSigInvalidValue" SG_ 546 malStablePosAz 0;
BA_ "GenSigSendType" SG_ 546 malStablePosAz 1;
BA_ "GenSigTimeoutValue" SG_ 546 malStablePosAz 0;
BA_ "EventCommandSignal" SG_ 546 malStablePosEl 0;
BA_ "GatewayedSignals" SG_ 546 malStablePosEl 0;
BA_ "GenSigInvalidValue" SG_ 546 malStablePosEl 0;
BA_ "GenSigSendType" SG_ 546 malStablePosEl 1;
BA_ "GenSigTimeoutValue" SG_ 546 malStablePosEl 0;
BA_ "EventCommandSignal" SG_ 546 mountAngleCurrent_az 0;
BA_ "GatewayedSignals" SG_ 546 mountAngleCurrent_az 0;
BA_ "GenSigInvalidValue" SG_ 546 mountAngleCurrent_az 0;
BA_ "GenSigSendType" SG_ 546 mountAngleCurrent_az 1;
BA_ "GenSigTimeoutValue" SG_ 546 mountAngleCurrent_az 0;
BA_ "EventCommandSignal" SG_ 546 mountAngleCurrent_el 0;
BA_ "GatewayedSignals" SG_ 546 mountAngleCurrent_el 0;
BA_ "GenSigInvalidValue" SG_ 546 mountAngleCurrent_el 0;
BA_ "GenSigSendType" SG_ 546 mountAngleCurrent_el 1;
BA_ "GenSigTimeoutValue" SG_ 546 mountAngleCurrent_el 0;
BA_ "EventCommandSignal" SG_ 546 mountAngleIndicator_az 0;
BA_ "GatewayedSignals" SG_ 546 mountAngleIndicator_az 0;
BA_ "GenSigInvalidValue" SG_ 546 mountAngleIndicator_az 0;
BA_ "GenSigSendType" SG_ 546 mountAngleIndicator_az 1;
BA_ "GenSigTimeoutValue" SG_ 546 mountAngleIndicator_az 0;
BA_ "EventCommandSignal" SG_ 546 mountAngleIndicator_el 0;
BA_ "GatewayedSignals" SG_ 546 mountAngleIndicator_el 0;
BA_ "GenSigInvalidValue" SG_ 546 mountAngleIndicator_el 0;
BA_ "GenSigSendType" SG_ 546 mountAngleIndicator_el 1;
BA_ "GenSigTimeoutValue" SG_ 546 mountAngleIndicator_el 0;
BA_ "EventCommandSignal" SG_ 616 Time_Day 0;
BA_ "GatewayedSignals" SG_ 616 Time_Day 0;
BA_ "GenSigInvalidValue" SG_ 616 Time_Day 0;
BA_ "GenSigSendType" SG_ 616 Time_Day 1;
BA_ "GenSigStartValue" SG_ 616 Time_Day 1;
BA_ "GenSigTimeoutValue" SG_ 616 Time_Day 0;
BA_ "EventCommandSignal" SG_ 616 Time_Hour 0;
BA_ "GatewayedSignals" SG_ 616 Time_Hour 0;
BA_ "GenSigInvalidValue" SG_ 616 Time_Hour 0;
BA_ "GenSigSendType" SG_ 616 Time_Hour 1;
BA_ "GenSigStartValue" SG_ 616 Time_Hour 1;
BA_ "GenSigTimeoutValue" SG_ 616 Time_Hour 0;
BA_ "EventCommandSignal" SG_ 616 Time_Min 0;
BA_ "GatewayedSignals" SG_ 616 Time_Min 0;
BA_ "GenSigInvalidValue" SG_ 616 Time_Min 0;
BA_ "GenSigSendType" SG_ 616 Time_Min 1;
BA_ "GenSigStartValue" SG_ 616 Time_Min 1;
BA_ "GenSigTimeoutValue" SG_ 616 Time_Min 0;
BA_ "EventCommandSignal" SG_ 616 Time_Month 0;
BA_ "GatewayedSignals" SG_ 616 Time_Month 0;
BA_ "GenSigInvalidValue" SG_ 616 Time_Month 0;
BA_ "GenSigSendType" SG_ 616 Time_Month 1;
BA_ "GenSigStartValue" SG_ 616 Time_Month 1;
BA_ "GenSigTimeoutValue" SG_ 616 Time_Month 0;
BA_ "EventCommandSignal" SG_ 616 Time_Sec 0;
BA_ "GatewayedSignals" SG_ 616 Time_Sec 0;
BA_ "GenSigInvalidValue" SG_ 616 Time_Sec 0;
BA_ "GenSigSendType" SG_ 616 Time_Sec 1;
BA_ "GenSigStartValue" SG_ 616 Time_Sec 1;
BA_ "GenSigTimeoutValue" SG_ 616 Time_Sec 0;
BA_ "EventCommandSignal" SG_ 616 Time_Year 0;
BA_ "GatewayedSignals" SG_ 616 Time_Year 0;
BA_ "GenSigInvalidValue" SG_ 616 Time_Year 0;
BA_ "GenSigSendType" SG_ 616 Time_Year 1;
BA_ "GenSigTimeoutValue" SG_ 616 Time_Year 0;
BA_ "EventCommandSignal" SG_ 616 UMM_UsageModeSt 0;
BA_ "GatewayedSignals" SG_ 616 UMM_UsageModeSt 0;
BA_ "GenSigInvalidValue" SG_ 616 UMM_UsageModeSt 0;
BA_ "GenSigSendType" SG_ 616 UMM_UsageModeSt 1;
BA_ "GenSigStartValue" SG_ 616 UMM_UsageModeSt 7;
BA_ "GenSigTimeoutValue" SG_ 616 UMM_UsageModeSt 0;
BA_ "EventCommandSignal" SG_ 768 SYNC_FC_CRC 0;
BA_ "GatewayedSignals" SG_ 768 SYNC_FC_CRC 0;
BA_ "GenSigInvalidValue" SG_ 768 SYNC_FC_CRC 0;
BA_ "GenSigSendType" SG_ 768 SYNC_FC_CRC 1;
BA_ "GenSigTimeoutValue" SG_ 768 SYNC_FC_CRC 0;
BA_ "EventCommandSignal" SG_ 768 SYNC_FC_OVS 0;
BA_ "GatewayedSignals" SG_ 768 SYNC_FC_OVS 0;
BA_ "GenSigInvalidValue" SG_ 768 SYNC_FC_OVS 0;
BA_ "GenSigSendType" SG_ 768 SYNC_FC_OVS 1;
BA_ "GenSigTimeoutValue" SG_ 768 SYNC_FC_OVS 0;
BA_ "EventCommandSignal" SG_ 768 SYNC_FC_Reserved 0;
BA_ "GatewayedSignals" SG_ 768 SYNC_FC_Reserved 0;
BA_ "GenSigInvalidValue" SG_ 768 SYNC_FC_Reserved 0;
BA_ "GenSigSendType" SG_ 768 SYNC_FC_Reserved 1;
BA_ "GenSigTimeoutValue" SG_ 768 SYNC_FC_Reserved 0;
BA_ "EventCommandSignal" SG_ 768 SYNC_FC_SGW 0;
BA_ "GatewayedSignals" SG_ 768 SYNC_FC_SGW 0;
BA_ "GenSigInvalidValue" SG_ 768 SYNC_FC_SGW 0;
BA_ "GenSigSendType" SG_ 768 SYNC_FC_SGW 1;
BA_ "GenSigTimeoutValue" SG_ 768 SYNC_FC_SGW 0;
BA_ "EventCommandSignal" SG_ 768 SYNC_FC_Sequencecnt 0;
BA_ "GatewayedSignals" SG_ 768 SYNC_FC_Sequencecnt 0;
BA_ "GenSigInvalidValue" SG_ 768 SYNC_FC_Sequencecnt 0;
BA_ "GenSigSendType" SG_ 768 SYNC_FC_Sequencecnt 1;
BA_ "GenSigTimeoutValue" SG_ 768 SYNC_FC_Sequencecnt 0;
BA_ "EventCommandSignal" SG_ 768 SYNC_FC_SyncTime 0;
BA_ "GatewayedSignals" SG_ 768 SYNC_FC_SyncTime 0;
BA_ "GenSigInvalidValue" SG_ 768 SYNC_FC_SyncTime 0;
BA_ "GenSigSendType" SG_ 768 SYNC_FC_SyncTime 1;
BA_ "GenSigTimeoutValue" SG_ 768 SYNC_FC_SyncTime 0;
BA_ "EventCommandSignal" SG_ 768 SYNC_FC_TimeDomain 0;
BA_ "GatewayedSignals" SG_ 768 SYNC_FC_TimeDomain 0;
BA_ "GenSigInvalidValue" SG_ 768 SYNC_FC_TimeDomain 0;
BA_ "GenSigSendType" SG_ 768 SYNC_FC_TimeDomain 1;
BA_ "GenSigTimeoutValue" SG_ 768 SYNC_FC_TimeDomain 0;
BA_ "EventCommandSignal" SG_ 768 SYNC_FC_Type 0;
BA_ "GatewayedSignals" SG_ 768 SYNC_FC_Type 0;
BA_ "GenSigInvalidValue" SG_ 768 SYNC_FC_Type 0;
BA_ "GenSigSendType" SG_ 768 SYNC_FC_Type 1;
BA_ "GenSigTimeoutValue" SG_ 768 SYNC_FC_Type 0;
BA_ "VFrameFormat" BO_ 1238 14;
BA_ "VFrameFormat" BO_ 1854 14;
BA_ "VFrameFormat" BO_ 1982 14;
BA_ "VFrameFormat" BO_ 2015 14;
BA_ "VFrameFormat" BO_ 537 14;
BA_ "VFrameFormat" BO_ 538 14;
BA_ "VFrameFormat" BO_ 539 14;
BA_ "VFrameFormat" BO_ 540 14;
BA_ "VFrameFormat" BO_ 541 14;
BA_ "VFrameFormat" BO_ 542 14;
BA_ "VFrameFormat" BO_ 543 14;
BA_ "VFrameFormat" BO_ 544 14;
BA_ "VFrameFormat" BO_ 545 14;
BA_ "VFrameFormat" BO_ 546 14;
BA_ "VFrameFormat" BO_ 616 14;
BA_ "VFrameFormat" BO_ 768 14;
VAL_ 537 SGU24_Object_DetStatus_Can03 0 "deleted" 1 "new" 2 "measured" 3 "predicted" 4 "deleted for merge" 5 "new from merge"  ;
VAL_ 537 SGU24_Object_MotionPattern_Can03 0 "Unknown" 1 "Stationary" 2 "Stopped" 3 "Moving"  ;
VAL_ 537 SGU24_Object_Type_Can03 0 "Unknown" 1 "4 wheeler" 2 "2 wheeler" 3 "Pedestrian"  ;
VAL_ 538 SGU25_Object_DetStatus_Can03 0 "deleted" 1 "new" 2 "measured" 3 "predicted" 4 "deleted for merge" 5 "new from merge"  ;
VAL_ 538 SGU25_Object_MotionPattern_Can03 0 "Unknown" 1 "Stationary" 2 "Stopped" 3 "Moving"  ;
VAL_ 538 SGU25_Object_Type_Can03 0 "Unknown" 1 "4 wheeler" 2 "2 wheeler" 3 "Pedestrian"  ;
VAL_ 539 SGU26_Object_DetStatus_Can03 0 "deleted" 1 "new" 2 "measured" 3 "predicted" 4 "deleted for merge" 5 "new from merge"  ;
VAL_ 539 SGU26_Object_MotionPattern_Can03 0 "Unknown" 1 "Stationary" 2 "Stopped" 3 "Moving"  ;
VAL_ 539 SGU26_Object_Type_Can03 0 "Unknown" 1 "4 wheeler" 2 "2 wheeler" 3 "Pedestrian"  ;
VAL_ 540 SGU27_Object_DetStatus_Can03 0 "deleted" 1 "new" 2 "measured" 3 "predicted" 4 "deleted for merge" 5 "new from merge"  ;
VAL_ 540 SGU27_Object_MotionPattern_Can03 0 "Unknown" 1 "Stationary" 2 "Stopped" 3 "Moving"  ;
VAL_ 540 SGU27_Object_Type_Can03 0 "Unknown" 1 "4 wheeler" 2 "2 wheeler" 3 "Pedestrian"  ;
VAL_ 541 SGU28_Object_DetStatus_Can03 0 "deleted" 1 "new" 2 "measured" 3 "predicted" 4 "deleted for merge" 5 "new from merge"  ;
VAL_ 541 SGU28_Object_MotionPattern_Can03 0 "Unknown" 1 "Stationary" 2 "Stopped" 3 "Moving"  ;
VAL_ 541 SGU28_Object_Type_Can03 0 "Unknown" 1 "4 wheeler" 2 "2 wheeler" 3 "Pedestrian"  ;
VAL_ 542 SGU29_Object_DetStatus_Can03 0 "deleted" 1 "new" 2 "measured" 3 "predicted" 4 "deleted for merge" 5 "new from merge"  ;
VAL_ 542 SGU29_Object_MotionPattern_Can03 0 "Unknown" 1 "Stationary" 2 "Stopped" 3 "Moving"  ;
VAL_ 542 SGU29_Object_Type_Can03 0 "Unknown" 1 "4 wheeler" 2 "2 wheeler" 3 "Pedestrian"  ;
VAL_ 543 SGU30_Object_DetStatus_Can03 0 "deleted" 1 "new" 2 "measured" 3 "predicted" 4 "deleted for merge" 5 "new from merge"  ;
VAL_ 543 SGU30_Object_MotionPattern_Can03 0 "Unknown" 1 "Stationary" 2 "Stopped" 3 "Moving"  ;
VAL_ 543 SGU30_Object_Type_Can03 0 "Unknown" 1 "4 wheeler" 2 "2 wheeler" 3 "Pedestrian"  ;
VAL_ 544 SGU31_Object_DetStatus_Can03 0 "deleted" 1 "new" 2 "measured" 3 "predicted" 4 "deleted for merge" 5 "new from merge"  ;
VAL_ 544 SGU31_Object_MotionPattern_Can03 0 "Unknown" 1 "Stationary" 2 "Stopped" 3 "Moving"  ;
VAL_ 544 SGU31_Object_Type_Can03 0 "Unknown" 1 "4 wheeler" 2 "2 wheeler" 3 "Pedestrian"  ;
VAL_ 545 SGU32_Object_DetStatus_Can03 0 "deleted" 1 "new" 2 "measured" 3 "predicted" 4 "deleted for merge" 5 "new from merge"  ;
VAL_ 545 SGU32_Object_MotionPattern_Can03 0 "Unknown" 1 "Stationary" 2 "Stopped" 3 "Moving"  ;
VAL_ 545 SGU32_Object_Type_Can03 0 "Unknown" 1 "4 wheeler" 2 "2 wheeler" 3 "Pedestrian"  ;
VAL_ 546 FR_Blindness_FaultSts_Can03 0 "No Blindness" 1 "Blindness"  ;
VAL_ 546 FR_DTC_ADC_TIME_SYNC_FAIL_Can03 0 "No Fail" 1 "Fail"  ;
VAL_ 546 FR_DTC_ALIGNMENT_NOT_DONE_Can03 0 "No Fail" 1 "Fail"  ;
VAL_ 546 FR_DTC_DSP_FAILURE_Can03 0 "No Fail" 1 "Fail"  ;
VAL_ 546 FR_DTC_HW_DEFECT_Can03 0 "No Fail" 1 "Fail"  ;
VAL_ 546 FR_DTC_INVALID_DATA_BCS_Can03 0 "No Fail" 1 "Fail"  ;
VAL_ 546 FR_DTC_INVALID_DATA_CCU_Can03 0 "No Fail" 1 "Fail"  ;
VAL_ 546 FR_DTC_INVALID_DATA_EPS_Can03 0 "No Fail" 1 "Fail"  ;
VAL_ 546 FR_DTC_INVALID_DATA_SOC_Can03 0 "No Fail" 1 "Fail"  ;
VAL_ 546 FR_DTC_LOST_COMM_BCS_Can03 0 "No Fail" 1 "Fail"  ;
VAL_ 546 FR_DTC_LOST_COMM_CCU_Can03 0 "No Fail" 1 "Fail"  ;
VAL_ 546 FR_DTC_LOST_COMM_EPS_Can03 0 "No Fail" 1 "Fail"  ;
VAL_ 546 FR_DTC_LOST_COMM_SOC_Can03 0 "No Fail" 1 "Fail"  ;
VAL_ 546 FR_DTC_MRR_BLIND_Can03 0 "No Fail" 1 "Fail"  ;
VAL_ 546 FR_DTC_MRR_MISALIGNED_Can03 0 "No Fail" 1 "Fail"  ;
VAL_ 546 FR_DTC_PCAN_BUSOFF_Can03 0 "No Fail" 1 "Fail"  ;
VAL_ 546 FR_DTC_RADAR_SIDE_MISMATCH_Can03 0 "No Fail" 1 "Fail"  ;
VAL_ 546 FR_DTC_VBAT_HIGH_Can03 0 "No Fail" 1 "Fail"  ;
VAL_ 546 FR_DTC_VBAT_LOW_Can03 0 "No Fail" 1 "Fail"  ;
VAL_ 546 FR_DTC_VMC_FAILURE_Can03 0 "No Fail" 1 "Fail"  ;
VAL_ 546 FR_EOL_CalibrationSts_Can03 0 "successfully calibrated" 1 "time out" 2 "target is missing" 3 "target distance is not correct" 4 "Horizontal bad angle" 5 "Vertical bad angle" 6 "NVM error" 7 "Cancelled by user" 255 "Not done calibration"  ;
VAL_ 546 FR_FAULT_HV_SERVICE_OOS_Can03 0 "No Fail" 1 "Fail"  ;
VAL_ 546 FR_Misalignment_FaultSts_Can03 0 "Aligned" 1 "Misaligned"  ;
VAL_ 546 FR_ModulationSts_Can03 0 "On" 1 "Off"  ;
VAL_ 546 FR_Radar_FaultSts_Can03 0 "No Fail" 1 "Fail" 0 "No Fail" 1 "Fail" 0 "No Fail" 1 "Fail" 0 "No Fail" 1 "Fail" 0 "No Fail" 1 "Fail"  ;
VAL_ 546 FR_SDA_CalibrationSts_Can03 0 "successfully calibrated" 1 "calibration is processing" 2 "calibration is failed" 3 "cancelled by user" 255 "routine not started"  ;
VAL_ 546 FR_SW_ReleaseType_Can03 0 "V(Version)" 1 "RC(Release Candidate)" 2 "LC (Local Release)"  ;
VAL_ 546 Fault_MAL_HOR_ABS_EVENT 0 "Not Fault" 1 "Fault"  ;
VAL_ 546 Fault_MAL_HOR_REL_EVENT 0 "Not Fault" 1 "Fault"  ;
VAL_ 546 Fault_MAL_VER_ABS_EVENT 0 "Not Fault" 1 "Fault"  ;
VAL_ 546 Fault_MAL_VER_REL_EVENT 0 "Not Fault" 1 "Fault"  ;
VAL_ 546 azOutOfProfileCause 0 "No Out" 1 "Out"  ;
VAL_ 546 azOutOfSpecCause 0 "No Out" 1 "Out"  ;
VAL_ 546 elOutOfProfileCause 0 "No Out" 1 "Out"  ;
VAL_ 546 elOutOfSpecCause 0 "No Out" 1 "Out"  ;
VAL_ 616 UMM_UsageModeSt 0 "Standby" 1 "Comfort" 2 "ToBeDRV(Reserved)" 3 "DRV" 7 "Invalid"  ;
